VERSION ""

NS_ :

BS_:

BU_: TBOX GW

BO_ 665 BCM_0x299_LIN2_3: 8 GW
 SG_ CSW_Key_StartStop : 1|2@0+ (1,0) [0|3] "" TBOX
 SG_ CSW_Key_AutoParking : 3|2@0+ (1,0) [0|3] "" TBOX
 SG_ CSW_Key_LiftGate : 5|2@0+ (1,0) [0|3] "" TBOX
 SG_ CSW_WindowLOCK : 7|2@0+ (1,0) [0|3] "" TBOX
 SG_ CSW_Key_FrontDefrost : 9|2@0+ (1,0) [0|3] "" TBOX
 SG_ ESCL_DiagError : 12|1@0+ (1,0) [0|1] "" TBOX
 SG_ ESCL_authentification_error : 13|1@0+ (1,0) [0|1] "" TBOX
 SG_ ESCL_unlock_status : 14|1@0+ (1,0) [0|1] "" TBOX
 SG_ ESCL_lock_status : 15|1@0+ (1,0) [0|1] "" TBOX
 SG_ FLWM_WinPstSt : 22|7@0+ (1,0) [0|100] "" TBOX
 SG_ FLWM_AntiPinchDetecte : 23|1@0+ (1,0) [0|1] "" TBOX
 SG_ FRWM_WinPstSt : 30|7@0+ (1,0) [0|100] "" TBOX
 SG_ FRWM_AntiPinchDetecte : 31|1@0+ (1,0) [0|1] "" TBOX
 SG_ RLWM_WinPstSt : 38|7@0+ (1,0) [0|100] "" TBOX
 SG_ RLWM_AntiPinchDetecte : 39|1@0+ (1,0) [0|1] "" TBOX
 SG_ RRWM_WinPstSt : 46|7@0+ (1,0) [0|100] "" TBOX
 SG_ RRWM_AntiPinchDetecte : 47|1@0+ (1,0) [0|1] "" TBOX
 SG_ FLWM_Opend : 48|1@0+ (1,0) [0|1] "" TBOX
 SG_ FLWM_Closed : 49|1@0+ (1,0) [0|1] "" TBOX
 SG_ FRWM_Opend : 50|1@0+ (1,0) [0|1] "" TBOX
 SG_ FRWM_Closed : 51|1@0+ (1,0) [0|1] "" TBOX
 SG_ RLWM_Opend : 52|1@0+ (1,0) [0|1] "" TBOX
 SG_ RLWM_Closed : 53|1@0+ (1,0) [0|1] "" TBOX
 SG_ RRWM_Opend : 54|1@0+ (1,0) [0|1] "" TBOX
 SG_ RRWM_Closed : 55|1@0+ (1,0) [0|1] "" TBOX
 SG_ FLWM_WinMoveSt : 57|2@0+ (1,0) [0|3] "" TBOX
 SG_ FRWM_WinMoveSt : 59|2@0+ (1,0) [0|3] "" TBOX
 SG_ RLWM_WinMoveSt : 61|2@0+ (1,0) [0|3] "" TBOX
 SG_ RRWM_WinMoveSt : 63|2@0+ (1,0) [0|3] "" TBOX

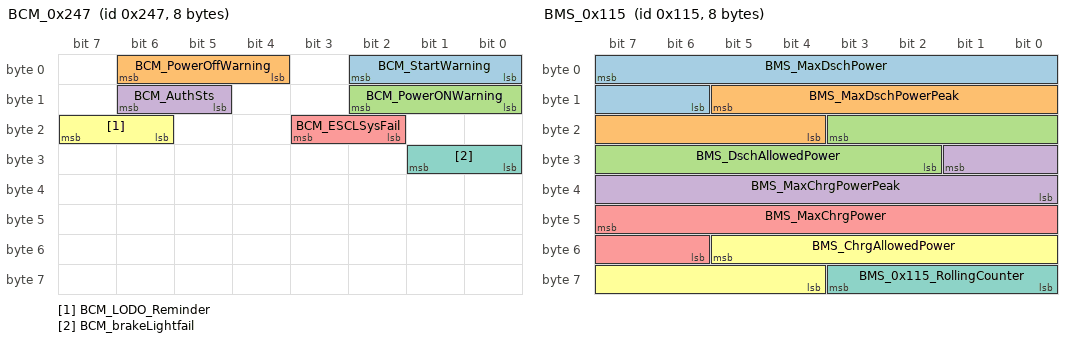
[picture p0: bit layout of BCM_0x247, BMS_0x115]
BO_ 583 BCM_0x247: 8 GW
 SG_ BCM_StartWarning : 2|3@0+ (1,0) [0|7] "" TBOX
 SG_ BCM_PowerOffWarning : 6|3@0+ (1,0) [0|7] "" TBOX
 SG_ BCM_PowerONWarning : 10|3@0+ (1,0) [0|7] "" TBOX
 SG_ BCM_AuthSts : 14|2@0+ (1,0) [0|3] "" TBOX
 SG_ BCM_ESCLSysFail : 19|2@0+ (1,0) [0|3] "" TBOX
 SG_ BCM_LODO_Reminder : 23|2@0+ (1,0) [0|3] "" TBOX
 SG_ BCM_brakeLightfail : 25|2@0+ (1,0) [0|3] "" TBOX

BO_ 1282 BCM_TPMS_0x502: 8 GW
 SG_ TPMS_FL_Warning_Sts : 0|1@0+ (1,0) [0|1] "" TBOX
 SG_ TPMS_FR_Warning_Sts : 1|1@0+ (1,0) [0|1] "" TBOX
 SG_ TPMS_RL_Warning_Sts : 2|1@0+ (1,0) [0|1] "" TBOX
 SG_ TPMS_RR_Warning_Sts : 3|1@0+ (1,0) [0|1] "" TBOX
 SG_ TPMS_FL_Fault_Sts : 4|1@0+ (1,0) [0|1] "" TBOX
 SG_ TPMS_FR_Fault_Sts : 5|1@0+ (1,0) [0|1] "" TBOX
 SG_ TPMS_RL_Fault_Sts : 6|1@0+ (1,0) [0|1] "" TBOX
 SG_ TPMS_RR_Fault_Sts : 7|1@0+ (1,0) [0|1] "" TBOX
 SG_ TPMS_FL_leakage_Sts : 8|1@0+ (1,0) [0|1] "" TBOX
 SG_ TPMS_FR_leakage_Sts : 9|1@0+ (1,0) [0|1] "" TBOX
 SG_ TPMS_RL_leakage_Sts : 10|1@0+ (1,0) [0|1] "" TBOX
 SG_ TPMS_RR_leakage_Sts : 11|1@0+ (1,0) [0|1] "" TBOX
 SG_ TPMS_FLPressure_Sts : 13|2@0+ (1,0) [0|3] "" TBOX
 SG_ TPMS_FRPressure_Sts : 15|2@0+ (1,0) [0|3] "" TBOX
 SG_ TPMS_RLPressure_Sts : 17|2@0+ (1,0) [0|3] "" TBOX
 SG_ TPMS_RRPressure_Sts : 19|2@0+ (1,0) [0|3] "" TBOX
 SG_ TPMS_FL_HighTemp_Sts : 20|1@0+ (1,0) [0|1] "" TBOX
 SG_ TPMS_FR_HighTemp_Sts : 21|1@0+ (1,0) [0|1] "" TBOX
 SG_ TPMS_RL_HighTemp_Sts : 22|1@0+ (1,0) [0|1] "" TBOX
 SG_ TPMS_RR_HighTemp_Sts : 23|1@0+ (1,0) [0|1] "" TBOX
 SG_ TPMS_FL_battery_Sts : 24|1@0+ (1,0) [0|1] "" TBOX
 SG_ TPMS_FR_battery_Sts : 25|1@0+ (1,0) [0|1] "" TBOX
 SG_ TPMS_RL_battery_Sts : 26|1@0+ (1,0) [0|1] "" TBOX
 SG_ TPMS_RR_battery_Sts : 27|1@0+ (1,0) [0|1] "" TBOX
 SG_ TPMS_FL_SensorError_Sts : 28|1@0+ (1,0) [0|1] "" TBOX
 SG_ TPMS_FR_SensorError_Sts : 29|1@0+ (1,0) [0|1] "" TBOX
 SG_ TPMS_RL_SensorError_Sts : 30|1@0+ (1,0) [0|1] "" TBOX
 SG_ TPMS_RR_SensorError_Sts : 31|1@0+ (1,0) [0|1] "" TBOX
 SG_ TPMS_FL_failure_Sts : 32|1@0+ (1,0) [0|1] "" TBOX
 SG_ TPMS_FR_failure_Sts : 33|1@0+ (1,0) [0|1] "" TBOX
 SG_ TPMS_RL_failure_Sts : 34|1@0+ (1,0) [0|1] "" TBOX
 SG_ TPMS_RR_failure_Sts : 35|1@0+ (1,0) [0|1] "" TBOX
 SG_ TPMS_FL_learn_Sts : 41|2@0+ (1,0) [0|3] "" TBOX
 SG_ TPMS_FR_learn_Sts : 43|2@0+ (1,0) [0|3] "" TBOX
 SG_ TPMS_RL_learn_Sts : 45|2@0+ (1,0) [0|3] "" TBOX
 SG_ TPMS_RR_learn_Sts : 47|2@0+ (1,0) [0|3] "" TBOX
 SG_ TPMS_FL_CRC_Error : 48|1@0+ (1,0) [0|1] "" TBOX
 SG_ TPMS_FR_CRC_Error : 49|1@0+ (1,0) [0|1] "" TBOX
 SG_ TPMS_RL_CRC_Error : 50|1@0+ (1,0) [0|1] "" TBOX
 SG_ TPMS_RR_CRC_Error : 52|1@0+ (1,0) [0|1] "" TBOX

BO_ 277 BMS_0x115: 8 GW
 SG_ BMS_MaxDschPower : 7|10@0+ (0.25,0) [0|250] "KW" TBOX
 SG_ BMS_MaxDschPowerPeak : 13|10@0+ (0.25,0) [0|250] "KW" TBOX
 SG_ BMS_DschAllowedPower : 19|10@0+ (0.25,0) [0|250] "KW" TBOX
 SG_ BMS_MaxChrgPowerPeak : 25|10@0+ (0.25,0) [0|250] "KW" TBOX
 SG_ BMS_MaxChrgPower : 47|10@0+ (0.25,0) [0|250] "KW" TBOX
 SG_ BMS_ChrgAllowedPower : 53|10@0+ (0.25,0) [0|250] "KW" TBOX
 SG_ BMS_0x115_RollingCounter : 59|4@0+ (1,0) [0|15] "" TBOX

BO_ 1632 DCDC_0x660: 8 GW
 SG_ DCDC_OverTemp : 1|1@0+ (1,0) [0|1] "" TBOX
 SG_ DCDC_DischargeFail : 2|1@0+ (1,0) [0|1] "" TBOX
 SG_ DCDC_TBOX_WorkSts : 4|2@0+ (1,0) [0|3] "" TBOX
 SG_ DCDC_TBOX_TempFault : 5|1@0+ (1,0) [0|1] "" TBOX
 SG_ DCDC_InsideVolHig : 16|1@0+ (1,0) [0|1] "" TBOX
 SG_ DCDC_InsideVolLow : 17|1@0+ (1,0) [0|1] "" TBOX
 SG_ DCDC_OutputCurHig : 18|1@0+ (1,0) [0|1] "" TBOX
 SG_ DCDC_OutputVolHig : 19|1@0+ (1,0) [0|1] "" TBOX
 SG_ DCDC_OutputVolLow : 20|1@0+ (1,0) [0|1] "" TBOX
 SG_ DCDC_InputCurHig : 21|1@0+ (1,0) [0|1] "" TBOX
 SG_ DCDC_InputVolHig : 22|1@0+ (1,0) [0|1] "" TBOX
 SG_ DCDC_InputVolLow : 23|1@0+ (1,0) [0|1] "" TBOX
 SG_ DCDC_OutputOpen : 26|1@0+ (1,0) [0|1] "" TBOX
 SG_ DCDC_HardFail : 27|1@0+ (1,0) [0|1] "" TBOX
 SG_ DCDC_InsideShotCirc : 28|1@0+ (1,0) [0|1] "" TBOX
 SG_ DCDC_OutputShotCirc : 29|1@0+ (1,0) [0|1] "" TBOX
 SG_ DCDC_CommunTimeOut : 30|1@0+ (1,0) [0|1] "" TBOX
 SG_ DCDC_InsideCurHig : 31|1@0+ (1,0) [0|1] "" TBOX

BO_ 261 BMS_0x105: 8 GW
 SG_ BMS_PackSOH : 6|7@0+ (1,0) [0|100] "%" TBOX
 SG_ BMS_ChrRequestU : 15|13@0+ (0.1,0) [0|800] "V" TBOX
 SG_ BMS_ChrRequest : 18|3@0+ (1,0) [0|7] "" TBOX
 SG_ BMS_ChrRequestI : 31|12@0+ (0.1,0) [0|400] "A" TBOX
 SG_ BMS_VCU_TotalEnergy : 47|19@0+ (1,0) [0|524287] "kwh" TBOX
 SG_ BMS_0x105_RollingCounter : 59|4@0+ (1,0) [0|15] "" TBOX

BO_ 1556 OBC_0x614: 8 GW
 SG_ OBC_ChrgInsOutputVolt : 15|16@0+ (0.1,0) [0|600] "V" TBOX
 SG_ OBC_TempAct : 31|8@0+ (1,-40) [-40|215] "DegC" TBOX
 SG_ OBC_ElockSts : 39|2@0+ (1,0) [0|3] "" TBOX
 SG_ OBC_ChrgLockSts : 37|4@0+ (1,0) [0|7] "" TBOX
 SG_ OBC_RecoTimingSts : 33|1@0+ (1,0) [0|1] "" TBOX

BO_ 1553 OBC_0x611: 8 GW
 SG_ OBC_SocketTempHig : 5|1@0+ (1,0) [0|1] "" TBOX
 SG_ OBC_InputVolLow : 6|1@0+ (1,0) [0|1] "" TBOX
 SG_ OBC_HardTempHig : 7|1@0+ (1,0) [0|1] "" TBOX
 SG_ OBC_OutputShorCir : 8|1@0+ (1,0) [0|1] "" TBOX
 SG_ OBC_OutputVolHig : 9|1@0+ (1,0) [0|1] "" TBOX
 SG_ OBC_OutputVolLow : 10|1@0+ (1,0) [0|1] "" TBOX
 SG_ OBC_PFCOutputVolHig : 11|1@0+ (1,0) [0|1] "" TBOX
 SG_ OBC_PFCOutputVolLow : 12|1@0+ (1,0) [0|1] "" TBOX
 SG_ OBC_CommTimeOut : 13|1@0+ (1,0) [0|1] "" TBOX
 SG_ OBC_InputCurHig : 14|1@0+ (1,0) [0|1] "" TBOX
 SG_ OBC_InputVolHig : 15|1@0+ (1,0) [0|1] "" TBOX
 SG_ OBC_BMSVolLow : 17|1@0+ (1,0) [0|1] "" TBOX
 SG_ OBC_BMSVolHig : 18|1@0+ (1,0) [0|1] "" TBOX
 SG_ OBC_ContraryConnect : 19|1@0+ (1,0) [0|1] "" TBOX
 SG_ OBC_InsideComTimeOut : 20|1@0+ (1,0) [0|1] "" TBOX
 SG_ OBC_ElockFail : 21|1@0+ (1,0) [0|1] "" TBOX
 SG_ OBC_HardFail : 22|1@0+ (1,0) [0|1] "" TBOX
 SG_ OBC_OutputCurHig : 23|1@0+ (1,0) [0|1] "" TBOX
 SG_ OBC_SoketTemp_N : 47|8@0+ (1,-40) [-40|215] "DegC" TBOX
 SG_ OBC_CoolantPlateTemp : 55|8@0+ (1,-55) [-55|200] "DegC" TBOX
 SG_ OBC_SoketTemp_L : 63|8@0+ (1,-40) [-40|215] "DegC" TBOX

BO_ 1552 OBC_0x610: 8 GW
 SG_ Checksum_0x610 : 7|8@0+ (1,0) [0|255] "" TBOX
 SG_ OBC_InputCurrAbility : 15|12@0+ (0.1,0) [0|100] "A" TBOX
 SG_ OBC_ChgInputCurrent : 19|12@0+ (0.1,0) [0|100] "A" TBOX
 SG_ OBC_ChgInputVoltage : 39|14@0+ (0.1,0) [0|500] "V" TBOX
 SG_ OBC_CP_Duty : 55|8@0+ (0.5,0) [0|100] "%" TBOX
 SG_ Rolling_counter_0x610 : 59|4@0+ (1,0) [0|15] "" TBOX
 SG_ OBC_CC_Status : 63|3@0+ (1,0) [0|7] "" TBOX

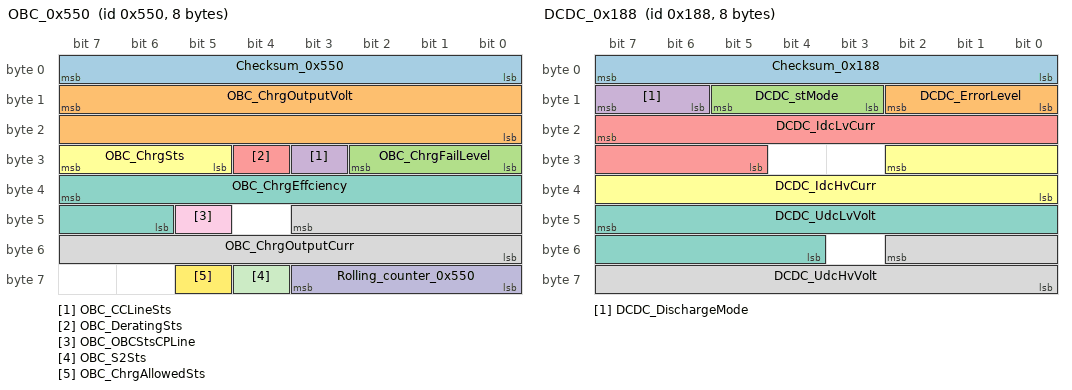
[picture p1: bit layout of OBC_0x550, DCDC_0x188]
BO_ 1360 OBC_0x550: 8 GW
 SG_ Checksum_0x550 : 7|8@0+ (1,0) [0|255] "" TBOX
 SG_ OBC_ChrgOutputVolt : 15|16@0+ (0.1,0) [0|600] "V" TBOX
 SG_ OBC_ChrgFailLevel : 26|3@0+ (1,0) [0|7] "" TBOX
 SG_ OBC_CCLineSts : 27|1@0+ (1,0) [0|1] "" TBOX
 SG_ OBC_DeratingSts : 28|1@0+ (1,0) [0|1] "" TBOX
 SG_ OBC_ChrgSts : 31|3@0+ (1,0) [0|7] "" TBOX
 SG_ OBC_ChrgEffciency : 39|10@0+ (0.001,0) [0|1] "" TBOX
 SG_ OBC_ChrgOutputCurr : 43|12@0+ (0.1,0) [0|40] "" TBOX
 SG_ OBC_OBCStsCPLine : 45|1@0+ (1,0) [0|1] "" TBOX
 SG_ Rolling_counter_0x550 : 59|4@0+ (1,0) [0|15] "" TBOX
 SG_ OBC_S2Sts : 60|1@0+ (1,0) [0|1] "" TBOX
 SG_ OBC_ChrgAllowedSts : 61|1@0+ (1,0) [0|1] "" TBOX

BO_ 392 DCDC_0x188: 8 GW
 SG_ Checksum_0x188 : 7|8@0+ (1,0) [0|255] "" TBOX
 SG_ DCDC_ErrorLevel : 10|3@0+ (1,0) [0|7] "" TBOX
 SG_ DCDC_stMode : 13|3@0+ (1,0) [0|7] "" TBOX
 SG_ DCDC_DischargeMode : 15|2@0+ (1,0) [0|3] "" TBOX
 SG_ DCDC_IdcLvCurr : 23|11@0+ (0.2,0) [0|400] "A" TBOX
 SG_ DCDC_IdcHvCurr : 26|11@0+ (0.1,0) [0|100] "A" TBOX
 SG_ DCDC_UdcLvVolt : 47|12@0+ (0.1,0) [0|40] "V" TBOX
 SG_ DCDC_UdcHvVolt : 50|11@0+ (1,0) [0|600] "V" TBOX

BO_ 905 DCDC_0x389: 8 GW
 SG_ Checksum_0x389 : 7|8@0+ (1,0) [0|255] "" TBOX
 SG_ DCDC_DeratingSts : 12|1@0+ (1,0) [0|1] "" TBOX
 SG_ DCDC_rUtilRateDFM : 24|9@0+ (0.25,0) [0|127.75] "%" TBOX
 SG_ DCDC_TempAct : 47|8@0+ (1,-40) [-40|215] "°C" TBOX
 SG_ Counter_0x389 : 59|4@0+ (1,0) [0|15] "" TBOX

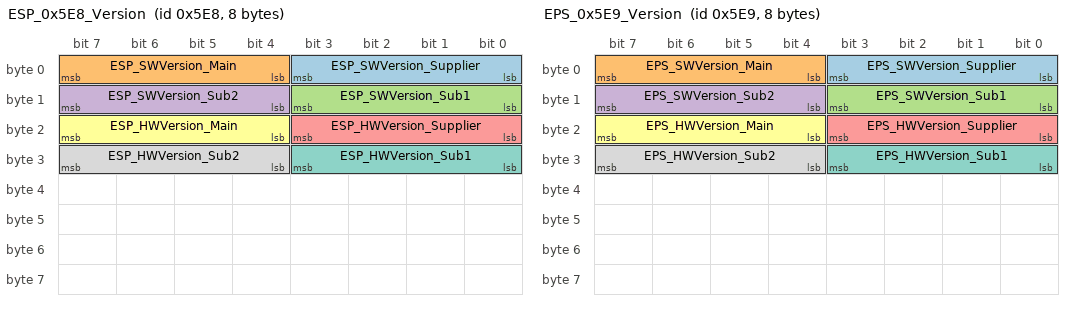
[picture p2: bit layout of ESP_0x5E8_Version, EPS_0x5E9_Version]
BO_ 1512 ESP_0x5E8_Version: 8 GW
 SG_ ESP_SWVersion_Supplier : 3|4@0+ (1,0) [0|15] "" TBOX
 SG_ ESP_SWVersion_Main : 7|4@0+ (1,0) [0|15] "" TBOX
 SG_ ESP_SWVersion_Sub1 : 11|4@0+ (1,0) [0|15] "" TBOX
 SG_ ESP_SWVersion_Sub2 : 15|4@0+ (1,0) [0|15] "" TBOX
 SG_ ESP_HWVersion_Supplier : 19|4@0+ (1,0) [0|15] "" TBOX
 SG_ ESP_HWVersion_Main : 23|4@0+ (1,0) [0|15] "" TBOX
 SG_ ESP_HWVersion_Sub1 : 27|4@0+ (1,0) [0|15] "" TBOX
 SG_ ESP_HWVersion_Sub2 : 31|4@0+ (1,0) [0|15] "" TBOX

BO_ 1513 EPS_0x5E9_Version: 8 GW
 SG_ EPS_SWVersion_Supplier : 3|4@0+ (1,0) [0|15] "" TBOX
 SG_ EPS_SWVersion_Main : 7|4@0+ (1,0) [0|15] "" TBOX
 SG_ EPS_SWVersion_Sub1 : 11|4@0+ (1,0) [0|15] "" TBOX
 SG_ EPS_SWVersion_Sub2 : 15|4@0+ (1,0) [0|15] "" TBOX
 SG_ EPS_HWVersion_Supplier : 19|4@0+ (1,0) [0|15] "" TBOX
 SG_ EPS_HWVersion_Main : 23|4@0+ (1,0) [0|15] "" TBOX
 SG_ EPS_HWVersion_Sub1 : 27|4@0+ (1,0) [0|15] "" TBOX
 SG_ EPS_HWVersion_Sub2 : 31|4@0+ (1,0) [0|15] "" TBOX

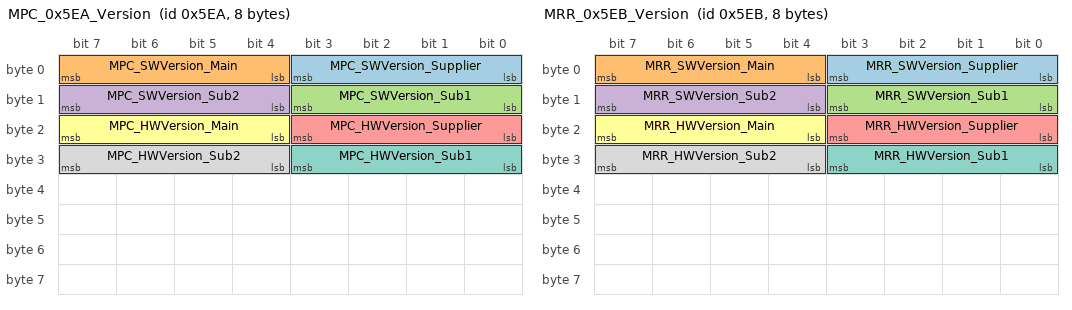
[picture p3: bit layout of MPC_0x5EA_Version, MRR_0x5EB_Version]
BO_ 1514 MPC_0x5EA_Version: 8 GW
 SG_ MPC_SWVersion_Supplier : 3|4@0+ (1,0) [0|15] "" TBOX
 SG_ MPC_SWVersion_Main : 7|4@0+ (1,0) [0|15] "" TBOX
 SG_ MPC_SWVersion_Sub1 : 11|4@0+ (1,0) [0|15] "" TBOX
 SG_ MPC_SWVersion_Sub2 : 15|4@0+ (1,0) [0|15] "" TBOX
 SG_ MPC_HWVersion_Supplier : 19|4@0+ (1,0) [0|15] "" TBOX
 SG_ MPC_HWVersion_Main : 23|4@0+ (1,0) [0|15] "" TBOX
 SG_ MPC_HWVersion_Sub1 : 27|4@0+ (1,0) [0|15] "" TBOX
 SG_ MPC_HWVersion_Sub2 : 31|4@0+ (1,0) [0|15] "" TBOX

BO_ 1515 MRR_0x5EB_Version: 8 GW
 SG_ MRR_SWVersion_Supplier : 3|4@0+ (1,0) [0|15] "" TBOX
 SG_ MRR_SWVersion_Main : 7|4@0+ (1,0) [0|15] "" TBOX
 SG_ MRR_SWVersion_Sub1 : 11|4@0+ (1,0) [0|15] "" TBOX
 SG_ MRR_SWVersion_Sub2 : 15|4@0+ (1,0) [0|15] "" TBOX
 SG_ MRR_HWVersion_Supplier : 19|4@0+ (1,0) [0|15] "" TBOX
 SG_ MRR_HWVersion_Main : 23|4@0+ (1,0) [0|15] "" TBOX
 SG_ MRR_HWVersion_Sub1 : 27|4@0+ (1,0) [0|15] "" TBOX
 SG_ MRR_HWVersion_Sub2 : 31|4@0+ (1,0) [0|15] "" TBOX

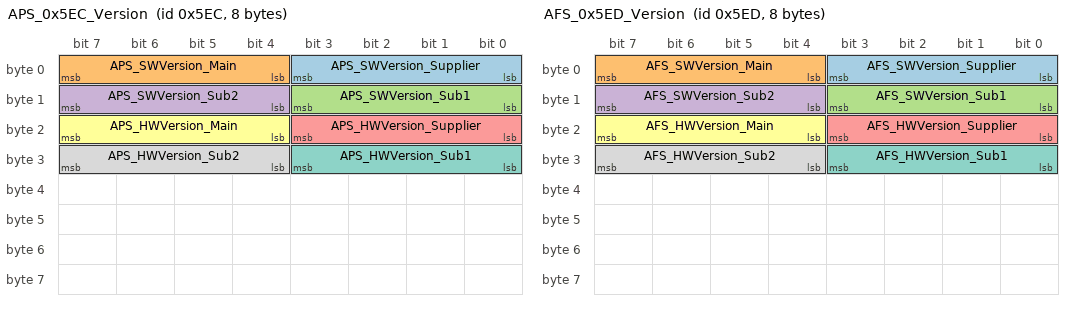
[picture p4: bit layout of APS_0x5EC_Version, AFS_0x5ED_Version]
BO_ 1516 APS_0x5EC_Version: 8 GW
 SG_ APS_SWVersion_Supplier : 3|4@0+ (1,0) [0|15] "" TBOX
 SG_ APS_SWVersion_Main : 7|4@0+ (1,0) [0|15] "" TBOX
 SG_ APS_SWVersion_Sub1 : 11|4@0+ (1,0) [0|15] "" TBOX
 SG_ APS_SWVersion_Sub2 : 15|4@0+ (1,0) [0|15] "" TBOX
 SG_ APS_HWVersion_Supplier : 19|4@0+ (1,0) [0|15] "" TBOX
 SG_ APS_HWVersion_Main : 23|4@0+ (1,0) [0|15] "" TBOX
 SG_ APS_HWVersion_Sub1 : 27|4@0+ (1,0) [0|15] "" TBOX
 SG_ APS_HWVersion_Sub2 : 31|4@0+ (1,0) [0|15] "" TBOX

BO_ 1517 AFS_0x5ED_Version: 8 GW
 SG_ AFS_SWVersion_Supplier : 3|4@0+ (1,0) [0|15] "" TBOX
 SG_ AFS_SWVersion_Main : 7|4@0+ (1,0) [0|15] "" TBOX
 SG_ AFS_SWVersion_Sub1 : 11|4@0+ (1,0) [0|15] "" TBOX
 SG_ AFS_SWVersion_Sub2 : 15|4@0+ (1,0) [0|15] "" TBOX
 SG_ AFS_HWVersion_Supplier : 19|4@0+ (1,0) [0|15] "" TBOX
 SG_ AFS_HWVersion_Main : 23|4@0+ (1,0) [0|15] "" TBOX
 SG_ AFS_HWVersion_Sub1 : 27|4@0+ (1,0) [0|15] "" TBOX
 SG_ AFS_HWVersion_Sub2 : 31|4@0+ (1,0) [0|15] "" TBOX

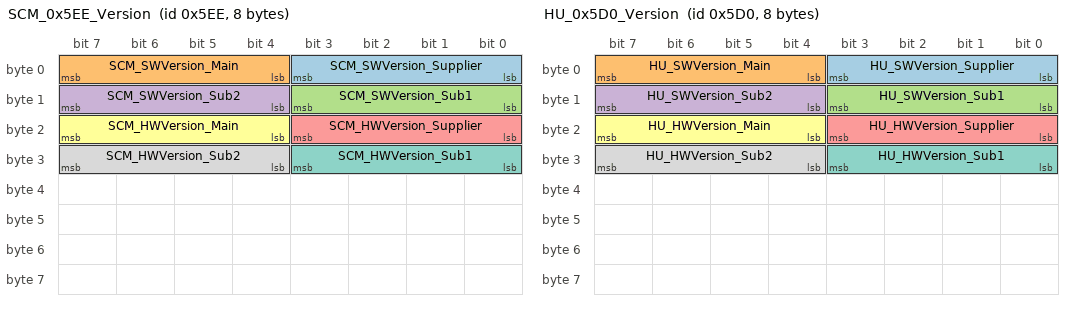
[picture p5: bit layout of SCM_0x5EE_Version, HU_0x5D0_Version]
BO_ 1518 SCM_0x5EE_Version: 8 GW
 SG_ SCM_SWVersion_Supplier : 3|4@0+ (1,0) [0|15] "" TBOX
 SG_ SCM_SWVersion_Main : 7|4@0+ (1,0) [0|15] "" TBOX
 SG_ SCM_SWVersion_Sub1 : 11|4@0+ (1,0) [0|15] "" TBOX
 SG_ SCM_SWVersion_Sub2 : 15|4@0+ (1,0) [0|15] "" TBOX
 SG_ SCM_HWVersion_Supplier : 19|4@0+ (1,0) [0|15] "" TBOX
 SG_ SCM_HWVersion_Main : 23|4@0+ (1,0) [0|15] "" TBOX
 SG_ SCM_HWVersion_Sub1 : 27|4@0+ (1,0) [0|15] "" TBOX
 SG_ SCM_HWVersion_Sub2 : 31|4@0+ (1,0) [0|15] "" TBOX

BO_ 1488 HU_0x5D0_Version: 8 GW
 SG_ HU_SWVersion_Supplier : 3|4@0+ (1,0) [0|15] "" TBOX
 SG_ HU_SWVersion_Main : 7|4@0+ (1,0) [0|15] "" TBOX
 SG_ HU_SWVersion_Sub1 : 11|4@0+ (1,0) [0|15] "" TBOX
 SG_ HU_SWVersion_Sub2 : 15|4@0+ (1,0) [0|15] "" TBOX
 SG_ HU_HWVersion_Supplier : 19|4@0+ (1,0) [0|15] "" TBOX
 SG_ HU_HWVersion_Main : 23|4@0+ (1,0) [0|15] "" TBOX
 SG_ HU_HWVersion_Sub1 : 27|4@0+ (1,0) [0|15] "" TBOX
 SG_ HU_HWVersion_Sub2 : 31|4@0+ (1,0) [0|15] "" TBOX

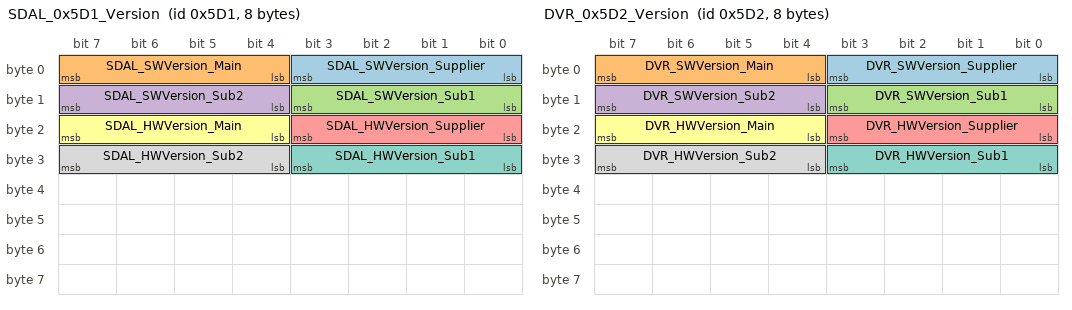
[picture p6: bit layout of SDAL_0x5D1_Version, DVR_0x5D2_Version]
BO_ 1489 SDAL_0x5D1_Version: 8 GW
 SG_ SDAL_SWVersion_Supplier : 3|4@0+ (1,0) [0|15] "" TBOX
 SG_ SDAL_SWVersion_Main : 7|4@0+ (1,0) [0|15] "" TBOX
 SG_ SDAL_SWVersion_Sub1 : 11|4@0+ (1,0) [0|15] "" TBOX
 SG_ SDAL_SWVersion_Sub2 : 15|4@0+ (1,0) [0|15] "" TBOX
 SG_ SDAL_HWVersion_Supplier : 19|4@0+ (1,0) [0|15] "" TBOX
 SG_ SDAL_HWVersion_Main : 23|4@0+ (1,0) [0|15] "" TBOX
 SG_ SDAL_HWVersion_Sub1 : 27|4@0+ (1,0) [0|15] "" TBOX
 SG_ SDAL_HWVersion_Sub2 : 31|4@0+ (1,0) [0|15] "" TBOX

BO_ 1490 DVR_0x5D2_Version: 8 GW
 SG_ DVR_SWVersion_Supplier : 3|4@0+ (1,0) [0|15] "" TBOX
 SG_ DVR_SWVersion_Main : 7|4@0+ (1,0) [0|15] "" TBOX
 SG_ DVR_SWVersion_Sub1 : 11|4@0+ (1,0) [0|15] "" TBOX
 SG_ DVR_SWVersion_Sub2 : 15|4@0+ (1,0) [0|15] "" TBOX
 SG_ DVR_HWVersion_Supplier : 19|4@0+ (1,0) [0|15] "" TBOX
 SG_ DVR_HWVersion_Main : 23|4@0+ (1,0) [0|15] "" TBOX
 SG_ DVR_HWVersion_Sub1 : 27|4@0+ (1,0) [0|15] "" TBOX
 SG_ DVR_HWVersion_Sub2 : 31|4@0+ (1,0) [0|15] "" TBOX

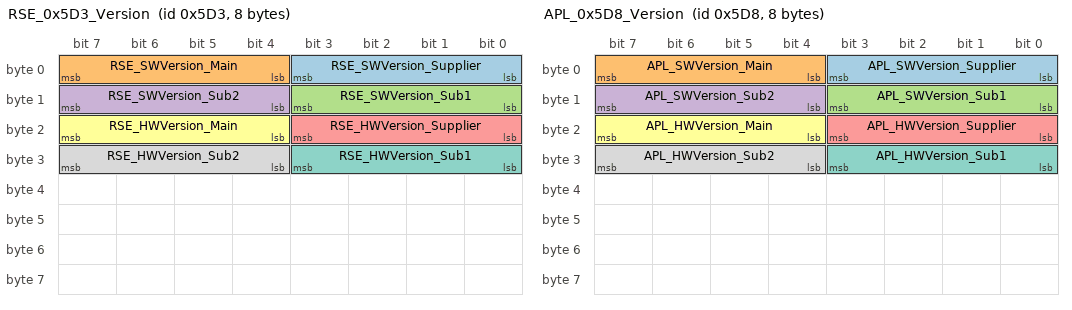
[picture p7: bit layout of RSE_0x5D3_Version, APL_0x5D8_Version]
BO_ 1491 RSE_0x5D3_Version: 8 GW
 SG_ RSE_SWVersion_Supplier : 3|4@0+ (1,0) [0|15] "" TBOX
 SG_ RSE_SWVersion_Main : 7|4@0+ (1,0) [0|15] "" TBOX
 SG_ RSE_SWVersion_Sub1 : 11|4@0+ (1,0) [0|15] "" TBOX
 SG_ RSE_SWVersion_Sub2 : 15|4@0+ (1,0) [0|15] "" TBOX
 SG_ RSE_HWVersion_Supplier : 19|4@0+ (1,0) [0|15] "" TBOX
 SG_ RSE_HWVersion_Main : 23|4@0+ (1,0) [0|15] "" TBOX
 SG_ RSE_HWVersion_Sub1 : 27|4@0+ (1,0) [0|15] "" TBOX
 SG_ RSE_HWVersion_Sub2 : 31|4@0+ (1,0) [0|15] "" TBOX

BO_ 1496 APL_0x5D8_Version: 8 GW
 SG_ APL_SWVersion_Supplier : 3|4@0+ (1,0) [0|15] "" TBOX
 SG_ APL_SWVersion_Main : 7|4@0+ (1,0) [0|15] "" TBOX
 SG_ APL_SWVersion_Sub1 : 11|4@0+ (1,0) [0|15] "" TBOX
 SG_ APL_SWVersion_Sub2 : 15|4@0+ (1,0) [0|15] "" TBOX
 SG_ APL_HWVersion_Supplier : 19|4@0+ (1,0) [0|15] "" TBOX
 SG_ APL_HWVersion_Main : 23|4@0+ (1,0) [0|15] "" TBOX
 SG_ APL_HWVersion_Sub1 : 27|4@0+ (1,0) [0|15] "" TBOX
 SG_ APL_HWVersion_Sub2 : 31|4@0+ (1,0) [0|15] "" TBOX

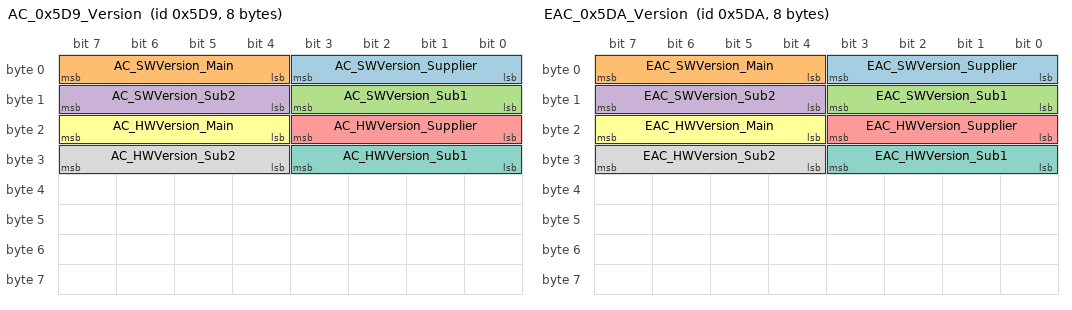
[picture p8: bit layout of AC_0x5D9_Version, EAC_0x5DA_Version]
BO_ 1497 AC_0x5D9_Version: 8 GW
 SG_ AC_SWVersion_Supplier : 3|4@0+ (1,0) [0|15] "" TBOX
 SG_ AC_SWVersion_Main : 7|4@0+ (1,0) [0|15] "" TBOX
 SG_ AC_SWVersion_Sub1 : 11|4@0+ (1,0) [0|15] "" TBOX
 SG_ AC_SWVersion_Sub2 : 15|4@0+ (1,0) [0|15] "" TBOX
 SG_ AC_HWVersion_Supplier : 19|4@0+ (1,0) [0|15] "" TBOX
 SG_ AC_HWVersion_Main : 23|4@0+ (1,0) [0|15] "" TBOX
 SG_ AC_HWVersion_Sub1 : 27|4@0+ (1,0) [0|15] "" TBOX
 SG_ AC_HWVersion_Sub2 : 31|4@0+ (1,0) [0|15] "" TBOX

BO_ 1498 EAC_0x5DA_Version: 8 GW
 SG_ EAC_SWVersion_Supplier : 3|4@0+ (1,0) [0|15] "" TBOX
 SG_ EAC_SWVersion_Main : 7|4@0+ (1,0) [0|15] "" TBOX
 SG_ EAC_SWVersion_Sub1 : 11|4@0+ (1,0) [0|15] "" TBOX
 SG_ EAC_SWVersion_Sub2 : 15|4@0+ (1,0) [0|15] "" TBOX
 SG_ EAC_HWVersion_Supplier : 19|4@0+ (1,0) [0|15] "" TBOX
 SG_ EAC_HWVersion_Main : 23|4@0+ (1,0) [0|15] "" TBOX
 SG_ EAC_HWVersion_Sub1 : 27|4@0+ (1,0) [0|15] "" TBOX
 SG_ EAC_HWVersion_Sub2 : 31|4@0+ (1,0) [0|15] "" TBOX

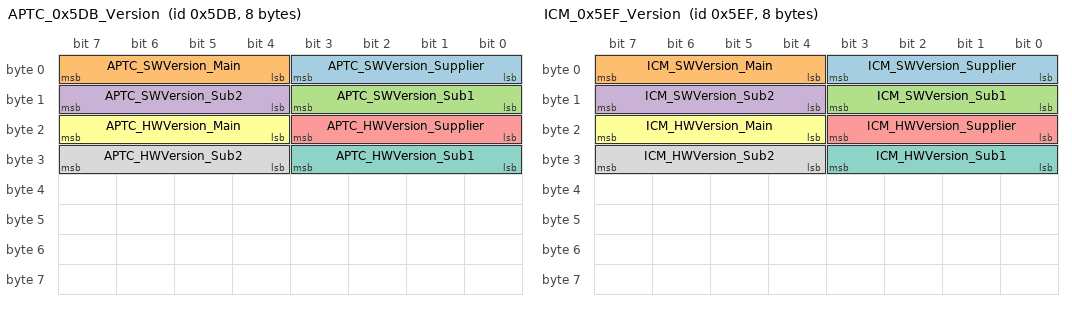
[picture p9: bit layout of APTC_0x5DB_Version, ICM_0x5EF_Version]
BO_ 1499 APTC_0x5DB_Version: 8 GW
 SG_ APTC_SWVersion_Supplier : 3|4@0+ (1,0) [0|15] "" TBOX
 SG_ APTC_SWVersion_Main : 7|4@0+ (1,0) [0|15] "" TBOX
 SG_ APTC_SWVersion_Sub1 : 11|4@0+ (1,0) [0|15] "" TBOX
 SG_ APTC_SWVersion_Sub2 : 15|4@0+ (1,0) [0|15] "" TBOX
 SG_ APTC_HWVersion_Supplier : 19|4@0+ (1,0) [0|15] "" TBOX
 SG_ APTC_HWVersion_Main : 23|4@0+ (1,0) [0|15] "" TBOX
 SG_ APTC_HWVersion_Sub1 : 27|4@0+ (1,0) [0|15] "" TBOX
 SG_ APTC_HWVersion_Sub2 : 31|4@0+ (1,0) [0|15] "" TBOX

BO_ 1519 ICM_0x5EF_Version: 8 GW
 SG_ ICM_SWVersion_Supplier : 3|4@0+ (1,0) [0|15] "" TBOX
 SG_ ICM_SWVersion_Main : 7|4@0+ (1,0) [0|15] "" TBOX
 SG_ ICM_SWVersion_Sub1 : 11|4@0+ (1,0) [0|15] "" TBOX
 SG_ ICM_SWVersion_Sub2 : 15|4@0+ (1,0) [0|15] "" TBOX
 SG_ ICM_HWVersion_Supplier : 19|4@0+ (1,0) [0|15] "" TBOX
 SG_ ICM_HWVersion_Main : 23|4@0+ (1,0) [0|15] "" TBOX
 SG_ ICM_HWVersion_Sub1 : 27|4@0+ (1,0) [0|15] "" TBOX
 SG_ ICM_HWVersion_Sub2 : 31|4@0+ (1,0) [0|15] "" TBOX

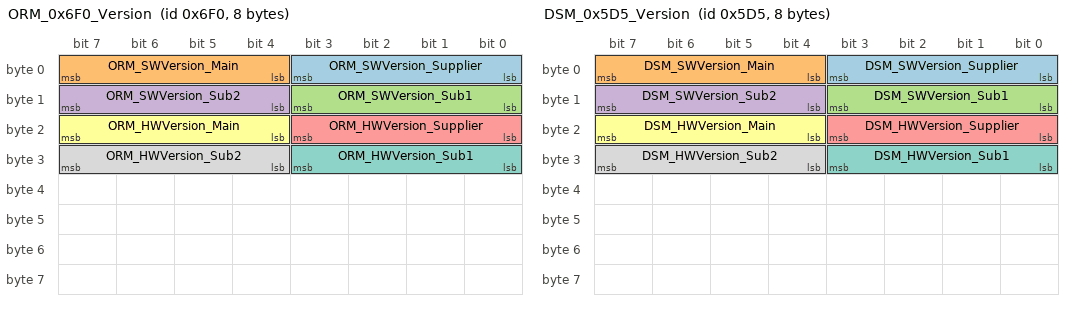
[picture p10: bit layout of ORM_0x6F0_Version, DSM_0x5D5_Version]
BO_ 1776 ORM_0x6F0_Version: 8 GW
 SG_ ORM_SWVersion_Supplier : 3|4@0+ (1,0) [0|15] "" TBOX
 SG_ ORM_SWVersion_Main : 7|4@0+ (1,0) [0|15] "" TBOX
 SG_ ORM_SWVersion_Sub1 : 11|4@0+ (1,0) [0|15] "" TBOX
 SG_ ORM_SWVersion_Sub2 : 15|4@0+ (1,0) [0|15] "" TBOX
 SG_ ORM_HWVersion_Supplier : 19|4@0+ (1,0) [0|15] "" TBOX
 SG_ ORM_HWVersion_Main : 23|4@0+ (1,0) [0|15] "" TBOX
 SG_ ORM_HWVersion_Sub1 : 27|4@0+ (1,0) [0|15] "" TBOX
 SG_ ORM_HWVersion_Sub2 : 31|4@0+ (1,0) [0|15] "" TBOX

BO_ 1493 DSM_0x5D5_Version: 8 GW
 SG_ DSM_SWVersion_Supplier : 3|4@0+ (1,0) [10|15] "" TBOX
 SG_ DSM_SWVersion_Main : 7|4@0+ (1,0) [10|15] "" TBOX
 SG_ DSM_SWVersion_Sub1 : 11|4@0+ (1,0) [0|15] "" TBOX
 SG_ DSM_SWVersion_Sub2 : 15|4@0+ (1,0) [0|15] "" TBOX
 SG_ DSM_HWVersion_Supplier : 19|4@0+ (1,0) [10|15] "" TBOX
 SG_ DSM_HWVersion_Main : 23|4@0+ (1,0) [10|15] "" TBOX
 SG_ DSM_HWVersion_Sub1 : 27|4@0+ (1,0) [0|15] "" TBOX
 SG_ DSM_HWVersion_Sub2 : 31|4@0+ (1,0) [0|15] "" TBOX

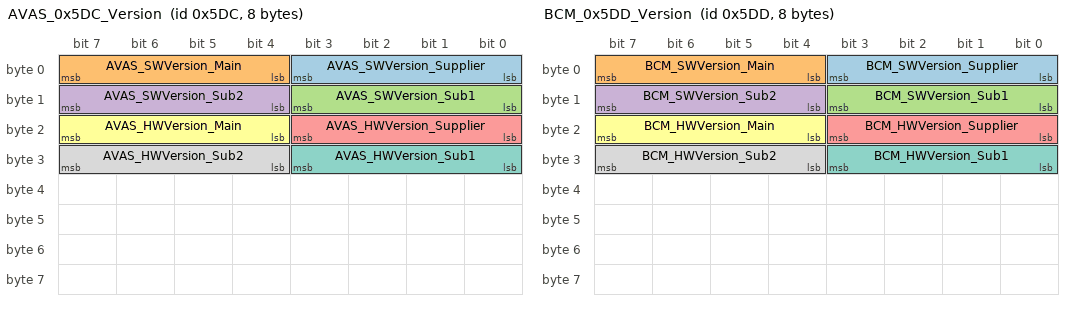
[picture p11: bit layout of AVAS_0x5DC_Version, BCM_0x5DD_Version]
BO_ 1500 AVAS_0x5DC_Version: 8 GW
 SG_ AVAS_SWVersion_Supplier : 3|4@0+ (1,0) [10|15] "" TBOX
 SG_ AVAS_SWVersion_Main : 7|4@0+ (1,0) [10|15] "" TBOX
 SG_ AVAS_SWVersion_Sub1 : 11|4@0+ (1,0) [0|15] "" TBOX
 SG_ AVAS_SWVersion_Sub2 : 15|4@0+ (1,0) [0|15] "" TBOX
 SG_ AVAS_HWVersion_Supplier : 19|4@0+ (1,0) [10|15] "" TBOX
 SG_ AVAS_HWVersion_Main : 23|4@0+ (1,0) [10|15] "" TBOX
 SG_ AVAS_HWVersion_Sub1 : 27|4@0+ (1,0) [0|15] "" TBOX
 SG_ AVAS_HWVersion_Sub2 : 31|4@0+ (1,0) [0|15] "" TBOX

BO_ 1501 BCM_0x5DD_Version: 8 GW
 SG_ BCM_SWVersion_Supplier : 3|4@0+ (1,0) [10|15] "" TBOX
 SG_ BCM_SWVersion_Main : 7|4@0+ (1,0) [10|15] "" TBOX
 SG_ BCM_SWVersion_Sub1 : 11|4@0+ (1,0) [0|15] "" TBOX
 SG_ BCM_SWVersion_Sub2 : 15|4@0+ (1,0) [0|15] "" TBOX
 SG_ BCM_HWVersion_Supplier : 19|4@0+ (1,0) [10|15] "" TBOX
 SG_ BCM_HWVersion_Main : 23|4@0+ (1,0) [10|15] "" TBOX
 SG_ BCM_HWVersion_Sub1 : 27|4@0+ (1,0) [0|15] "" TBOX
 SG_ BCM_HWVersion_Sub2 : 31|4@0+ (1,0) [0|15] "" TBOX

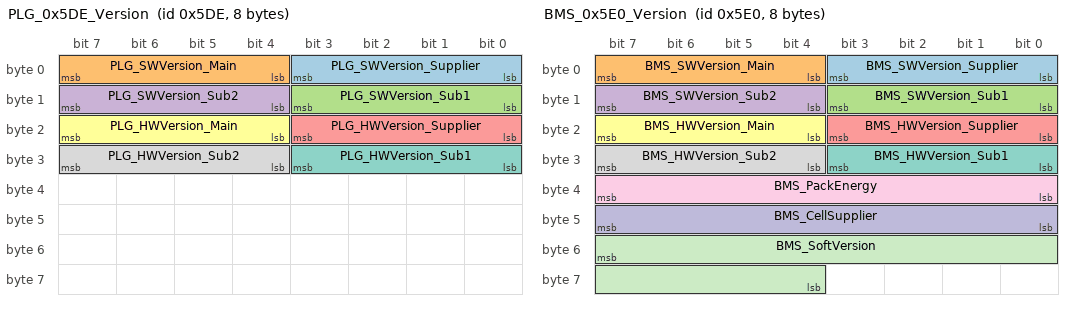
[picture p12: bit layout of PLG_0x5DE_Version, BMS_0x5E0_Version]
BO_ 1502 PLG_0x5DE_Version: 8 GW
 SG_ PLG_SWVersion_Supplier : 3|4@0+ (1,0) [10|15] "" TBOX
 SG_ PLG_SWVersion_Main : 7|4@0+ (1,0) [10|15] "" TBOX
 SG_ PLG_SWVersion_Sub1 : 11|4@0+ (1,0) [0|15] "" TBOX
 SG_ PLG_SWVersion_Sub2 : 15|4@0+ (1,0) [0|15] "" TBOX
 SG_ PLG_HWVersion_Supplier : 19|4@0+ (1,0) [10|15] "" TBOX
 SG_ PLG_HWVersion_Main : 23|4@0+ (1,0) [10|15] "" TBOX
 SG_ PLG_HWVersion_Sub1 : 27|4@0+ (1,0) [0|15] "" TBOX
 SG_ PLG_HWVersion_Sub2 : 31|4@0+ (1,0) [0|15] "" TBOX

BO_ 1504 BMS_0x5E0_Version: 8 GW
 SG_ BMS_SWVersion_Supplier : 3|4@0+ (1,0) [10|15] "" TBOX
 SG_ BMS_SWVersion_Main : 7|4@0+ (1,0) [10|15] "" TBOX
 SG_ BMS_SWVersion_Sub1 : 11|4@0+ (1,0) [0|15] "" TBOX
 SG_ BMS_SWVersion_Sub2 : 15|4@0+ (1,0) [0|15] "" TBOX
 SG_ BMS_HWVersion_Supplier : 19|4@0+ (1,0) [10|15] "" TBOX
 SG_ BMS_HWVersion_Main : 23|4@0+ (1,0) [10|15] "" TBOX
 SG_ BMS_HWVersion_Sub1 : 27|4@0+ (1,0) [0|15] "" TBOX
 SG_ BMS_HWVersion_Sub2 : 31|4@0+ (1,0) [0|15] "" TBOX
 SG_ BMS_PackEnergy : 39|8@0+ (1,0) [0|255] "kWh" TBOX
 SG_ BMS_CellSupplier : 47|8@0+ (1,0) [0|255] "" TBOX
 SG_ BMS_SoftVersion : 55|12@0+ (1,0) [0|4000] "" TBOX

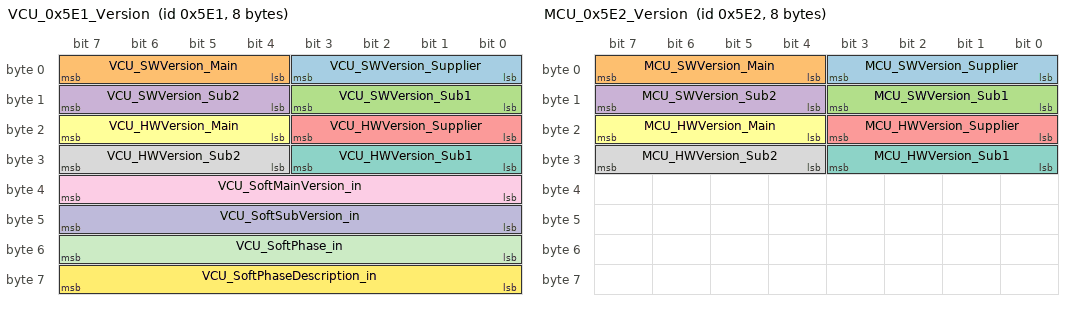
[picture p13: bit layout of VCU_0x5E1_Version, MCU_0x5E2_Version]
BO_ 1505 VCU_0x5E1_Version: 8 GW
 SG_ VCU_SWVersion_Supplier : 3|4@0+ (1,0) [10|15] "" TBOX
 SG_ VCU_SWVersion_Main : 7|4@0+ (1,0) [10|15] "" TBOX
 SG_ VCU_SWVersion_Sub1 : 11|4@0+ (1,0) [0|15] "" TBOX
 SG_ VCU_SWVersion_Sub2 : 15|4@0+ (1,0) [0|15] "" TBOX
 SG_ VCU_HWVersion_Supplier : 19|4@0+ (1,0) [10|15] "" TBOX
 SG_ VCU_HWVersion_Main : 23|4@0+ (1,0) [10|15] "" TBOX
 SG_ VCU_HWVersion_Sub1 : 27|4@0+ (1,0) [0|15] "" TBOX
 SG_ VCU_HWVersion_Sub2 : 31|4@0+ (1,0) [0|15] "" TBOX
 SG_ VCU_SoftMainVersion_in : 39|8@0+ (1,0) [0|255] "" TBOX
 SG_ VCU_SoftSubVersion_in : 47|8@0+ (1,0) [0|255] "" TBOX
 SG_ VCU_SoftPhase_in : 55|8@0+ (1,0) [0|255] "" TBOX
 SG_ VCU_SoftPhaseDescription_in : 63|8@0+ (1,0) [0|255] "" TBOX

BO_ 1506 MCU_0x5E2_Version: 8 GW
 SG_ MCU_SWVersion_Supplier : 3|4@0+ (1,0) [10|15] "" TBOX
 SG_ MCU_SWVersion_Main : 7|4@0+ (1,0) [10|15] "" TBOX
 SG_ MCU_SWVersion_Sub1 : 11|4@0+ (1,0) [0|15] "" TBOX
 SG_ MCU_SWVersion_Sub2 : 15|4@0+ (1,0) [0|15] "" TBOX
 SG_ MCU_HWVersion_Supplier : 19|4@0+ (1,0) [10|15] "" TBOX
 SG_ MCU_HWVersion_Main : 23|4@0+ (1,0) [10|15] "" TBOX
 SG_ MCU_HWVersion_Sub1 : 27|4@0+ (1,0) [0|15] "" TBOX
 SG_ MCU_HWVersion_Sub2 : 31|4@0+ (1,0) [0|15] "" TBOX

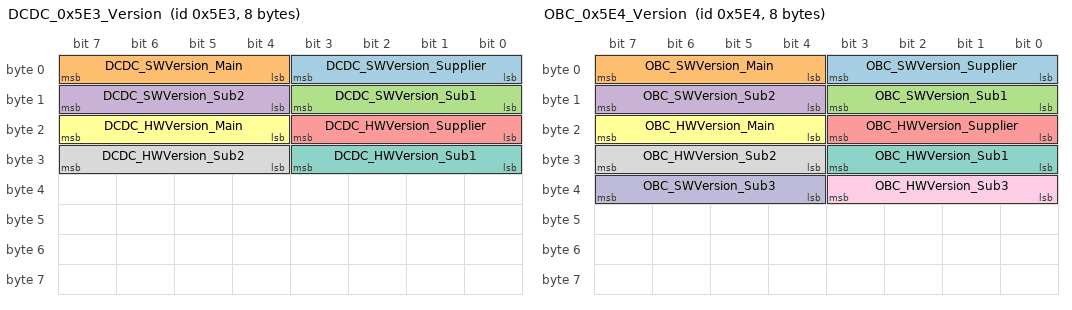
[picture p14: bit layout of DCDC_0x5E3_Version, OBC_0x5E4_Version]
BO_ 1507 DCDC_0x5E3_Version: 8 GW
 SG_ DCDC_SWVersion_Supplier : 3|4@0+ (1,0) [10|15] "" TBOX
 SG_ DCDC_SWVersion_Main : 7|4@0+ (1,0) [10|15] "" TBOX
 SG_ DCDC_SWVersion_Sub1 : 11|4@0+ (1,0) [0|15] "" TBOX
 SG_ DCDC_SWVersion_Sub2 : 15|4@0+ (1,0) [0|15] "" TBOX
 SG_ DCDC_HWVersion_Supplier : 19|4@0+ (1,0) [10|15] "" TBOX
 SG_ DCDC_HWVersion_Main : 23|4@0+ (1,0) [10|15] "" TBOX
 SG_ DCDC_HWVersion_Sub1 : 27|4@0+ (1,0) [0|15] "" TBOX
 SG_ DCDC_HWVersion_Sub2 : 31|4@0+ (1,0) [0|15] "" TBOX

BO_ 1508 OBC_0x5E4_Version: 8 GW
 SG_ OBC_SWVersion_Supplier : 3|4@0+ (1,0) [10|15] "" TBOX
 SG_ OBC_SWVersion_Main : 7|4@0+ (1,0) [10|15] "" TBOX
 SG_ OBC_SWVersion_Sub1 : 11|4@0+ (1,0) [0|15] "" TBOX
 SG_ OBC_SWVersion_Sub2 : 15|4@0+ (1,0) [0|15] "" TBOX
 SG_ OBC_HWVersion_Supplier : 19|4@0+ (1,0) [10|15] "" TBOX
 SG_ OBC_HWVersion_Main : 23|4@0+ (1,0) [10|15] "" TBOX
 SG_ OBC_HWVersion_Sub1 : 27|4@0+ (1,0) [0|15] "" TBOX
 SG_ OBC_HWVersion_Sub2 : 31|4@0+ (1,0) [0|15] "" TBOX
 SG_ OBC_HWVersion_Sub3 : 35|4@0+ (1,0) [0|15] "" TBOX
 SG_ OBC_SWVersion_Sub3 : 39|4@0+ (1,0) [0|15] "" TBOX

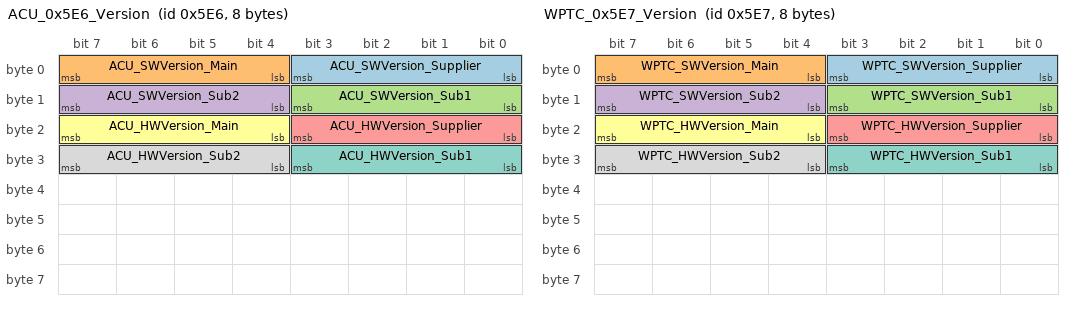
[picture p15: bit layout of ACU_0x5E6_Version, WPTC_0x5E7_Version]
BO_ 1510 ACU_0x5E6_Version: 8 GW
 SG_ ACU_SWVersion_Supplier : 3|4@0+ (1,0) [10|15] "" TBOX
 SG_ ACU_SWVersion_Main : 7|4@0+ (1,0) [10|15] "" TBOX
 SG_ ACU_SWVersion_Sub1 : 11|4@0+ (1,0) [0|15] "" TBOX
 SG_ ACU_SWVersion_Sub2 : 15|4@0+ (1,0) [0|15] "" TBOX
 SG_ ACU_HWVersion_Supplier : 19|4@0+ (1,0) [10|15] "" TBOX
 SG_ ACU_HWVersion_Main : 23|4@0+ (1,0) [10|15] "" TBOX
 SG_ ACU_HWVersion_Sub1 : 27|4@0+ (1,0) [0|15] "" TBOX
 SG_ ACU_HWVersion_Sub2 : 31|4@0+ (1,0) [0|15] "" TBOX

BO_ 1511 WPTC_0x5E7_Version: 8 GW
 SG_ WPTC_SWVersion_Supplier : 3|4@0+ (1,0) [10|15] "" TBOX
 SG_ WPTC_SWVersion_Main : 7|4@0+ (1,0) [10|15] "" TBOX
 SG_ WPTC_SWVersion_Sub1 : 11|4@0+ (1,0) [0|15] "" TBOX
 SG_ WPTC_SWVersion_Sub2 : 15|4@0+ (1,0) [0|15] "" TBOX
 SG_ WPTC_HWVersion_Supplier : 19|4@0+ (1,0) [10|15] "" TBOX
 SG_ WPTC_HWVersion_Main : 23|4@0+ (1,0) [10|15] "" TBOX
 SG_ WPTC_HWVersion_Sub1 : 27|4@0+ (1,0) [0|15] "" TBOX
 SG_ WPTC_HWVersion_Sub2 : 31|4@0+ (1,0) [0|15] "" TBOX

BO_ 804 MCU_0x324: 8 GW
 SG_ MCU_FailCode1 : 7|16@0+ (1,0) [0|65535] "" TBOX
 SG_ MCU_FailCode2 : 23|16@0+ (1,0) [0|65535] "" TBOX
 SG_ MCU_FailCode3 : 39|16@0+ (1,0) [0|65535] "" TBOX
 SG_ MCU_FailCode4 : 55|16@0+ (1,0) [0|65535] "" TBOX

BO_ 835 PLG_0x343: 8 GW
 SG_ PLG_Trunk_Sts : 2|3@0+ (1,0) [0|7] "" TBOX
 SG_ PLG_Shutface_SW : 3|1@0+ (1,0) [0|1] "" TBOX
 SG_ PLG_Latc_PawlSW : 4|1@0+ (1,0) [0|1] "" TBOX
 SG_ PLG_Latch_SecondarySW : 5|1@0+ (1,0) [0|1] "" TBOX
 SG_ PLG_Latch_0PositionSW : 6|1@0+ (1,0) [0|1] "" TBOX
 SG_ PLG_LearnedSts : 7|1@0+ (1,0) [0|1] "" TBOX
 SG_ PLG_KickActiveReq : 8|1@0+ (1,0) [0|1] "" TBOX
 SG_ PLG_HallSensor : 12|1@0+ (1,0) [0|1] "" TBOX
 SG_ PLG_OpenAng : 22|7@0+ (1,0) [0|100] "%" TBOX
 SG_ PLG_OpenAngValid : 23|1@0+ (1,0) [0|1] "" TBOX
 SG_ PLG_GaragePosition : 30|7@0+ (1,0) [0|100] "%" TBOX
 SG_ PLG_LatchMorSts : 33|2@0+ (1,0) [0|3] "" TBOX
 SG_ PLG_GearMor1Sts : 35|2@0+ (1,0) [0|3] "" TBOX
 SG_ PLG_GearMor2Sts : 37|2@0+ (1,0) [0|3] "" TBOX
 SG_ PLG_mode : 39|2@0+ (1,0) [0|3] "" TBOX
 SG_ PLG_TBOXUnlockEnableSts : 40|1@0+ (1,0) [0|1] "" TBOX
 SG_ PLG_Fault : 41|1@0+ (1,0) [0|1] "" TBOX
 SG_ PLG_FaultSts : 44|3@0+ (1,0) [0|7] "" TBOX

BO_ 774 BMS_0x306: 8 GW
 SG_ BMS_RemainChargingTime : 7|10@0+ (1,0) [0|1000] "min" TBOX
 SG_ BMS_Charing_Time : 13|10@0+ (1,0) [0|1000] "min" TBOX
 SG_ BMS_Charging_Ah : 16|9@0+ (0.5,0) [0|250] "Ah" TBOX
 SG_ BMS_TotalCharging_Ah : 35|20@0+ (1,0) [0|500000] "Ah" TBOX
 SG_ BMS_Charging_Energy : 63|8@0+ (0.5,0) [0|125] "kwh" TBOX

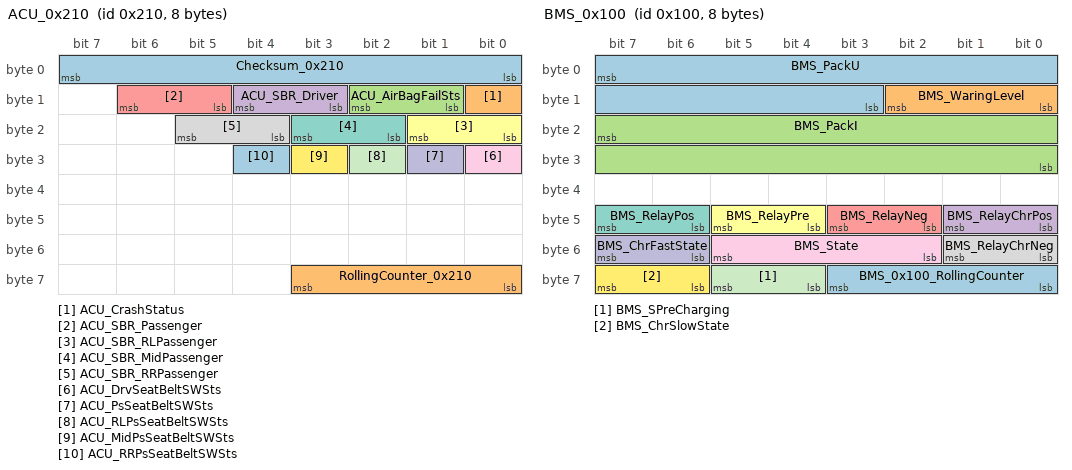
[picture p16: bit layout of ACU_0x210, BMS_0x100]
BO_ 528 ACU_0x210: 8 GW
 SG_ Checksum_0x210 : 7|8@0+ (1,0) [0|255] "" TBOX
 SG_ ACU_CrashStatus : 8|1@0+ (1,0) [0|1] "" TBOX
 SG_ ACU_AirBagFailSts : 10|2@0+ (1,0) [0|3] "" TBOX
 SG_ ACU_SBR_Driver : 12|2@0+ (1,0) [0|3] "" TBOX
 SG_ ACU_SBR_Passenger : 14|2@0+ (1,0) [0|3] "" TBOX
 SG_ ACU_SBR_RLPassenger : 17|2@0+ (1,0) [0|3] "" TBOX
 SG_ ACU_SBR_MidPassenger : 19|2@0+ (1,0) [0|3] "" TBOX
 SG_ ACU_SBR_RRPassenger : 21|2@0+ (1,0) [0|3] "" TBOX
 SG_ ACU_DrvSeatBeltSWSts : 24|1@0+ (1,0) [0|1] "" TBOX
 SG_ ACU_PsSeatBeltSWSts : 25|1@0+ (1,0) [0|1] "" TBOX
 SG_ ACU_RLPsSeatBeltSWSts : 26|1@0+ (1,0) [0|1] "" TBOX
 SG_ ACU_MidPsSeatBeltSWSts : 27|1@0+ (1,0) [0|1] "" TBOX
 SG_ ACU_RRPsSeatBeltSWSts : 28|1@0+ (1,0) [0|1] "" TBOX
 SG_ RollingCounter_0x210 : 59|4@0+ (1,0) [0|15] "" TBOX

BO_ 596 AC_0x254: 8 GW
 SG_ AC_SystemSts : 0|1@0+ (1,0) [0|1] "" TBOX
 SG_ AC_CycleSts : 1|1@0+ (1,0) [0|1] "" TBOX
 SG_ AC_EACSts : 2|1@0+ (1,0) [0|1] "" TBOX
 SG_ AC_AutoModeSts : 3|1@0+ (1,0) [0|1] "" TBOX
 SG_ AC_APTC_StartStop : 5|2@0+ (1,0) [0|3] "" TBOX
 SG_ AC_StartStopEAC : 7|2@0+ (1,0) [0|3] "" TBOX
 SG_ AC_EAC_AimSpeed : 15|16@0+ (1,0) [0|65534] "" TBOX
 SG_ AC_WindModeSts : 26|3@0+ (1,0) [0|7] "" TBOX
 SG_ AC_BlowingRateSts : 29|3@0+ (1,0) [0|7] "" TBOX
 SG_ AC_APTCSWsts : 30|1@0+ (1,0) [0|1] "" TBOX
 SG_ AC_SysFaultsts : 31|1@0+ (1,0) [0|1] "" TBOX
 SG_ AC_InTemperature : 39|8@0+ (0.5,-40) [-40|80] "℃" TBOX
 SG_ AC_OutTemperature : 47|8@0+ (0.5,-40) [-40|80] "℃" TBOX
 SG_ AC_PM25Value : 55|10@0+ (1,0) [0|1023] "μg/m3" TBOX
 SG_ AC_BatCoolingValve : 56|1@0+ (1,0) [0|1] "" TBOX
 SG_ AC_ComftCoolingValve : 57|1@0+ (1,0) [0|1] "" TBOX
 SG_ AC_FdefrostSts : 58|1@0+ (1,0) [0|1] "" TBOX

BO_ 1009 DVR_0x3F1: 8 GW
 SG_ DVR_Sdcard_Sts : 2|3@0+ (1,0) [0|7] "" TBOX
 SG_ DVR_DrivingRecord : 3|1@0+ (1,0) [0|1] "" TBOX
 SG_ DVR_VideoResolution : 5|2@0+ (1,0) [0|3] "" TBOX
 SG_ DVR_VideoTimeSts : 7|2@0+ (1,0) [0|3] "" TBOX
 SG_ DVR_ShutdownDelay : 9|2@0+ (1,0) [0|3] "" TBOX
 SG_ DVR_VideoCoverageSW : 10|1@0+ (1,0) [0|1] "" TBOX
 SG_ DVR_GSensorSensy : 12|2@0+ (1,0) [0|3] "" TBOX
 SG_ DVR_ParkMonitor : 13|1@0+ (1,0) [0|1] "" TBOX
 SG_ DVR_TapeSwitch : 14|1@0+ (1,0) [0|1] "" TBOX
 SG_ DVR_HDRSwitch : 15|1@0+ (1,0) [0|1] "" TBOX
 SG_ DVR_DriveInfoOverlay : 16|1@0+ (1,0) [0|1] "" TBOX
 SG_ DVR_SdcardFormateSts : 18|2@0+ (1,0) [0|3] "" TBOX
 SG_ DVR_FactoryDefaultSts : 20|2@0+ (1,0) [0|3] "" TBOX
 SG_ DVR_SystemSts : 21|1@0+ (1,0) [0|1] "" TBOX
 SG_ DVR_ControlResult : 23|2@0+ (1,0) [0|3] "" TBOX
 SG_ DVR_GsensorCrashStatus : 24|1@0+ (1,0) [0|1] "" TBOX
 SG_ DVR_requestWiFiopen : 25|1@0+ (1,0) [0|1] "" TBOX
 SG_ DVR_Network_Set : 27|2@0+ (1,0) [0|3] "" TBOX
 SG_ DVR_LocalPhotographResult : 29|2@0+ (1,0) [0|3] "" TBOX
 SG_ DVR_LocalRecordResult : 31|2@0+ (1,0) [0|3] "" TBOX
 SG_ DVR_Frameinterval : 39|8@0+ (1,0) [0|255] "" TBOX
 SG_ DVR_FrameCount : 42|11@0+ (1,0) [0|2047] "" TBOX
 SG_ DVR_PlayRate : 47|5@0+ (1,0) [0|31] "" TBOX
 SG_ DVR_LocalTimelapseRecordResult : 57|2@0+ (1,0) [0|3] "" TBOX

BO_ 676 DSM_0x2A4: 8 GW
 SG_ DSM_EasyEntrySWSts : 0|1@0+ (1,0) [0|1] "" TBOX
 SG_ DSM_DSMHeatSWsts : 1|1@0+ (1,0) [0|1] "" TBOX
 SG_ DSM_MemoryAlarm : 3|2@0+ (1,0) [0|3] "" TBOX
 SG_ DSM_DeleteMemoryRsp : 5|2@0+ (1,0) [0|3] "" TBOX
 SG_ DSM_GetMemoryRsp : 7|2@0+ (1,0) [0|3] "" TBOX
 SG_ DSM_DseatMemoryPosition : 11|4@0+ (1,0) [0|15] "" TBOX
 SG_ DSM_SLV_DirectionSts : 13|2@0+ (1,0) [0|3] "" TBOX
 SG_ DSM_SHV_DirectionSts : 15|2@0+ (1,0) [0|3] "" TBOX
 SG_ DSM_LNV_DirectionSts : 17|2@0+ (1,0) [0|3] "" TBOX
 SG_ DSM_SLV_CalibrationSts : 19|2@0+ (1,0) [0|3] "" TBOX
 SG_ DSM_SHV_CalibrationSts : 21|2@0+ (1,0) [0|3] "" TBOX
 SG_ DSM_LNV_CalibrationSts : 23|2@0+ (1,0) [0|3] "" TBOX
 SG_ DSM_DSLV_MotorfaultSts : 24|1@0+ (1,0) [0|1] "" TBOX
 SG_ DSM_SLV_Position : 31|7@0+ (1,0) [0|100] "%" TBOX
 SG_ DSM_DSHV_MotorfaultSts : 32|1@0+ (1,0) [0|1] "" TBOX
 SG_ DSM_SHV_Position : 39|7@0+ (1,0) [0|100] "%" TBOX
 SG_ DSM_DSNV_MotorfaultSts : 40|1@0+ (1,0) [0|1] "" TBOX
 SG_ DSM_LNV_Position : 47|7@0+ (1,0) [0|100] "%" TBOX
 SG_ DSM_PSMHeatfault : 48|1@0+ (1,0) [0|1] "" TBOX
 SG_ DSM_PSMHeatSWsts : 49|1@0+ (1,0) [0|1] "" TBOX
 SG_ DSM_PSMheattemp : 55|6@0+ (1,0) [0|50] "℃" TBOX
 SG_ DSM_DSMHeatfault : 56|1@0+ (1,0) [0|1] "" TBOX
 SG_ DSM_DSMheattemp : 63|6@0+ (1,0) [0|50] "℃" TBOX

BO_ 24 BCM_AuthReq_0x18: 8 GW
 SG_ BCM_AuthReq_TBOX_NSM_Code : 7|64@0+ (1,0) [0|255] "" TBOX

BO_ 25 TBOX_AuthResp_0x19: 8 TBOX
 SG_ TBOX_AuthResp_BCM_Code : 7|64@0+ (1,0) [0|255] "" GW

BO_ 256 BMS_0x100: 8 GW
 SG_ BMS_PackU : 7|13@0+ (0.1,0) [0|800] "V" TBOX
 SG_ BMS_WaringLevel : 10|3@0+ (1,0) [0|7] "" TBOX
 SG_ BMS_PackI : 23|16@0+ (0.1,-1000) [-1000|1000] "A" TBOX
 SG_ BMS_RelayChrPos : 41|2@0+ (1,0) [0|3] "" TBOX
 SG_ BMS_RelayNeg : 43|2@0+ (1,0) [0|3] "" TBOX
 SG_ BMS_RelayPre : 45|2@0+ (1,0) [0|3] "" TBOX
 SG_ BMS_RelayPos : 47|2@0+ (1,0) [0|3] "" TBOX
 SG_ BMS_RelayChrNeg : 49|2@0+ (1,0) [0|3] "" TBOX
 SG_ BMS_State : 53|4@0+ (1,0) [0|15] "" TBOX
 SG_ BMS_ChrFastState : 55|2@0+ (1,0) [0|3] "" TBOX
 SG_ BMS_SPreCharging : 61|2@0+ (1,0) [0|3] "" TBOX
 SG_ BMS_ChrSlowState : 63|2@0+ (1,0) [0|3] "" TBOX
 SG_ BMS_0x100_RollingCounter : 59|4@0+ (1,0) [0|15] "" TBOX

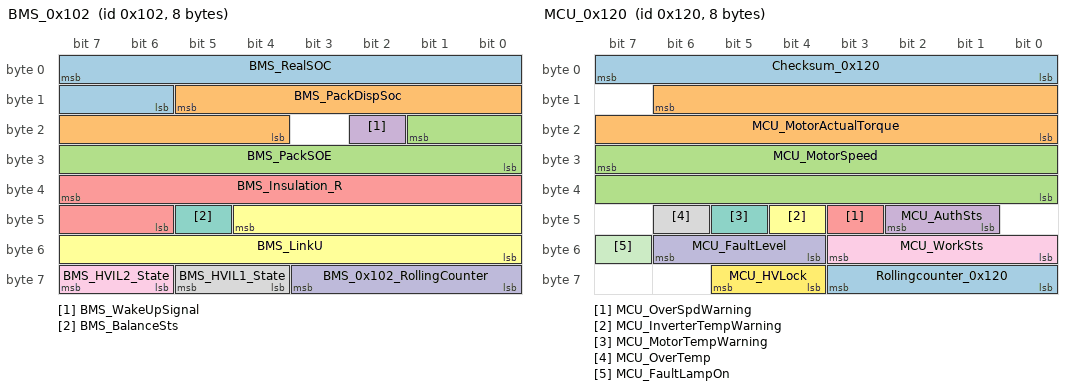
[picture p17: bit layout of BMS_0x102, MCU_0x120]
BO_ 258 BMS_0x102: 8 GW
 SG_ BMS_RealSOC : 7|10@0+ (0.1,0) [0|100] "%" TBOX
 SG_ BMS_PackDispSoc : 13|10@0+ (0.1,0) [0|100] "%" TBOX
 SG_ BMS_PackSOE : 17|10@0+ (0.1,0) [0|102.3] "kwh" TBOX
 SG_ BMS_WakeUpSignal : 18|1@0+ (1,0) [0|1] "" TBOX
 SG_ BMS_Insulation_R : 39|10@0+ (1,0) [0|1000] "KΩ" TBOX
 SG_ BMS_LinkU : 44|13@0+ (0.1,0) [0|800] "V" TBOX
 SG_ BMS_BalanceSts : 45|1@0+ (1,0) [0|1] "" TBOX
 SG_ BMS_HVIL1_State : 61|2@0+ (1,0) [0|3] "" TBOX
 SG_ BMS_HVIL2_State : 63|2@0+ (1,0) [0|3] "" TBOX
 SG_ BMS_0x102_RollingCounter : 59|4@0+ (1,0) [0|15] "" TBOX

BO_ 274 BMS_0x112: 8 GW
 SG_ BMS_MaxCellNo : 7|8@0+ (1,0) [0|255] "" TBOX
 SG_ BMS_MaxCellU : 15|13@0+ (1,0) [0|5000] "mV" TBOX
 SG_ BMS_MinCellNo : 31|8@0+ (1,0) [0|255] "" TBOX
 SG_ BMS_MinCellU : 39|13@0+ (1,0) [0|5000] "mV" TBOX
 SG_ BMS_CellVolDev : 55|12@0+ (1,0) [0|4000] "mV" TBOX
 SG_ BMS_0x112_RollingCounter : 59|4@0+ (1,0) [0|15] "" TBOX

BO_ 278 BMS_0x116: 8 GW
 SG_ BMS_CellOverVolWaring : 1|2@0+ (1,0) [0|3] "" TBOX
 SG_ BMS_CellUnderVolWaring : 3|2@0+ (1,0) [0|3] "" TBOX
 SG_ BMS_TempOverWaring : 5|2@0+ (1,0) [0|3] "" TBOX
 SG_ BMS_TempUnderWaring : 7|2@0+ (1,0) [0|3] "" TBOX
 SG_ BMS_CellVolDevWaring : 9|2@0+ (1,0) [0|3] "" TBOX
 SG_ BMS_TempDveWaring : 11|2@0+ (1,0) [0|3] "" TBOX
 SG_ BMS_BattOverVolWaring : 13|2@0+ (1,0) [0|3] "" TBOX
 SG_ BMS_BattUnderVolWaring : 15|2@0+ (1,0) [0|3] "" TBOX
 SG_ BMS_DCChargePlugTempOverHigh : 16|1@0+ (1,0) [0|1] "" TBOX
 SG_ BMS_DisCharOverCurr : 18|2@0+ (1,0) [0|3] "" TBOX
 SG_ BMS_RegenOverCurr : 20|2@0+ (1,0) [0|3] "" TBOX
 SG_ BMS_InnerCANTimeout : 21|1@0+ (1,0) [0|1] "" TBOX
 SG_ BMS_ISOWaring : 23|2@0+ (1,0) [0|3] "" TBOX
 SG_ BMS_BCUHWFault : 24|1@0+ (1,0) [0|1] "" TBOX
 SG_ BMS_NegRelayFault : 26|2@0+ (1,0) [0|3] "" TBOX
 SG_ BMS_PosRelayFault : 28|2@0+ (1,0) [0|3] "" TBOX
 SG_ BMS_PreRelayFault : 30|2@0+ (1,0) [0|3] "" TBOX
 SG_ BMS_LowVoltageMSD : 31|1@0+ (1,0) [0|1] "" TBOX
 SG_ BMS_CharPosRelayFault : 33|2@0+ (1,0) [0|3] "" TBOX
 SG_ BMS_CharNegRelayFault : 35|2@0+ (1,0) [0|3] "" TBOX
 SG_ BMS_BMUFault : 36|1@0+ (1,0) [0|1] "" TBOX
 SG_ BMS_VcuCANTimeout : 37|1@0+ (1,0) [0|1] "" TBOX
 SG_ BMS_BattHVDisaccord : 38|1@0+ (1,0) [0|1] "" TBOX
 SG_ BMS_PressureSensorFault : 39|1@0+ (1,0) [0|1] "" TBOX
 SG_ BMS_SOClow : 41|2@0+ (1,0) [0|3] "" TBOX
 SG_ BMS_Mismatch : 42|1@0+ (1,0) [0|1] "" TBOX
 SG_ BMS_SOCOverHigh : 43|1@0+ (1,0) [0|1] "" TBOX
 SG_ BMS_BattOverCharge : 44|1@0+ (1,0) [0|1] "" TBOX
 SG_ BMS_SOCSkip : 45|1@0+ (1,0) [0|1] "" TBOX
 SG_ BMS_FCGOverCurr : 46|1@0+ (1,0) [0|1] "" TBOX
 SG_ BMS_SCGOverCurr : 47|1@0+ (1,0) [0|1] "" TBOX
 SG_ BMS_LiquidLeak : 48|1@0+ (1,0) [0|1] "" TBOX
 SG_ BMS_CrashFault : 49|1@0+ (1,0) [0|1] "" TBOX
 SG_ BMS_ThermRunAway : 50|1@0+ (1,0) [0|1] "" TBOX
 SG_ BMS_Maintenance : 52|2@0+ (1,0) [0|3] "" TBOX
 SG_ BMS_BusbarTempOverWaring : 53|1@0+ (1,0) [0|1] "" TBOX
 SG_ BMS_FuseFault : 54|1@0+ (1,0) [0|1] "" TBOX
 SG_ BMS_CurrSensorFault : 61|2@0+ (1,0) [0|3] "" TBOX
 SG_ BMS_0x116_RollingCounter : 59|4@0+ (1,0) [0|15] "" TBOX

BO_ 288 MCU_0x120: 8 GW
 SG_ Checksum_0x120 : 7|8@0+ (1,0) [0|255] "" TBOX
 SG_ MCU_MotorActualTorque : 14|15@0+ (0.1,-1000) [-1000|1000] "NM" TBOX
 SG_ MCU_MotorSpeed : 31|16@0+ (1,-32767) [-32767|32768] "RPM" TBOX
 SG_ MCU_AuthSts : 42|2@0+ (1,0) [0|3] "" TBOX
 SG_ MCU_OverSpdWarning : 43|1@0+ (1,0) [0|1] "" TBOX
 SG_ MCU_InverterTempWarning : 44|1@0+ (1,0) [0|1] "" TBOX
 SG_ MCU_MotorTempWarning : 45|1@0+ (1,0) [0|1] "" TBOX
 SG_ MCU_OverTemp : 46|1@0+ (1,0) [0|1] "" TBOX
 SG_ MCU_WorkSts : 51|4@0+ (1,0) [0|15] "" TBOX
 SG_ MCU_FaultLevel : 54|3@0+ (1,0) [0|7] "" TBOX
 SG_ MCU_FaultLampOn : 55|1@0+ (1,0) [0|1] "" TBOX
 SG_ MCU_HVLock : 61|2@0+ (1,0) [0|3] "" TBOX
 SG_ Rollingcounter_0x120 : 59|4@0+ (1,0) [0|15] "" TBOX

BO_ 290 MCU_0x122: 8 GW
 SG_ Checksum_0x122 : 7|8@0+ (1,0) [0|255] "" TBOX
 SG_ MCU_MaxAvailableTorque : 15|11@0+ (1,-1023) [-1023|1024] "NM" TBOX
 SG_ MCU_MinAvailableTorque : 18|11@0+ (1,-1023) [-1023|1024] "NM" TBOX
 SG_ MCU_DeratingTempCoolant : 35|1@0+ (1,0) [0|1] "" TBOX
 SG_ MCU_damping_En : 39|1@0+ (1,0) [0|1] "" TBOX
 SG_ MCU_DeratingTrqMin : 40|1@0+ (1,0) [0|1] "" TBOX
 SG_ MCU_DeratingTrqMax : 41|1@0+ (1,0) [0|1] "" TBOX
 SG_ MCU_DeratingOvrUdc : 42|1@0+ (1,0) [0|1] "" TBOX
 SG_ MCU_DeratingUndrUdc : 43|1@0+ (1,0) [0|1] "" TBOX
 SG_ MCU_DeratingOvrIdc : 44|1@0+ (1,0) [0|1] "" TBOX
 SG_ MCU_DeratingUndrIdc : 45|1@0+ (1,0) [0|1] "" TBOX
 SG_ MCU_DeratingTempEm : 46|1@0+ (1,0) [0|1] "" TBOX
 SG_ MCU_DeratingTempInv : 47|1@0+ (1,0) [0|1] "" TBOX
 SG_ Rollingcounter_0x122 : 59|4@0+ (1,0) [0|15] "" TBOX
 SG_ MCU_MotorTorqueDeratingFlg : 61|1@0+ (1,0) [0|1] "" TBOX
 SG_ MCU_HVReady : 62|1@0+ (1,0) [0|1] "" TBOX
 SG_ MCU_DeratingOverSpd : 63|1@0+ (1,0) [0|1] "" TBOX

BO_ 289 ESP_0x121: 8 GW
 SG_ Checksum_0x121 : 7|8@0+ (1,0) [0|255] "" TBOX
 SG_ ESP_VehicleSpeed : 11|12@0+ (0.05625,0) [0|230.2875] "kph" TBOX
 SG_ ESP_VehicleSpeed_Valid : 12|1@0+ (1,0) [0|1] "" TBOX
 SG_ ESP_OFF : 13|1@0+ (1,0) [0|1] "" TBOX
 SG_ ESP_ABS_Error : 14|1@0+ (1,0) [0|1] "" TBOX
 SG_ ESP_ABS_Intervention : 15|1@0+ (1,0) [0|1] "" TBOX
 SG_ ESP_VDC_TCS_Error : 24|1@0+ (1,0) [0|1] "" TBOX
 SG_ ESP_EBD_Error : 25|1@0+ (1,0) [0|1] "" TBOX
 SG_ ESP_VDC_Intervention : 26|1@0+ (1,0) [0|1] "" TBOX
 SG_ ESP_TCS_Intervention : 27|1@0+ (1,0) [0|1] "" TBOX
 SG_ ESP_EBD_Intervention : 28|1@0+ (1,0) [0|1] "" TBOX
 SG_ ESP_HDC_Status : 31|2@0+ (1,0) [0|3] "" TBOX
 SG_ ESP_HDC_Available : 32|1@0+ (1,0) [0|1] "" TBOX
 SG_ ESP_EPBMainteDiagmodeActive : 33|1@0+ (1,0) [0|1] "" TBOX
 SG_ ESP_EPBFailstatus : 34|1@0+ (1,0) [0|1] "°/s" TBOX
 SG_ ESP_EPBStatus : 37|3@0+ (1,0) [0|7] "" TBOX
 SG_ ESP_VehicleStop : 38|1@0+ (1,0) [0|1] "" TBOX
 SG_ ESP_VehicleStop_Valid : 39|1@0+ (1,0) [0|1] "" TBOX
 SG_ ESP_MasterCyPressureCmp : 47|8@0+ (1,0) [0|255] "bar" TBOX
 SG_ ESP_MasterCyPressure_Valid : 48|1@0+ (1,0) [0|1] "" TBOX
 SG_ ESP_WheelCyBrakeForce_Exist : 49|1@0+ (1,0) [0|1] "" TBOX
 SG_ ESP_ESPLamp : 50|1@0+ (1,0) [0|1] "" TBOX
 SG_ ESP_AVHstandbyStatus : 51|1@0+ (1,0) [0|1] "" TBOX
 SG_ ESP_AVHActive : 52|1@0+ (1,0) [0|1] "" TBOX
 SG_ ESP_AVH_availalbe : 53|1@0+ (1,0) [0|1] "" TBOX
 SG_ ESP_HHC_Available : 54|1@0+ (1,0) [0|1] "" TBOX
 SG_ ESP_HHCActive : 55|1@0+ (1,0) [0|1] "" TBOX
 SG_ ESP_HubDiagmodeActive : 60|1@0+ (1,0) [0|1] "" TBOX
 SG_ ESP_HAZ_Active : 61|1@0+ (1,0) [0|1] "" TBOX
 SG_ ESP_MILLampRequest : 62|1@0+ (1,0) [0|1] "" TBOX
 SG_ RollingCounter_0x121 : 59|4@0+ (1,0) [0|15] "" TBOX

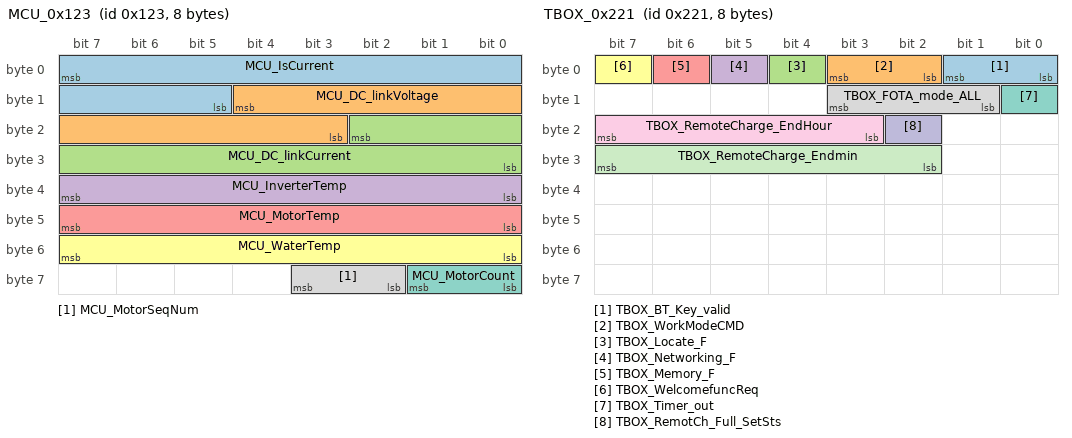
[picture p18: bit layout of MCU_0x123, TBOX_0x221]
BO_ 291 MCU_0x123: 8 GW
 SG_ MCU_IsCurrent : 7|11@0+ (0.5,0) [0|1023.5] "" TBOX
 SG_ MCU_DC_linkVoltage : 12|10@0+ (1,0) [0|1023] "V" TBOX
 SG_ MCU_DC_linkCurrent : 18|11@0+ (1,-1023) [-1023|1024] "A" TBOX
 SG_ MCU_InverterTemp : 39|8@0+ (1,-40) [-40|215] "℃" TBOX
 SG_ MCU_MotorTemp : 47|8@0+ (1,-40) [-40|215] "℃" TBOX
 SG_ MCU_WaterTemp : 55|8@0+ (1,-40) [-40|215] "℃" TBOX
 SG_ MCU_MotorCount : 57|2@0+ (1,0) [1|3] "个" TBOX
 SG_ MCU_MotorSeqNum : 59|2@0+ (1,0) [1|3] "" TBOX

BO_ 292 MCU_0x124: 8 GW
 SG_ MCU_DBCTempU : 7|8@0+ (1,-40) [-40|215] "degC" TBOX
 SG_ MCU_DBCTempV : 15|8@0+ (1,-40) [-40|215] "degC" TBOX
 SG_ MCU_DBCTempW : 23|8@0+ (1,-40) [-40|215] "degC" TBOX
 SG_ MCU_RotorTemp : 31|8@0+ (1,-40) [-40|215] "℃" TBOX
 SG_ MCU_MotoroffsetSts : 36|2@0+ (1,0) [0|3] "" TBOX
 SG_ MCU_stGateDrv : 39|2@0+ (1,0) [0|3] "" TBOX
 SG_ MCU_Motoroffset : 43|12@0+ (0.0878906,0) [0|359.9120178] "度" TBOX

BO_ 545 TBOX_0x221: 8 TBOX
 SG_ TBOX_BT_Key_valid : 1|2@0+ (1,0) [0|3] "" GW
 SG_ TBOX_WorkModeCMD : 3|2@0+ (1,0) [0|3] "" GW
 SG_ TBOX_Locate_F : 4|1@0+ (1,0) [0|1] "" GW
 SG_ TBOX_Networking_F : 5|1@0+ (1,0) [0|1] "" GW
 SG_ TBOX_Memory_F : 6|1@0+ (1,0) [0|1] "" GW
 SG_ TBOX_WelcomefuncReq : 7|1@0+ (1,0) [0|1] "" GW
 SG_ TBOX_Timer_out : 8|1@0+ (1,0) [0|1] "" GW
 SG_ TBOX_FOTA_mode_ALL : 11|3@0+ (1,0) [0|7] "" GW
 SG_ TBOX_RemoteCharge_EndHour : 23|5@0+ (1,0) [0|23] "hour" GW
 SG_ TBOX_RemotCh_Full_SetSts : 18|1@0+ (1,0) [0|1] "" GW
 SG_ TBOX_RemoteCharge_Endmin : 31|6@0+ (1,0) [0|59] "min" GW

BO_ 599 AC_0x257: 8 GW
 SG_ AC_RemoteAC : 2|3@0+ (1,0) [0|7] "" TBOX
 SG_ AC_RemoteACFeedback : 7|4@0+ (1,0) [0|15] "" TBOX
 SG_ AC_SolarIntensity : 15|5@0+ (50,0) [0|1100] "" TBOX
 SG_ AC_Temp_setvalue : 22|5@0+ (1,0) [15|31] "" TBOX
 SG_ AC_inout_MixwindSts : 31|5@0+ (5,0) [0|100] "%" TBOX
 SG_ AC_OutPM25Value : 55|10@0+ (1,0) [0|1023] "μg/m3" TBOX

BO_ 849 TBOX_0x351: 8 TBOX
 SG_ TBOX_BCM_DoorLock_Control_4G : 1|2@0+ (1,0) [0|3] "" GW
 SG_ TBOX_BCM_CarLocating : 4|3@0+ (1,0) [0|7] "" GW
 SG_ TBOX_PLG_TrunkunLock : 7|2@0+ (1,0) [0|3] "" GW
 SG_ TBOX_DSM_heatSwitch : 9|2@0+ (1,0) [0|3] "" GW
 SG_ TBOX_PSM_heatSwitch : 11|2@0+ (1,0) [0|3] "" GW
 SG_ TBOX_DSM_GetMemoryReq : 15|4@0+ (1,0) [0|15] "" GW
 SG_ TBOX_BCM_DoorLock_Control_BT : 17|2@0+ (1,0) [0|3] "" GW
 SG_ TBOX_DSM_Targtemp : 23|6@0+ (1,0) [34|42] "℃" GW
 SG_ TBOX_welcomefuncReqsts : 24|1@0+ (1,0) [0|1] "" GW
 SG_ TBOX_Publish_Wakeup : 25|1@0+ (1,0) [0|1] "" GW
 SG_ TBOX_PSM_Targtemp : 31|6@0+ (1,0) [34|42] "℃" GW
 SG_ TBOX_BCM_selflearn_MD1 : 32|1@0+ (1,0) [0|1] "" GW
 SG_ TBOX_BCM_selflearn_Mrollo : 33|1@0+ (1,0) [0|1] "" GW
 SG_ TBOX_BCM_forceclose_MD1 : 34|1@0+ (1,0) [0|1] "" GW
 SG_ TBOX_BCM_forceclose_Mrollo : 35|1@0+ (1,0) [0|1] "" GW
 SG_ TBOX_BCM_stopsunroof : 36|1@0+ (1,0) [0|1] "" GW
 SG_ TBOX_BCM_PowerON_Request : 38|2@0+ (1,0) [0|3] "" GW
 SG_ TBOX_BCM_PowerON_limit : 39|1@0+ (1,0) [0|1] "" GW
 SG_ TBOX_BCM_SrfSlidePosReq : 47|8@0+ (1,0) [0|254] "" GW
 SG_ TBOX_BCM_ShadeSlidePosReq : 55|8@0+ (1,0) [0|254] "" GW
 SG_ TBOX_BCM_FLWindowsControl : 57|2@0+ (1,0) [0|3] "" GW
 SG_ TBOX_BCM_FRWindowsControl : 59|2@0+ (1,0) [0|3] "" GW
 SG_ TBOX_BCM_RLWindowsControl : 61|2@0+ (1,0) [0|3] "" GW
 SG_ TBOX_BCM_RRWindowsControl : 63|2@0+ (1,0) [0|3] "" GW

BO_ 850 TBOX_0x352: 8 TBOX
 SG_ TBOX_AC_SystemSet : 1|2@0+ (1,0) [0|3] "" GW
 SG_ TBOX_AC_Cycle : 3|2@0+ (1,0) [0|3] "" GW
 SG_ TBOX_AC_EAC_Control : 5|2@0+ (1,0) [0|3] "" GW
 SG_ TBOX_AC_AutoMode_Set : 7|2@0+ (1,0) [0|3] "" GW
 SG_ TBOX_AC_WindMode_Set : 10|3@0+ (1,0) [0|7] "" GW
 SG_ TBOX_AC_BlowingRate_Set : 15|3@0+ (1,0) [0|7] "" GW
 SG_ TBOX_AC_APTCSW_Set : 17|2@0+ (1,0) [0|3] "" GW
 SG_ TBOX_AC_Temp_set : 22|5@0+ (1,0) [15|31] "" GW
 SG_ TBOX_HU_rebootACK : 24|1@0+ (1,0) [0|1] "" GW
 SG_ TBOX_RemotePhotograph : 26|2@0+ (1,0) [0|3] "" GW
 SG_ TBOX_PLG_OpenControl : 33|2@0+ (1,0) [0|3] "" GW
 SG_ TBOX_RemoteCharge_StartHour : 39|5@0+ (1,0) [0|23] "" GW
 SG_ TBOX_RemoteCharge_Setsts : 40|1@0+ (1,0) [0|1] "" GW
 SG_ TBOX_ChargeCtrl_Setsts : 41|1@0+ (1,0) [0|1] "" GW
 SG_ TBOX_RemoteCharge_Startmin : 47|6@0+ (1,0) [0|59] "" GW
 SG_ TBOX_BCM_FLWindowsVoiControl : 51|4@0+ (1,0) [0|15] "" GW
 SG_ TBOX_BCM_FRWindowsVoiControl : 55|4@0+ (1,0) [0|15] "" GW
 SG_ TBOX_BCM_RLWindowsVoiControl : 59|4@0+ (1,0) [0|15] "" GW
 SG_ TBOX_BCM_RRWindowsVoiControl : 63|4@0+ (1,0) [0|15] "" GW

BO_ 851 TBOX_0x353: 8 TBOX
 SG_ Checksum_0x353 : 7|8@0+ (1,0) [0|255] "" GW
 SG_ TBOX_RemoteChargetime : 15|10@0+ (1,0) [0|1023] "Min" GW
 SG_ TBOX_VCU_12vChargeReq : 16|1@0+ (1,0) [0|1] "" GW
 SG_ TBOX_VCU_TimeCharge : 18|2@0+ (1,0) [0|3] "" GW
 SG_ TBOX_BTKey_valid : 19|1@0+ (1,0) [0|1] "" GW
 SG_ TBOX_ChargeDepthSet : 21|2@0+ (1,0) [0|3] "" GW
 SG_ TBOX_RemoteChargeper : 31|8@0+ (1,0) [0|100] "%" GW
 SG_ TBOX_APS_EPSStrgWhlAngZero : 32|1@0+ (1,0) [0|1] "" GW
 SG_ TBOX_APS_RequstRemoteParkOut : 33|1@0+ (1,0) [0|1] "" GW
 SG_ TBOX_APS_StartRemoteParkOut : 34|1@0+ (1,0) [0|1] "" GW
 SG_ TBOX_APS_RequstRemoteParkIn : 36|1@0+ (1,0) [0|1] "" GW
 SG_ TBOX_APS_StartRemoteParkIn : 37|1@0+ (1,0) [0|1] "" GW
 SG_ TBOX_APS_PoewerOff_Request : 39|2@0+ (1,0) [0|3] "" GW
 SG_ TBOX_APS_StraightOut_Request1 : 41|2@0+ (1,0) [0|3] "" GW
 SG_ TBOX_APS_StraightOut_Request2 : 43|2@0+ (1,0) [0|3] "" GW
 SG_ TBOX_APS_PowerON_Request : 45|2@0+ (1,0) [0|3] "" GW
 SG_ TBOX_VCU_RemoteChrgLock : 46|1@0+ (1,0) [0|1] "" GW
 SG_ TBOX_FOTA_mode : 47|1@0+ (1,0) [0|1] "" GW
 SG_ TBOX_FOTA_wakeup : 62|3@0+ (1,0) [0|7] "" GW
 SG_ RollingCounter_0x353 : 59|4@0+ (1,0) [0|15] "" GW

BO_ 853 TBOX_0x355_Time: 8 TBOX
 SG_ TBOX_TimeSyncSts : 7|1@0+ (1,0) [0|1] "" GW
 SG_ TBOX_TimeSyncData_Year : 15|7@0+ (1,2000) [2000|2099] "" GW
 SG_ TBOX_TimeSyncData_Month : 23|4@0+ (1,0) [1|12] "" GW
 SG_ TBOX_TimeSyncData_Day : 31|5@0+ (1,0) [1|31] "" GW
 SG_ TBOX_TimeSyncData_Hour : 39|5@0+ (1,0) [0|23] "" GW
 SG_ TBOX_TimeSyncData_Minute : 47|6@0+ (1,0) [0|59] "" GW
 SG_ TBOX_TimeSyncData_Second : 55|6@0+ (1,0) [0|59] "" GW

BO_ 1026 TBOX_NM_0x402: 8 TBOX
 SG_ TBOX_NM_DA : 7|8@0+ (1,0) [0|255] "" GW
 SG_ TBOX_NM_ALIVE : 8|1@0+ (1,0) [0|1] "" GW
 SG_ TBOX_NM_RING : 9|1@0+ (1,0) [0|1] "" GW
 SG_ TBOX_NM_LIMPHOME : 10|1@0+ (1,0) [0|1] "" GW
 SG_ TBOX_NM_SLEEP_INDICATION : 12|1@0+ (1,0) [0|1] "" GW
 SG_ TBOX_NM_SLEEP_ACK : 13|1@0+ (1,0) [0|1] "" GW

BO_ 1028 GW_TBOX_NM_0x404: 8 GW
 SG_ GW_Tbox_NM_DA : 7|8@0+ (1,0) [0|255] "" TBOX
 SG_ GW_Tbox_NM_ALIVE : 8|1@0+ (1,0) [0|1] "" TBOX
 SG_ GW_Tbox_NM_RING : 9|1@0+ (1,0) [0|1] "" TBOX
 SG_ GW_Tbox_NM_LIMPHOME : 10|1@0+ (1,0) [0|1] "" TBOX
 SG_ GW_Tbox_NM_SLEEP_Ind : 12|1@0+ (1,0) [0|1] "" TBOX
 SG_ GW_Tbox_NM_SLEEP_ACK : 13|1@0+ (1,0) [0|1] "" TBOX

BO_ 1299 BMS_0x513: 8 GW
 SG_ BMS_MaxTempNo : 7|8@0+ (1,0) [0|255] "" TBOX
 SG_ BMS_MaxTemp : 15|8@0+ (0.5,-40) [-40|85] "℃" TBOX
 SG_ BMS_MinTempNo : 23|8@0+ (1,0) [0|255] "" TBOX
 SG_ BMS_MinTemp : 31|8@0+ (0.5,-40) [-40|85] "℃" TBOX
 SG_ BMS_BattTempDev : 39|8@0+ (0.5,-40) [-40|85] "℃" TBOX
 SG_ BMS_CCTemp1 : 47|8@0+ (1,-40) [-40|120] "℃" TBOX
 SG_ BMS_CCTemp2 : 55|8@0+ (1,-40) [-40|120] "℃" TBOX
 SG_ BMS_0x513_RollingCounter : 59|4@0+ (1,0) [0|15] "" TBOX

BO_ 1300 BMS_0x514: 8 GW
 SG_ BMS_ModuleBusbarMaxTempNo : 15|8@0+ (1,0) [0|255] "" TBOX
 SG_ BMS_ModuleBusbarMaxTemp : 23|8@0+ (0.5,-40) [-40|85] "℃" TBOX
 SG_ BMS_ModuleBusbarMinTempNo : 31|8@0+ (1,0) [0|255] "" TBOX
 SG_ BMS_ModuleBusbarMinTemp : 39|8@0+ (0.5,-40) [-40|85] "℃" TBOX
 SG_ BMS_0x514_RollingCounter : 59|4@0+ (1,0) [0|15] "" TBOX

BO_ 1328 BMS_0x530: 8 GW
 SG_ BMS_BattCellNum1Vol : 7|16@0+ (1,0) [0|5000] "mV" TBOX
 SG_ BMS_BattCellNum2Vol : 23|16@0+ (1,0) [0|5000] "mV" TBOX
 SG_ BMS_BattCellNum3Vol : 39|16@0+ (1,0) [0|5000] "mV" TBOX
 SG_ BMS_BattCellNum4Vol : 55|16@0+ (1,0) [0|5000] "mV" TBOX

BO_ 1329 BMS_0x531: 8 GW
 SG_ BMS_BattCellNum5Vol : 7|16@0+ (1,0) [0|5000] "mV" TBOX
 SG_ BMS_BattCellNum6Vol : 23|16@0+ (1,0) [0|5000] "mV" TBOX
 SG_ BMS_BattCellNum7Vol : 39|16@0+ (1,0) [0|5000] "mV" TBOX
 SG_ BMS_BattCellNum8Vol : 55|16@0+ (1,0) [0|5000] "mV" TBOX

BO_ 1330 BMS_0x532: 8 GW
 SG_ BMS_BattCellNum9Vol : 7|16@0+ (1,0) [0|5000] "mV" TBOX
 SG_ BMS_BattCellNum10Vol : 23|16@0+ (1,0) [0|5000] "mV" TBOX
 SG_ BMS_BattCellNum11Vol : 39|16@0+ (1,0) [0|5000] "mV" TBOX
 SG_ BMS_BattCellNum12Vol : 55|16@0+ (1,0) [0|5000] "mV" TBOX

BO_ 1331 BMS_0x533: 8 GW
 SG_ BMS_BattCellNum13Vol : 7|16@0+ (1,0) [0|5000] "mV" TBOX
 SG_ BMS_BattCellNum14Vol : 23|16@0+ (1,0) [0|5000] "mV" TBOX
 SG_ BMS_BattCellNum15Vol : 39|16@0+ (1,0) [0|5000] "mV" TBOX
 SG_ BMS_BattCellNum16Vol : 55|16@0+ (1,0) [0|5000] "mV" TBOX

BO_ 1332 BMS_0x534: 8 GW
 SG_ BMS_BattCellNum17Vol : 7|16@0+ (1,0) [0|5000] "mV" TBOX
 SG_ BMS_BattCellNum18Vol : 23|16@0+ (1,0) [0|5000] "mV" TBOX
 SG_ BMS_BattCellNum19Vol : 39|16@0+ (1,0) [0|5000] "mV" TBOX
 SG_ BMS_BattCellNum20Vol : 55|16@0+ (1,0) [0|5000] "mV" TBOX

BO_ 1333 BMS_0x535: 8 GW
 SG_ BMS_BattCellNum21Vol : 7|16@0+ (1,0) [0|5000] "mV" TBOX
 SG_ BMS_BattCellNum22Vol : 23|16@0+ (1,0) [0|5000] "mV" TBOX
 SG_ BMS_BattCellNum23Vol : 39|16@0+ (1,0) [0|5000] "mV" TBOX
 SG_ BMS_BattCellNum24Vol : 55|16@0+ (1,0) [0|5000] "mV" TBOX

BO_ 1334 BMS_0x536: 8 GW
 SG_ BMS_BattCellNum25Vol : 7|16@0+ (1,0) [0|5000] "mV" TBOX
 SG_ BMS_BattCellNum26Vol : 23|16@0+ (1,0) [0|5000] "mV" TBOX
 SG_ BMS_BattCellNum27Vol : 39|16@0+ (1,0) [0|5000] "mV" TBOX
 SG_ BMS_BattCellNum28Vol : 55|16@0+ (1,0) [0|5000] "mV" TBOX

BO_ 1335 BMS_0x537: 8 GW
 SG_ BMS_BattCellNum29Vol : 7|16@0+ (1,0) [0|5000] "mV" TBOX
 SG_ BMS_BattCellNum30Vol : 23|16@0+ (1,0) [0|5000] "mV" TBOX
 SG_ BMS_BattCellNum31Vol : 39|16@0+ (1,0) [0|5000] "mV" TBOX
 SG_ BMS_BattCellNum32Vol : 55|16@0+ (1,0) [0|5000] "mV" TBOX

BO_ 1336 BMS_0x538: 8 GW
 SG_ BMS_BattCellNum33Vol : 7|16@0+ (1,0) [0|5000] "mV" TBOX
 SG_ BMS_BattCellNum34Vol : 23|16@0+ (1,0) [0|5000] "mV" TBOX
 SG_ BMS_BattCellNum35Vol : 39|16@0+ (1,0) [0|5000] "mV" TBOX
 SG_ BMS_BattCellNum36Vol : 55|16@0+ (1,0) [0|5000] "mV" TBOX

BO_ 1337 BMS_0x539: 8 GW
 SG_ BMS_BattCellNum37Vol : 7|16@0+ (1,0) [0|5000] "mV" TBOX
 SG_ BMS_BattCellNum38Vol : 23|16@0+ (1,0) [0|5000] "mV" TBOX
 SG_ BMS_BattCellNum39Vol : 39|16@0+ (1,0) [0|5000] "mV" TBOX
 SG_ BMS_BattCellNum40Vol : 55|16@0+ (1,0) [0|5000] "mV" TBOX

BO_ 1338 BMS_0x53A: 8 GW
 SG_ BMS_BattCellNum41Vol : 7|16@0+ (1,0) [0|5000] "mV" TBOX
 SG_ BMS_BattCellNum42Vol : 23|16@0+ (1,0) [0|5000] "mV" TBOX
 SG_ BMS_BattCellNum43Vol : 39|16@0+ (1,0) [0|5000] "mV" TBOX
 SG_ BMS_BattCellNum44Vol : 55|16@0+ (1,0) [0|5000] "mV" TBOX

BO_ 1339 BMS_0x53B: 8 GW
 SG_ BMS_BattCellNum45Vol : 7|16@0+ (1,0) [0|5000] "mV" TBOX
 SG_ BMS_BattCellNum46Vol : 23|16@0+ (1,0) [0|5000] "mV" TBOX
 SG_ BMS_BattCellNum47Vol : 39|16@0+ (1,0) [0|5000] "mV" TBOX
 SG_ BMS_BattCellNum48Vol : 55|16@0+ (1,0) [0|5000] "mV" TBOX

BO_ 1340 BMS_0x53C: 8 GW
 SG_ BMS_BattCellNum49Vol : 7|16@0+ (1,0) [0|5000] "mV" TBOX
 SG_ BMS_BattCellNum50Vol : 23|16@0+ (1,0) [0|5000] "mV" TBOX
 SG_ BMS_BattCellNum51Vol : 39|16@0+ (1,0) [0|5000] "mV" TBOX
 SG_ BMS_BattCellNum52Vol : 55|16@0+ (1,0) [0|5000] "mV" TBOX

BO_ 1341 BMS_0x53D: 8 GW
 SG_ BMS_BattCellNum53Vol : 7|16@0+ (1,0) [0|5000] "mV" TBOX
 SG_ BMS_BattCellNum54Vol : 23|16@0+ (1,0) [0|5000] "mV" TBOX
 SG_ BMS_BattCellNum55Vol : 39|16@0+ (1,0) [0|5000] "mV" TBOX
 SG_ BMS_BattCellNum56Vol : 55|16@0+ (1,0) [0|5000] "mV" TBOX

BO_ 1342 BMS_0x53E: 8 GW
 SG_ BMS_BattCellNum57Vol : 7|16@0+ (1,0) [0|5000] "mV" TBOX
 SG_ BMS_BattCellNum58Vol : 23|16@0+ (1,0) [0|5000] "mV" TBOX
 SG_ BMS_BattCellNum59Vol : 39|16@0+ (1,0) [0|5000] "mV" TBOX
 SG_ BMS_BattCellNum60Vol : 55|16@0+ (1,0) [0|5000] "mV" TBOX

BO_ 1343 BMS_0x53F: 8 GW
 SG_ BMS_BattCellNum61Vol : 7|16@0+ (1,0) [0|5000] "mV" TBOX
 SG_ BMS_BattCellNum62Vol : 23|16@0+ (1,0) [0|5000] "mV" TBOX
 SG_ BMS_BattCellNum63Vol : 39|16@0+ (1,0) [0|5000] "mV" TBOX
 SG_ BMS_BattCellNum64Vol : 55|16@0+ (1,0) [0|5000] "mV" TBOX

BO_ 1344 BMS_0x540: 8 GW
 SG_ BMS_BattCellNum65Vol : 7|16@0+ (1,0) [0|5000] "mV" TBOX
 SG_ BMS_BattCellNum66Vol : 23|16@0+ (1,0) [0|5000] "mV" TBOX
 SG_ BMS_BattCellNum67Vol : 39|16@0+ (1,0) [0|5000] "mV" TBOX
 SG_ BMS_BattCellNum68Vol : 55|16@0+ (1,0) [0|5000] "mV" TBOX

BO_ 1345 BMS_0x541: 8 GW
 SG_ BMS_BattCellNum69Vol : 7|16@0+ (1,0) [0|5000] "mV" TBOX
 SG_ BMS_BattCellNum70Vol : 23|16@0+ (1,0) [0|5000] "mV" TBOX
 SG_ BMS_BattCellNum71Vol : 39|16@0+ (1,0) [0|5000] "mV" TBOX
 SG_ BMS_BattCellNum72Vol : 55|16@0+ (1,0) [0|5000] "mV" TBOX

BO_ 1346 BMS_0x542: 8 GW
 SG_ BMS_BattCellNum73Vol : 7|16@0+ (1,0) [0|5000] "mV" TBOX
 SG_ BMS_BattCellNum74Vol : 23|16@0+ (1,0) [0|5000] "mV" TBOX
 SG_ BMS_BattCellNum75Vol : 39|16@0+ (1,0) [0|5000] "mV" TBOX
 SG_ BMS_BattCellNum76Vol : 55|16@0+ (1,0) [0|5000] "mV" TBOX

BO_ 1347 BMS_0x543: 8 GW
 SG_ BMS_BattCellNum77Vol : 7|16@0+ (1,0) [0|5000] "mV" TBOX
 SG_ BMS_BattCellNum78Vol : 23|16@0+ (1,0) [0|5000] "mV" TBOX
 SG_ BMS_BattCellNum79Vol : 39|16@0+ (1,0) [0|5000] "mV" TBOX
 SG_ BMS_BattCellNum80Vol : 55|16@0+ (1,0) [0|5000] "mV" TBOX

BO_ 1348 BMS_0x544: 8 GW
 SG_ BMS_BattCellNum81Vol : 7|16@0+ (1,0) [0|5000] "mV" TBOX
 SG_ BMS_BattCellNum82Vol : 23|16@0+ (1,0) [0|5000] "mV" TBOX
 SG_ BMS_BattCellNum83Vol : 39|16@0+ (1,0) [0|5000] "mV" TBOX
 SG_ BMS_BattCellNum84Vol : 55|16@0+ (1,0) [0|5000] "mV" TBOX

BO_ 1349 BMS_0x545: 8 GW
 SG_ BMS_BattCellNum85Vol : 7|16@0+ (1,0) [0|5000] "mV" TBOX
 SG_ BMS_BattCellNum86Vol : 23|16@0+ (1,0) [0|5000] "mV" TBOX
 SG_ BMS_BattCellNum87Vol : 39|16@0+ (1,0) [0|5000] "mV" TBOX
 SG_ BMS_BattCellNum88Vol : 55|16@0+ (1,0) [0|5000] "mV" TBOX

BO_ 1350 BMS_0x546: 8 GW
 SG_ BMS_BattCellNum89Vol : 7|16@0+ (1,0) [0|5000] "mV" TBOX
 SG_ BMS_BattCellNum90Vol : 23|16@0+ (1,0) [0|5000] "mV" TBOX
 SG_ BMS_BattCellNum91Vol : 39|16@0+ (1,0) [0|5000] "mV" TBOX
 SG_ BMS_BattCellNum92Vol : 55|16@0+ (1,0) [0|5000] "mV" TBOX

BO_ 1351 BMS_0x547: 8 GW
 SG_ BMS_BattCellNum93Vol : 7|16@0+ (1,0) [0|5000] "mV" TBOX
 SG_ BMS_BattCellNum94Vol : 23|16@0+ (1,0) [0|5000] "mV" TBOX
 SG_ BMS_BattCellNum95Vol : 39|16@0+ (1,0) [0|5000] "mV" TBOX
 SG_ BMS_BattCellNum96Vol : 55|16@0+ (1,0) [0|5000] "mV" TBOX

BO_ 1352 BMS_0x548: 8 GW
 SG_ BMS_BattCellNum97Vol : 7|16@0+ (1,0) [0|5000] "mV" TBOX
 SG_ BMS_BattCellNum98Vol : 23|16@0+ (1,0) [0|5000] "mV" TBOX
 SG_ BMS_BattCellNum99Vol : 39|16@0+ (1,0) [0|5000] "mV" TBOX
 SG_ BMS_BattCellNum100Vol : 55|16@0+ (1,0) [0|5000] "mV" TBOX

BO_ 1353 BMS_0x549: 8 GW
 SG_ BMS_BattCellNum101Vol : 7|16@0+ (1,0) [0|5000] "mV" TBOX
 SG_ BMS_BattCellNum102Vol : 23|16@0+ (1,0) [0|5000] "mV" TBOX
 SG_ BMS_BattCellNum103Vol : 39|16@0+ (1,0) [0|5000] "mV" TBOX
 SG_ BMS_BattCellNum104Vol : 55|16@0+ (1,0) [0|5000] "mV" TBOX

BO_ 1354 BMS_0x54A: 8 GW
 SG_ BMS_BattCellNum105Vol : 7|16@0+ (1,0) [0|5000] "mV" TBOX
 SG_ BMS_BattCellNum106Vol : 23|16@0+ (1,0) [0|5000] "mV" TBOX
 SG_ BMS_BattCellNum107Vol : 39|16@0+ (1,0) [0|5000] "mV" TBOX
 SG_ BMS_BattCellNum108Vol : 55|16@0+ (1,0) [0|5000] "mV" TBOX

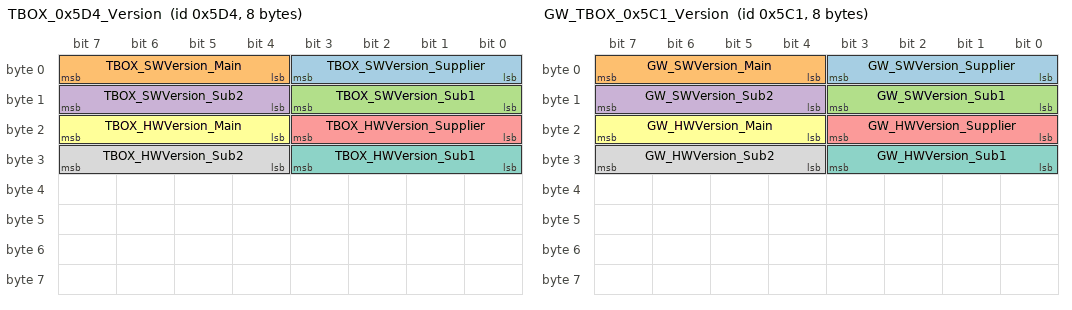
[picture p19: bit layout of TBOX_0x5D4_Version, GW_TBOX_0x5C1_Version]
BO_ 1492 TBOX_0x5D4_Version: 8 TBOX
 SG_ TBOX_SWVersion_Supplier : 3|4@0+ (1,0) [0|15] "" Vector__XXX
 SG_ TBOX_SWVersion_Main : 7|4@0+ (1,0) [0|15] "" Vector__XXX
 SG_ TBOX_SWVersion_Sub1 : 11|4@0+ (1,0) [0|15] "" Vector__XXX
 SG_ TBOX_SWVersion_Sub2 : 15|4@0+ (1,0) [0|15] "" Vector__XXX
 SG_ TBOX_HWVersion_Supplier : 19|4@0+ (1,0) [0|15] "" Vector__XXX
 SG_ TBOX_HWVersion_Main : 23|4@0+ (1,0) [0|15] "" Vector__XXX
 SG_ TBOX_HWVersion_Sub1 : 27|4@0+ (1,0) [0|15] "" Vector__XXX
 SG_ TBOX_HWVersion_Sub2 : 31|4@0+ (1,0) [0|15] "" Vector__XXX

BO_ 1520 BMS_0x5F0: 8 GW
 SG_ BMS_BattTempSensorNum1 : 7|8@0+ (1,-40) [-40|120] "℃" TBOX
 SG_ BMS_BattTempSensorNum2 : 15|8@0+ (1,-40) [-40|120] "℃" TBOX
 SG_ BMS_BattTempSensorNum3 : 23|8@0+ (1,-40) [-40|120] "℃" TBOX
 SG_ BMS_BattTempSensorNum4 : 31|8@0+ (1,-40) [-40|120] "℃" TBOX
 SG_ BMS_BattTempSensorNum5 : 39|8@0+ (1,-40) [-40|120] "℃" TBOX
 SG_ BMS_BattTempSensorNum6 : 47|8@0+ (1,-40) [-40|120] "℃" TBOX
 SG_ BMS_BattTempSensorNum7 : 55|8@0+ (1,-40) [-40|120] "℃" TBOX
 SG_ BMS_BattTempSensorNum8 : 63|8@0+ (1,-40) [-40|120] "℃" TBOX

BO_ 1521 BMS_0x5F1: 8 GW
 SG_ BMS_BattTempSensorNum9 : 7|8@0+ (1,-40) [-40|120] "℃" TBOX
 SG_ BMS_BattTempSensorNum10 : 15|8@0+ (1,-40) [-40|120] "℃" TBOX
 SG_ BMS_BattTempSensorNum11 : 23|8@0+ (1,-40) [-40|120] "℃" TBOX
 SG_ BMS_BattTempSensorNum12 : 31|8@0+ (1,-40) [-40|120] "℃" TBOX
 SG_ BMS_BattTempSensorNum13 : 39|8@0+ (1,-40) [-40|120] "℃" TBOX
 SG_ BMS_BattTempSensorNum14 : 47|8@0+ (1,-40) [-40|120] "℃" TBOX
 SG_ BMS_BattTempSensorNum15 : 55|8@0+ (1,-40) [-40|120] "℃" TBOX
 SG_ BMS_BattTempSensorNum16 : 63|8@0+ (1,-40) [-40|120] "℃" TBOX

BO_ 1522 BMS_0x5F2: 8 GW
 SG_ BMS_BattTempSensorNum17 : 7|8@0+ (1,-40) [-40|120] "℃" TBOX
 SG_ BMS_BattTempSensorNum18 : 15|8@0+ (1,-40) [-40|120] "℃" TBOX
 SG_ BMS_BattTempSensorNum19 : 23|8@0+ (1,-40) [-40|120] "℃" TBOX
 SG_ BMS_BattTempSensorNum20 : 31|8@0+ (1,-40) [-40|120] "℃" TBOX
 SG_ BMS_BattTempSensorNum21 : 39|8@0+ (1,-40) [-40|120] "℃" TBOX
 SG_ BMS_BattTempSensorNum22 : 47|8@0+ (1,-40) [-40|120] "℃" TBOX
 SG_ BMS_BattTempSensorNum23 : 55|8@0+ (1,-40) [-40|120] "℃" TBOX
 SG_ BMS_BattTempSensorNum24 : 63|8@0+ (1,-40) [-40|120] "℃" TBOX

BO_ 1523 BMS_0x5F3: 8 GW
 SG_ BMS_BattTempSensorNum25 : 7|8@0+ (1,-40) [-40|120] "℃" TBOX
 SG_ BMS_BattTempSensorNum26 : 15|8@0+ (1,-40) [-40|120] "℃" TBOX
 SG_ BMS_BattTempSensorNum27 : 23|8@0+ (1,-40) [-40|120] "℃" TBOX
 SG_ BMS_BattTempSensorNum28 : 31|8@0+ (1,-40) [-40|120] "℃" TBOX
 SG_ BMS_BattTempSensorNum29 : 39|8@0+ (1,-40) [-40|120] "℃" TBOX
 SG_ BMS_BattTempSensorNum30 : 47|8@0+ (1,-40) [-40|120] "℃" TBOX
 SG_ BMS_BattTempSensorNum31 : 55|8@0+ (1,-40) [-40|120] "℃" TBOX
 SG_ BMS_BattTempSensorNum32 : 63|8@0+ (1,-40) [-40|120] "℃" TBOX

BO_ 1524 BMS_0x5F4: 8 GW
 SG_ BMS_BattTempSensorNum33 : 7|8@0+ (1,-40) [-40|120] "℃" TBOX
 SG_ BMS_BattTempSensorNum34 : 15|8@0+ (1,-40) [-40|120] "℃" TBOX
 SG_ BMS_BattTempSensorNum35 : 23|8@0+ (1,-40) [-40|120] "℃" TBOX
 SG_ BMS_BattTempSensorNum36 : 31|8@0+ (1,-40) [-40|120] "℃" TBOX
 SG_ BMS_BattTempSensorNum37 : 39|8@0+ (1,-40) [-40|120] "℃" TBOX
 SG_ BMS_BattTempSensorNum38 : 47|8@0+ (1,-40) [-40|120] "℃" TBOX
 SG_ BMS_BattTempSensorNum39 : 55|8@0+ (1,-40) [-40|120] "℃" TBOX
 SG_ BMS_BattTempSensorNum40 : 63|8@0+ (1,-40) [-40|120] "℃" TBOX

BO_ 1473 GW_TBOX_0x5C1_Version: 8 GW
 SG_ GW_SWVersion_Supplier : 3|4@0+ (1,0) [0|15] "" TBOX
 SG_ GW_SWVersion_Main : 7|4@0+ (1,0) [0|15] "" TBOX
 SG_ GW_SWVersion_Sub1 : 11|4@0+ (1,0) [0|15] "" TBOX
 SG_ GW_SWVersion_Sub2 : 15|4@0+ (1,0) [0|15] "" TBOX
 SG_ GW_HWVersion_Supplier : 19|4@0+ (1,0) [0|15] "" TBOX
 SG_ GW_HWVersion_Main : 23|4@0+ (1,0) [0|15] "" TBOX
 SG_ GW_HWVersion_Sub1 : 27|4@0+ (1,0) [0|15] "" TBOX
 SG_ GW_HWVersion_Sub2 : 31|4@0+ (1,0) [0|15] "" TBOX

CM_ SG_ 665 CSW_Key_StartStop "一键启动按钮状态，BCM接收LIN2子网报文CSW_0x21的信号CSW_Key_StartStop转发至Body CAN";
CM_ SG_ 665 CSW_Key_AutoParking "自动泊车按钮状态，BCM接收LIN2子网报文CSW_0x21的信号CSW_Key_AutoParking转发至Body CAN";
CM_ SG_ 665 CSW_Key_LiftGate "后背门开启按钮状态，BCM接收LIN2子网报文CSW_0x21的信号CSW_Key_LiftGate转发至Body CAN";
CM_ SG_ 665 CSW_WindowLOCK "车窗锁止按钮状态，BCM接收LIN2子网报文CSW_0x21的信号CSW_WindowLOCK转发至Body CAN";
CM_ SG_ 665 CSW_Key_FrontDefrost "前风窗除雾按钮状态，BCM接收LIN2子网报文CSW_0x21的信号CSW_Key_FrontDefrost转发至Body CAN";
CM_ SG_ 665 ESCL_DiagError "ESCL Diag Error，BCM接收LIN2子网报文ESCL_0x3B的信号ESCL_DiagError转发至Body CAN";
CM_ SG_ 665 ESCL_authentification_error "ESCL authentification error，BCM接收LIN2子网报文ESCL_0x3B的信号ESCL_authentification_error转发至Body CAN";
CM_ SG_ 665 ESCL_unlock_status "ESCL unlock status，BCM接收LIN2子网报文ESCL_0x3B的信号ESCL_unlock_status转发至Body CAN";
CM_ SG_ 665 ESCL_lock_status "ESCL lock status，BCM接收LIN2子网报文ESCL_0x3B的信号ESCL_lock_status转发至Body CAN";
CM_ SG_ 665 FLWM_WinPstSt "FLWindow Position Status，BCM接收LIN3子网报文FLWM_0x31的信号FLWM_WinPstSt转发至Body CAN";
CM_ SG_ 665 FLWM_AntiPinchDetecte "FLWindow检测到防夹，或正在进行防夹操作，BCM接收LIN3子网报文FLWM_0x31的信号FLWM_AntiPinchDetecte转发至Body CAN";
CM_ SG_ 665 FRWM_WinPstSt "FRWindow Position Status，BCM接收LIN3子网报文FRWM_0x32的信号FRWM_WinPstSt转发至Body CAN";
CM_ SG_ 665 FRWM_AntiPinchDetecte "FRWindow检测到防夹，或正在进行防夹操作，BCM接收LIN3子网报文FRWM_0x32的信号FRWM_AntiPinchDetecte转发至Body CAN";
CM_ SG_ 665 RLWM_WinPstSt "RLWindow Position Status，BCM接收LIN3子网报文RLWM_0x33的信号RLWM_WinPstStp转发至Body CAN";
CM_ SG_ 665 RLWM_AntiPinchDetecte "RLWindow检测到防夹，或正在进行防夹操作，BCM接收LIN3子网报文RLWM_0x33的信号RLWM_AntiPinchDetecte转发至Body CAN";
CM_ SG_ 665 RRWM_WinPstSt "RRWindow Position Status，BCM接收LIN3子网报文RRWM_0x34的信号RRWM_WinPstSt转发至Body CAN";
CM_ SG_ 665 RRWM_AntiPinchDetecte "RRWindow检测到防夹，或正在进行防夹操作，BCM接收LIN3子网报文RRWM_0x34的信号RRWM_AntiPinchDetect转发至Body CAN";
CM_ SG_ 665 FLWM_Opend "左前车窗是否完全打开，BCM接收LIN3子网报文FLWM_0x31的信号FLWM_Opend转发至Body CAN";
CM_ SG_ 665 FLWM_Closed "左前车窗是否完全关闭，BCM接收LIN3子网报文FLWM_0x31的信号FLWM_Closed转发至Body CAN";
CM_ SG_ 665 FRWM_Opend "右前车窗是否完全打开，BCM接收LIN3子网报文FRWM_0x32的信号FRWM_Opend转发至Body CAN";
CM_ SG_ 665 FRWM_Closed "右前车窗是否完全关闭，BCM接收LIN3子网报文FRWM_0x32的信号FRWM_Closed转发至Body CAN";
CM_ SG_ 665 RLWM_Opend "左后车窗是否完全打开，BCM接收LIN3子网报文RLWM_0x33的信号RLWM_Opend转发至Body CAN";
CM_ SG_ 665 RLWM_Closed "左后车窗是否完全关闭，BCM接收LIN3子网报文RLWM_0x33的信号RLWM_Closed转发至Body CAN";
CM_ SG_ 665 RRWM_Opend "右后车窗是否完全打开，BCM接收LIN3子网报文RRWM_0x34的信号RRWM_Opend转发至Body CAN";
CM_ SG_ 665 RRWM_Closed "右后车窗是否完全关闭，BCM接收LIN3子网报文RRWM_0x34的信号RRWM_Closed转发至Body CAN";
CM_ SG_ 665 FLWM_WinMoveSt "FLWindow move Status，BCM接收LIN3子网报文FLWM_0x31的信号FLWM_WinMoveSt转发至Body CAN";
CM_ SG_ 665 FRWM_WinMoveSt "FRWindow move Status，BCM接收LIN3子网报文FRWM_0x32的信号FRWM_WinMoveSt转发至Body CAN";
CM_ SG_ 665 RLWM_WinMoveSt "RLWindow move Status，BCM接收LIN3子网报文RLWM_0x33的信号RLWM_WinMoveSt转发至Body CAN";
CM_ SG_ 665 RRWM_WinMoveSt "RRWindow move Status，BCM接收LIN3子网报文RRWM_0x34的信号RRWM_WinMoveStp转发至Body CAN";
CM_ SG_ 583 BCM_StartWarning "启动异常提醒";
CM_ SG_ 583 BCM_PowerOffWarning "下OFF异常提醒";
CM_ SG_ 583 BCM_PowerONWarning "上电异常提醒";
CM_ SG_ 583 BCM_AuthSts "BCM一级防盗认证结果";
CM_ SG_ 583 BCM_ESCLSysFail "ESCL系统故障提醒";
CM_ SG_ 583 BCM_LODO_Reminder "灯关未关闭提醒";
CM_ SG_ 583 BCM_brakeLightfail "刹车灯故障提示";
CM_ SG_ 1282 TPMS_FL_Warning_Sts "左前胎压报警状态";
CM_ SG_ 1282 TPMS_FR_Warning_Sts "右前胎压报警状态";
CM_ SG_ 1282 TPMS_RL_Warning_Sts "左后胎压报警状态";
CM_ SG_ 1282 TPMS_RR_Warning_Sts "右后胎压报警状态";
CM_ SG_ 1282 TPMS_FL_Fault_Sts "左前胎压故障状态";
CM_ SG_ 1282 TPMS_FR_Fault_Sts "右前胎压故障状态";
CM_ SG_ 1282 TPMS_RL_Fault_Sts "左后胎压故障状态";
CM_ SG_ 1282 TPMS_RR_Fault_Sts "右后胎压故障状态";
CM_ SG_ 1282 TPMS_FL_leakage_Sts "左前轮胎漏气状态";
CM_ SG_ 1282 TPMS_FR_leakage_Sts "右前轮胎漏气状态";
CM_ SG_ 1282 TPMS_RL_leakage_Sts "左后轮胎漏气状态";
CM_ SG_ 1282 TPMS_RR_leakage_Sts "右后轮胎漏气状态";
CM_ SG_ 1282 TPMS_FLPressure_Sts "左前轮胎胎压状态";
CM_ SG_ 1282 TPMS_FRPressure_Sts "右前轮胎胎压状态";
CM_ SG_ 1282 TPMS_RLPressure_Sts "左后轮胎胎压状态";
CM_ SG_ 1282 TPMS_RRPressure_Sts "右后轮胎胎压状态";
CM_ SG_ 1282 TPMS_FL_HighTemp_Sts "左前高温报警状态";
CM_ SG_ 1282 TPMS_FR_HighTemp_Sts "右前高温报警状态";
CM_ SG_ 1282 TPMS_RL_HighTemp_Sts "左后高温报警状态";
CM_ SG_ 1282 TPMS_RR_HighTemp_Sts "右后高温报警状态";
CM_ SG_ 1282 TPMS_FL_battery_Sts "左前电池电量低报警状态";
CM_ SG_ 1282 TPMS_FR_battery_Sts "右前电池电量低报警状态";
CM_ SG_ 1282 TPMS_RL_battery_Sts "左后电池电量低报警状态";
CM_ SG_ 1282 TPMS_RR_battery_Sts "右后电池电量低报警状态";
CM_ SG_ 1282 TPMS_FL_SensorError_Sts "左前胎压传感器信号故障";
CM_ SG_ 1282 TPMS_FR_SensorError_Sts "右前胎压传感器信号故障";
CM_ SG_ 1282 TPMS_RL_SensorError_Sts "左后胎压传感器信号故障";
CM_ SG_ 1282 TPMS_RR_SensorError_Sts "右后胎压传感信号故障";
CM_ SG_ 1282 TPMS_FL_failure_Sts "左前传感器信号丢失";
CM_ SG_ 1282 TPMS_FR_failure_Sts "右前传感器信号丢失";
CM_ SG_ 1282 TPMS_RL_failure_Sts "左后传感器信号丢失";
CM_ SG_ 1282 TPMS_RR_failure_Sts "右后传感器信号丢失";
CM_ SG_ 1282 TPMS_FL_learn_Sts "左前匹配状态";
CM_ SG_ 1282 TPMS_FR_learn_Sts "右前匹配状态";
CM_ SG_ 1282 TPMS_RL_learn_Sts "左后匹配状态";
CM_ SG_ 1282 TPMS_RR_learn_Sts "右后匹配状态";
CM_ SG_ 1282 TPMS_FL_CRC_Error "TPMS FL传感器数据CRC校验错误";
CM_ SG_ 1282 TPMS_FR_CRC_Error "TPMS FR传感器数据CRC校验错误";
CM_ SG_ 1282 TPMS_RL_CRC_Error "TPMS RL传感器数据CRC校验错误";
CM_ SG_ 1282 TPMS_RR_CRC_Error "TPMS RR传感器数据CRC校验错误";
CM_ SG_ 277 BMS_MaxDschPower "电池最大可持续放电功率";
CM_ SG_ 277 BMS_MaxDschPowerPeak "电池最大峰值放电功率";
CM_ SG_ 277 BMS_DschAllowedPower "电池允许放电功率";
CM_ SG_ 277 BMS_MaxChrgPowerPeak "电池最大峰值充电功率";
CM_ SG_ 277 BMS_MaxChrgPower "电池最大可持续充电功率";
CM_ SG_ 277 BMS_ChrgAllowedPower "电池允许充电功率";
CM_ SG_ 277 BMS_0x115_RollingCounter "从0到15循环计数，如果通信中断，则重新从0开始计数。";
CM_ SG_ 1632 DCDC_OverTemp "温度保护";
CM_ SG_ 1632 DCDC_DischargeFail "主动放电失败";
CM_ SG_ 1632 DCDC_TBOX_WorkSts "DCDC状态报警";
CM_ SG_ 1632 DCDC_TBOX_TempFault "DCDC温度报警";
CM_ SG_ 1632 DCDC_InsideVolHig "母线过压";
CM_ SG_ 1632 DCDC_InsideVolLow "母线欠压";
CM_ SG_ 1632 DCDC_OutputCurHig "输出过流";
CM_ SG_ 1632 DCDC_OutputVolHig "输出过压";
CM_ SG_ 1632 DCDC_OutputVolLow "输出欠压";
CM_ SG_ 1632 DCDC_InputCurHig "输入过流";
CM_ SG_ 1632 DCDC_InputVolHig "输入过压";
CM_ SG_ 1632 DCDC_InputVolLow "输入欠压";
CM_ SG_ 1632 DCDC_OutputOpen "输出断路";
CM_ SG_ 1632 DCDC_HardFail "硬件故障";
CM_ SG_ 1632 DCDC_InsideShotCirc "内部母线短路";
CM_ SG_ 1632 DCDC_OutputShotCirc "输出短路";
CM_ SG_ 1632 DCDC_CommunTimeOut "通信超时";
CM_ SG_ 1632 DCDC_InsideCurHig "谐振腔电流过大";
CM_ SG_ 261 BMS_PackSOH "电池生命健康度";
CM_ SG_ 261 BMS_ChrRequestU "充电电压请求";
CM_ SG_ 261 BMS_ChrRequest "充电请求";
CM_ SG_ 261 BMS_ChrRequestI "充电电流请求";
CM_ SG_ 261 BMS_VCU_TotalEnergy "总能耗";
CM_ SG_ 261 BMS_0x105_RollingCounter "从0到15循环计数，如果通信中断，则重新从0开始计数。";
CM_ SG_ 1556 OBC_ChrgInsOutputVolt "OBC inside output votage reported
OBC内侧输出电压";
CM_ SG_ 1556 OBC_TempAct "actual temperature of OBC
OBC实际温度";
CM_ SG_ 1556 OBC_ElockSts "E-lock status
电子锁状态";
CM_ SG_ 1556 OBC_ChrgLockSts "E-lock status
电子锁状态";
CM_ SG_ 1556 OBC_RecoTimingSts "电子锁故障显示计时状态";
CM_ SG_ 1553 OBC_SocketTempHig "充电插座过温保护";
CM_ SG_ 1553 OBC_InputVolLow "输入欠压";
CM_ SG_ 1553 OBC_HardTempHig "过温保护";
CM_ SG_ 1553 OBC_OutputShorCir "输出短路";
CM_ SG_ 1553 OBC_OutputVolHig "输出电压过高";
CM_ SG_ 1553 OBC_OutputVolLow "输出电压过低";
CM_ SG_ 1553 OBC_PFCOutputVolHig "PFC输出电压过高";
CM_ SG_ 1553 OBC_PFCOutputVolLow "PFC输出电压过低";
CM_ SG_ 1553 OBC_CommTimeOut "CAN通讯超时";
CM_ SG_ 1553 OBC_InputCurHig "输入电流过大";
CM_ SG_ 1553 OBC_InputVolHig "输入电压过高";
CM_ SG_ 1553 OBC_BMSVolLow "BMS电压过低";
CM_ SG_ 1553 OBC_BMSVolHig "BMS电压过高";
CM_ SG_ 1553 OBC_ContraryConnect "反接保护";
CM_ SG_ 1553 OBC_InsideComTimeOut "内部通讯超时";
CM_ SG_ 1553 OBC_ElockFail "电子锁故障";
CM_ SG_ 1553 OBC_HardFail "硬件故障";
CM_ SG_ 1553 OBC_OutputCurHig "输出电流过大";
CM_ SG_ 1553 OBC_SoketTemp_N "Soceket temperature reported
充电插座负极温度";
CM_ SG_ 1553 OBC_CoolantPlateTemp "Coolant temperature reported
冷却水温";
CM_ SG_ 1553 OBC_SoketTemp_L "Soceket temperature reported
充电插座正极温度";
CM_ SG_ 1552 Checksum_0x610 "Checksum: IDMSB XOR IDLSB XOR Byte1 XOR Byte2 XOR Byte3 XOR Byte4 XOR Byte5 XOR Byte6XOR Byte7";
CM_ SG_ 1552 OBC_InputCurrAbility "Input current availibility
输入电流能力";
CM_ SG_ 1552 OBC_ChgInputCurrent "Input current report
输入电流";
CM_ SG_ 1552 OBC_ChgInputVoltage "Input voltage report
输入电压";
CM_ SG_ 1552 OBC_CP_Duty "CP占空比";
CM_ SG_ 1552 Rolling_counter_0x610 "RollingCounter: used 4bit length signal and the arithmetic is increased from 0 to 15 by every message.";
CM_ SG_ 1552 OBC_CC_Status "CC电阻值";
CM_ SG_ 1360 Checksum_0x550 "Checksum: IDMSB XOR IDLSB XOR Byte1 XOR Byte2 XOR Byte3 XOR Byte4 XOR Byte5 XOR Byte6XOR Byte7";
CM_ SG_ 1360 OBC_ChrgOutputVolt "OBC output votage reported
OBC输出电压";
CM_ SG_ 1360 OBC_ChrgFailLevel "OBC fault class
OBC故障等级";
CM_ SG_ 1360 OBC_CCLineSts "CC signal connect status
CC信号连接状态";
CM_ SG_ 1360 OBC_DeratingSts "OBC derating status
OBC降额状态
";
CM_ SG_ 1360 OBC_ChrgSts "OBC state machine mode
OBC 状态机";
CM_ SG_ 1360 OBC_ChrgEffciency "OBC real-time efficiency
OBC真实效率";
CM_ SG_ 1360 OBC_ChrgOutputCurr "OBC output current reported
OBC输出电流";
CM_ SG_ 1360 OBC_OBCStsCPLine "CP signal connect status
CP信号连接状态";
CM_ SG_ 1360 Rolling_counter_0x550 "RollingCounter: used 4bit length signal and the arithmetic is increased from 0 to 15 by every message.";
CM_ SG_ 1360 OBC_S2Sts "S2 switch status
S2开关状态";
CM_ SG_ 1360 OBC_ChrgAllowedSts "OBC允许充电";
CM_ SG_ 392 Checksum_0x188 "Checksum: IDMSB XOR IDLSB XOR Byte1 XOR Byte2 XOR Byte3 XOR Byte4 XOR Byte5 XOR Byte6XOR Byte7";
CM_ SG_ 392 DCDC_ErrorLevel "DCDC故障等级";
CM_ SG_ 392 DCDC_stMode "stMode of DCDC
DCDC工作模式";
CM_ SG_ 392 DCDC_DischargeMode "DischargeMode of DCDC
DCDC主动泄放状态";
CM_ SG_ 392 DCDC_IdcLvCurr "Low side current of DCDC
DCDC低压输出电流";
CM_ SG_ 392 DCDC_IdcHvCurr "High side  current of DCDC
DCDC高压输入电流";
CM_ SG_ 392 DCDC_UdcLvVolt "Low side voltage of DCDC
DCDC低压输出电压";
CM_ SG_ 392 DCDC_UdcHvVolt "High side  voltage of DCDC
DCDC高压输入电压";
CM_ SG_ 905 Checksum_0x389 "Checksum: IDMSB XOR IDLSB XOR Byte1 XOR Byte2 XOR Byte3 XOR Byte4 XOR Byte5 XOR Byte6XOR Byte7";
CM_ SG_ 905 DCDC_DeratingSts "DCDC derating status
DCDC降额状态";
CM_ SG_ 905 DCDC_rUtilRateDFM "utilization of DCDC, corresponds to I_act / I_max
实际电流与最大电流的比值";
CM_ SG_ 905 DCDC_TempAct "actual temperature of DCDC(for VCU pump control)
DCDC实际温度（VCU水泵控制）";
CM_ SG_ 905 Counter_0x389 "Message rolling counter.";
CM_ SG_ 1512 ESP_SWVersion_Supplier "ESP软件供应商代码（有电咖定义，如A/B/C分别代表A点/B点/C点供应商，定义参考诊断规范版本号定义）";
CM_ SG_ 1512 ESP_SWVersion_Main "ESP软件版本-大版本";
CM_ SG_ 1512 ESP_SWVersion_Sub1 "ESP软件版本-小版本第一位";
CM_ SG_ 1512 ESP_SWVersion_Sub2 "ESP软件版本-小版本第二位";
CM_ SG_ 1512 ESP_HWVersion_Supplier "ESP硬件件供应商代码";
CM_ SG_ 1512 ESP_HWVersion_Main "ESP硬件版本-大版本";
CM_ SG_ 1512 ESP_HWVersion_Sub1 "ESP硬件版本-小版本第一位";
CM_ SG_ 1512 ESP_HWVersion_Sub2 "ESP硬件版本-小版本第二位";
CM_ SG_ 1513 EPS_SWVersion_Supplier "EPS软件供应商代码（有电咖定义，如A/B/C分别代表A点/B点/C点供应商，定义参考诊断规范版本号定义）";
CM_ SG_ 1513 EPS_SWVersion_Main "EPS软件版本-大版本";
CM_ SG_ 1513 EPS_SWVersion_Sub1 "EPS软件版本-小版本第一位";
CM_ SG_ 1513 EPS_SWVersion_Sub2 "EPS软件版本-小版本第二位";
CM_ SG_ 1513 EPS_HWVersion_Supplier "EPS硬件件供应商代码";
CM_ SG_ 1513 EPS_HWVersion_Main "EPS硬件版本-大版本";
CM_ SG_ 1513 EPS_HWVersion_Sub1 "EPS硬件版本-小版本第一位";
CM_ SG_ 1513 EPS_HWVersion_Sub2 "EPS硬件版本-小版本第二位";
CM_ SG_ 1514 MPC_SWVersion_Supplier "MPC软件供应商代码（有电咖定义，如A/B/C分别代表A点/B点/C点供应商，定义参考诊断规范版本号定义）";
CM_ SG_ 1514 MPC_SWVersion_Main "MPC软件版本-大版本";
CM_ SG_ 1514 MPC_SWVersion_Sub1 "MPC软件版本-小版本第一位";
CM_ SG_ 1514 MPC_SWVersion_Sub2 "MPC软件版本-小版本第二位";
CM_ SG_ 1514 MPC_HWVersion_Supplier "MPC硬件件供应商代码";
CM_ SG_ 1514 MPC_HWVersion_Main "MPC硬件版本-大版本";
CM_ SG_ 1514 MPC_HWVersion_Sub1 "MPC硬件版本-小版本第一位";
CM_ SG_ 1514 MPC_HWVersion_Sub2 "MPC硬件版本-小版本第二位";
CM_ SG_ 1515 MRR_SWVersion_Supplier "MRR软件供应商代码（有电咖定义，如A/B/C分别代表A点/B点/C点供应商，定义参考诊断规范版本号定义）";
CM_ SG_ 1515 MRR_SWVersion_Main "MRR软件版本-大版本";
CM_ SG_ 1515 MRR_SWVersion_Sub1 "MRR软件版本-小版本第一位";
CM_ SG_ 1515 MRR_SWVersion_Sub2 "MRR软件版本-小版本第二位";
CM_ SG_ 1515 MRR_HWVersion_Supplier "MRR硬件件供应商代码";
CM_ SG_ 1515 MRR_HWVersion_Main "MRR硬件版本-大版本";
CM_ SG_ 1515 MRR_HWVersion_Sub1 "MRR硬件版本-小版本第一位";
CM_ SG_ 1515 MRR_HWVersion_Sub2 "MRR硬件版本-小版本第二位";
CM_ SG_ 1516 APS_SWVersion_Supplier "APS软件供应商代码（有电咖定义，如A/B/C分别代表A点/B点/C点供应商，定义参考诊断规范版本号定义）";
CM_ SG_ 1516 APS_SWVersion_Main "APS软件版本-大版本";
CM_ SG_ 1516 APS_SWVersion_Sub1 "APS软件版本-小版本第一位";
CM_ SG_ 1516 APS_SWVersion_Sub2 "APS软件版本-小版本第二位";
CM_ SG_ 1516 APS_HWVersion_Supplier "APS硬件件供应商代码";
CM_ SG_ 1516 APS_HWVersion_Main "APS硬件版本-大版本";
CM_ SG_ 1516 APS_HWVersion_Sub1 "APS硬件版本-小版本第一位";
CM_ SG_ 1516 APS_HWVersion_Sub2 "APS硬件版本-小版本第二位";
CM_ SG_ 1517 AFS_SWVersion_Supplier "AFS软件供应商代码（有电咖定义，如A/B/C分别代表A点/B点/C点供应商，定义参考诊断规范版本号定义）";
CM_ SG_ 1517 AFS_SWVersion_Main "AFS软件版本-大版本";
CM_ SG_ 1517 AFS_SWVersion_Sub1 "AFS软件版本-小版本第一位";
CM_ SG_ 1517 AFS_SWVersion_Sub2 "AFS软件版本-小版本第二位";
CM_ SG_ 1517 AFS_HWVersion_Supplier "AFS硬件件供应商代码";
CM_ SG_ 1517 AFS_HWVersion_Main "AFS硬件版本-大版本";
CM_ SG_ 1517 AFS_HWVersion_Sub1 "AFS硬件版本-小版本第一位";
CM_ SG_ 1517 AFS_HWVersion_Sub2 "AFS硬件版本-小版本第二位";
CM_ SG_ 1518 SCM_SWVersion_Supplier "SCM软件供应商代码（有电咖定义，如A/B/C分别代表A点/B点/C点供应商，定义参考诊断规范版本号定义）";
CM_ SG_ 1518 SCM_SWVersion_Main "SCM软件版本-大版本";
CM_ SG_ 1518 SCM_SWVersion_Sub1 "SCM软件版本-小版本第一位";
CM_ SG_ 1518 SCM_SWVersion_Sub2 "SCM软件版本-小版本第二位";
CM_ SG_ 1518 SCM_HWVersion_Supplier "SCM硬件件供应商代码";
CM_ SG_ 1518 SCM_HWVersion_Main "SCM硬件版本-大版本";
CM_ SG_ 1518 SCM_HWVersion_Sub1 "SCM硬件版本-小版本第一位";
CM_ SG_ 1518 SCM_HWVersion_Sub2 "SCM硬件版本-小版本第二位";
CM_ SG_ 1488 HU_SWVersion_Supplier "HU软件供应商代码（有电咖定义，如A/B/C分别代表A点/B点/C点供应商，定义参考诊断规范版本号定义）";
CM_ SG_ 1488 HU_SWVersion_Main "HU软件版本-大版本";
CM_ SG_ 1488 HU_SWVersion_Sub1 "HU软件版本-小版本第一位";
CM_ SG_ 1488 HU_SWVersion_Sub2 "HU软件版本-小版本第二位";
CM_ SG_ 1488 HU_HWVersion_Supplier "HU硬件件供应商代码";
CM_ SG_ 1488 HU_HWVersion_Main "HU硬件版本-大版本";
CM_ SG_ 1488 HU_HWVersion_Sub1 "HU硬件版本-小版本第一位";
CM_ SG_ 1488 HU_HWVersion_Sub2 "HU硬件版本-小版本第二位";
CM_ SG_ 1489 SDAL_SWVersion_Supplier "SDAL软件供应商代码（有电咖定义，如A/B/C分别代表A点/B点/C点供应商，定义参考诊断规范版本号定义）";
CM_ SG_ 1489 SDAL_SWVersion_Main "SDAL软件版本-大版本";
CM_ SG_ 1489 SDAL_SWVersion_Sub1 "SDAL软件版本-小版本第一位";
CM_ SG_ 1489 SDAL_SWVersion_Sub2 "SDAL软件版本-小版本第二位";
CM_ SG_ 1489 SDAL_HWVersion_Supplier "SDAL硬件件供应商代码";
CM_ SG_ 1489 SDAL_HWVersion_Main "SDAL硬件版本-大版本";
CM_ SG_ 1489 SDAL_HWVersion_Sub1 "SDAL硬件版本-小版本第一位";
CM_ SG_ 1489 SDAL_HWVersion_Sub2 "SDAL硬件版本-小版本第二位";
CM_ SG_ 1490 DVR_SWVersion_Supplier "DVR软件供应商代码（有电咖定义，如A/B/C分别代表A点/B点/C点供应商，定义参考诊断规范版本号定义）";
CM_ SG_ 1490 DVR_SWVersion_Main "DVR软件版本-大版本";
CM_ SG_ 1490 DVR_SWVersion_Sub1 "DVR软件版本-小版本第一位";
CM_ SG_ 1490 DVR_SWVersion_Sub2 "DVR软件版本-小版本第二位";
CM_ SG_ 1490 DVR_HWVersion_Supplier "DVR硬件件供应商代码";
CM_ SG_ 1490 DVR_HWVersion_Main "DVR硬件版本-大版本";
CM_ SG_ 1490 DVR_HWVersion_Sub1 "DVR硬件版本-小版本第一位";
CM_ SG_ 1490 DVR_HWVersion_Sub2 "DVR硬件版本-小版本第二位";
CM_ SG_ 1491 RSE_SWVersion_Supplier "RSE软件供应商代码（有电咖定义，如A/B/C分别代表A点/B点/C点供应商，定义参考诊断规范版本号定义）";
CM_ SG_ 1491 RSE_SWVersion_Main "RSE软件版本-大版本";
CM_ SG_ 1491 RSE_SWVersion_Sub1 "RSE软件版本-小版本第一位";
CM_ SG_ 1491 RSE_SWVersion_Sub2 "RSE软件版本-小版本第二位";
CM_ SG_ 1491 RSE_HWVersion_Supplier "RSE硬件件供应商代码";
CM_ SG_ 1491 RSE_HWVersion_Main "RSE硬件版本-大版本";
CM_ SG_ 1491 RSE_HWVersion_Sub1 "RSE硬件版本-小版本第一位";
CM_ SG_ 1491 RSE_HWVersion_Sub2 "RSE硬件版本-小版本第二位";
CM_ SG_ 1496 APL_SWVersion_Supplier "APL软件供应商代码（有电咖定义，如A/B/C分别代表A点/B点/C点供应商，定义参考诊断规范版本号定义）";
CM_ SG_ 1496 APL_SWVersion_Main "APL软件版本-大版本";
CM_ SG_ 1496 APL_SWVersion_Sub1 "APL软件版本-小版本第一位";
CM_ SG_ 1496 APL_SWVersion_Sub2 "APL软件版本-小版本第二位";
CM_ SG_ 1496 APL_HWVersion_Supplier "APL硬件件供应商代码";
CM_ SG_ 1496 APL_HWVersion_Main "APL硬件版本-大版本";
CM_ SG_ 1496 APL_HWVersion_Sub1 "APL硬件版本-小版本第一位";
CM_ SG_ 1496 APL_HWVersion_Sub2 "APL硬件版本-小版本第二位";
CM_ SG_ 1497 AC_SWVersion_Supplier "AC软件供应商代码（有电咖定义，如A/B/C分别代表A点/B点/C点供应商，定义参考诊断规范版本号定义）";
CM_ SG_ 1497 AC_SWVersion_Main "AC软件版本-大版本";
CM_ SG_ 1497 AC_SWVersion_Sub1 "AC软件版本-小版本第一位";
CM_ SG_ 1497 AC_SWVersion_Sub2 "AC软件版本-小版本第二位";
CM_ SG_ 1497 AC_HWVersion_Supplier "AC硬件件供应商代码";
CM_ SG_ 1497 AC_HWVersion_Main "AC硬件版本-大版本";
CM_ SG_ 1497 AC_HWVersion_Sub1 "AC硬件版本-小版本第一位";
CM_ SG_ 1497 AC_HWVersion_Sub2 "AC硬件版本-小版本第二位";
CM_ SG_ 1498 EAC_SWVersion_Supplier "EAC软件供应商代码（有电咖定义，如A/B/C分别代表A点/B点/C点供应商，定义参考诊断规范版本号定义）";
CM_ SG_ 1498 EAC_SWVersion_Main "EAC软件版本-大版本";
CM_ SG_ 1498 EAC_SWVersion_Sub1 "EAC软件版本-小版本第一位";
CM_ SG_ 1498 EAC_SWVersion_Sub2 "EAC软件版本-小版本第二位";
CM_ SG_ 1498 EAC_HWVersion_Supplier "EAC硬件件供应商代码";
CM_ SG_ 1498 EAC_HWVersion_Main "EAC硬件版本-大版本";
CM_ SG_ 1498 EAC_HWVersion_Sub1 "EAC硬件版本-小版本第一位";
CM_ SG_ 1498 EAC_HWVersion_Sub2 "EAC硬件版本-小版本第二位";
CM_ SG_ 1499 APTC_SWVersion_Supplier "APTC软件供应商代码（有电咖定义，如A/B/C分别代表A点/B点/C点供应商，定义参考诊断规范版本号定义）";
CM_ SG_ 1499 APTC_SWVersion_Main "APTC软件版本-大版本";
CM_ SG_ 1499 APTC_SWVersion_Sub1 "APTC软件版本-小版本第一位";
CM_ SG_ 1499 APTC_SWVersion_Sub2 "APTC软件版本-小版本第二位";
CM_ SG_ 1499 APTC_HWVersion_Supplier "APTC硬件件供应商代码";
CM_ SG_ 1499 APTC_HWVersion_Main "APTC硬件版本-大版本";
CM_ SG_ 1499 APTC_HWVersion_Sub1 "APTC硬件版本-小版本第一位";
CM_ SG_ 1499 APTC_HWVersion_Sub2 "APTC硬件版本-小版本第二位";
CM_ SG_ 1519 ICM_SWVersion_Supplier "ICM软件供应商代码（有电咖定义，如A/B/C分别代表A点/B点/C点供应商，定义参考诊断规范版本号定义）";
CM_ SG_ 1519 ICM_SWVersion_Main "ICM软件版本-大版本";
CM_ SG_ 1519 ICM_SWVersion_Sub1 "ICM软件版本-小版本第一位";
CM_ SG_ 1519 ICM_SWVersion_Sub2 "ICM软件版本-小版本第二位";
CM_ SG_ 1519 ICM_HWVersion_Supplier "ICM硬件件供应商代码";
CM_ SG_ 1519 ICM_HWVersion_Main "ICM硬件版本-大版本";
CM_ SG_ 1519 ICM_HWVersion_Sub1 "ICM硬件版本-小版本第一位";
CM_ SG_ 1519 ICM_HWVersion_Sub2 "ICM硬件版本-小版本第二位";
CM_ SG_ 1776 ORM_SWVersion_Supplier "ORM软件供应商代码（有电咖定义，如A/B/C分别代表A点/B点/C点供应商，定义参考诊断规范版本号定义）";
CM_ SG_ 1776 ORM_SWVersion_Main "ORM软件版本-大版本";
CM_ SG_ 1776 ORM_SWVersion_Sub1 "ORM软件版本-小版本第一位";
CM_ SG_ 1776 ORM_SWVersion_Sub2 "ORM软件版本-小版本第二位";
CM_ SG_ 1776 ORM_HWVersion_Supplier "ORM硬件件供应商代码";
CM_ SG_ 1776 ORM_HWVersion_Main "ORM硬件版本-大版本";
CM_ SG_ 1776 ORM_HWVersion_Sub1 "ORM硬件版本-小版本第一位";
CM_ SG_ 1776 ORM_HWVersion_Sub2 "ORM硬件版本-小版本第二位";
CM_ SG_ 1493 DSM_SWVersion_Supplier "DSM软件供应商代码（有电咖定义，如A/B/C分别代表A点/B点/C点供应商，定义参考诊断规范版本号定义）";
CM_ SG_ 1493 DSM_SWVersion_Main "DSM软件版本-大版本";
CM_ SG_ 1493 DSM_SWVersion_Sub1 "DSM软件版本-小版本第一位";
CM_ SG_ 1493 DSM_SWVersion_Sub2 "DSM软件版本-小版本第二位";
CM_ SG_ 1493 DSM_HWVersion_Supplier "DSM硬件件供应商代码";
CM_ SG_ 1493 DSM_HWVersion_Main "DSM硬件版本-大版本";
CM_ SG_ 1493 DSM_HWVersion_Sub1 "DSM硬件版本-小版本第一位";
CM_ SG_ 1493 DSM_HWVersion_Sub2 "DSM硬件版本-小版本第二位";
CM_ SG_ 1500 AVAS_SWVersion_Supplier "AVAS软件供应商代码（有电咖定义，如A/B/C分别代表A点/B点/C点供应商，定义参考诊断规范版本号定义）";
CM_ SG_ 1500 AVAS_SWVersion_Main "AVAS软件版本-大版本";
CM_ SG_ 1500 AVAS_SWVersion_Sub1 "AVAS软件版本-小版本第一位";
CM_ SG_ 1500 AVAS_SWVersion_Sub2 "AVAS软件版本-小版本第二位";
CM_ SG_ 1500 AVAS_HWVersion_Supplier "AVAS硬件件供应商代码";
CM_ SG_ 1500 AVAS_HWVersion_Main "AVAS硬件版本-大版本";
CM_ SG_ 1500 AVAS_HWVersion_Sub1 "AVAS硬件版本-小版本第一位";
CM_ SG_ 1500 AVAS_HWVersion_Sub2 "AVAS硬件版本-小版本第二位";
CM_ SG_ 1501 BCM_SWVersion_Supplier "BCM软件供应商代码（有电咖定义，如A/B/C分别代表A点/B点/C点供应商，定义参考诊断规范版本号定义）";
CM_ SG_ 1501 BCM_SWVersion_Main "BCM软件版本-大版本";
CM_ SG_ 1501 BCM_SWVersion_Sub1 "BCM软件版本-小版本第一位";
CM_ SG_ 1501 BCM_SWVersion_Sub2 "BCM软件版本-小版本第二位";
CM_ SG_ 1501 BCM_HWVersion_Supplier "BCM硬件件供应商代码";
CM_ SG_ 1501 BCM_HWVersion_Main "BCM硬件版本-大版本";
CM_ SG_ 1501 BCM_HWVersion_Sub1 "BCM硬件版本-小版本第一位";
CM_ SG_ 1501 BCM_HWVersion_Sub2 "BCM硬件版本-小版本第二位";
CM_ SG_ 1502 PLG_SWVersion_Supplier "PLG软件供应商代码（有电咖定义，如A/B/C分别代表A点/B点/C点供应商，定义参考诊断规范版本号定义）";
CM_ SG_ 1502 PLG_SWVersion_Main "PLG软件版本-大版本";
CM_ SG_ 1502 PLG_SWVersion_Sub1 "PLG软件版本-小版本第一位";
CM_ SG_ 1502 PLG_SWVersion_Sub2 "PLG软件版本-小版本第二位";
CM_ SG_ 1502 PLG_HWVersion_Supplier "PLG硬件件供应商代码";
CM_ SG_ 1502 PLG_HWVersion_Main "PLG硬件版本-大版本";
CM_ SG_ 1502 PLG_HWVersion_Sub1 "PLG硬件版本-小版本第一位";
CM_ SG_ 1502 PLG_HWVersion_Sub2 "PLG硬件版本-小版本第二位";
CM_ SG_ 1504 BMS_SWVersion_Supplier "BMS软件供应商代码（有电咖定义，如A/B/C分别代表A点/B点/C点供应商）";
CM_ SG_ 1504 BMS_SWVersion_Main "BMS软件版本-大版本（A/B/C代表A样/B样/C样件）";
CM_ SG_ 1504 BMS_SWVersion_Sub1 "BMS软件版本-小版本第一位";
CM_ SG_ 1504 BMS_SWVersion_Sub2 "BMS软件版本-小版本第二位";
CM_ SG_ 1504 BMS_HWVersion_Supplier "BMS硬件供应商代码（有电咖定义，如A/B/C分别代表A点/B点/C点供应商）";
CM_ SG_ 1504 BMS_HWVersion_Main "BMS硬件版本-大版本（A/B/C代表A样/B样/C样件）";
CM_ SG_ 1504 BMS_HWVersion_Sub1 "BMS硬件版本-小版本第一位";
CM_ SG_ 1504 BMS_HWVersion_Sub2 "BMS硬件版本-小版本第二位";
CM_ SG_ 1504 BMS_PackEnergy "电池包可用能量";
CM_ SG_ 1504 BMS_CellSupplier "电池包电芯供应商
见信号值描述";
CM_ SG_ 1504 BMS_SoftVersion "BMS内部软件版本号";
CM_ SG_ 1505 VCU_SWVersion_Supplier "VCU软件供应商代码（有电咖定义，如A/B/C分别代表A点/B点/C点供应商）";
CM_ SG_ 1505 VCU_SWVersion_Main "VCU软件版本-大版本";
CM_ SG_ 1505 VCU_SWVersion_Sub1 "VCU软件版本-小版本第一位";
CM_ SG_ 1505 VCU_SWVersion_Sub2 "VCU软件版本-小版本第二位";
CM_ SG_ 1505 VCU_HWVersion_Supplier "VCU硬件供应商代码（有电咖定义，如A/B/C分别代表A点/B点/C点供应商）";
CM_ SG_ 1505 VCU_HWVersion_Main "VCU硬件版本-大版本";
CM_ SG_ 1505 VCU_HWVersion_Sub1 "VCU硬件版本-小版本第一位";
CM_ SG_ 1505 VCU_HWVersion_Sub2 "VCU硬件版本-小版本第二位";
CM_ SG_ 1505 VCU_SoftMainVersion_in "VCU软件主版本号（内部使用）";
CM_ SG_ 1505 VCU_SoftSubVersion_in "VCU软件主子版本号（内部使用）";
CM_ SG_ 1505 VCU_SoftPhase_in "VCU软件阶段（内部使用）";
CM_ SG_ 1505 VCU_SoftPhaseDescription_in "VCU软件阶段说明（内部使用）";
CM_ SG_ 1506 MCU_SWVersion_Supplier "MCU软件供应商代码（有电咖定义，如A/B/C分别代A点/B点/C点供应商）";
CM_ SG_ 1506 MCU_SWVersion_Main "MCU软件版本-大版本";
CM_ SG_ 1506 MCU_SWVersion_Sub1 "MCU软件版本-小版本第一位";
CM_ SG_ 1506 MCU_SWVersion_Sub2 "MCU软件版本-小版本第二位";
CM_ SG_ 1506 MCU_HWVersion_Supplier "MCU硬件供应商代码（有电咖定义，如A/B/C分别代表A点/B点/C点供应商）";
CM_ SG_ 1506 MCU_HWVersion_Main "MCU硬件版本-大版本";
CM_ SG_ 1506 MCU_HWVersion_Sub1 "MCU硬件版本-小版本第一位";
CM_ SG_ 1506 MCU_HWVersion_Sub2 "MCU硬件版本-小版本第二位";
CM_ SG_ 1507 DCDC_SWVersion_Supplier "DCDC软件供应商代码（有电咖定义，如A/B/C分别代表A点/B点/C点供应商，定义参考诊断规范版本号定义）";
CM_ SG_ 1507 DCDC_SWVersion_Main "DCDC软件版本-大版本";
CM_ SG_ 1507 DCDC_SWVersion_Sub1 "DCDC软件版本-小版本第一位";
CM_ SG_ 1507 DCDC_SWVersion_Sub2 "DCDC软件版本-小版本第二位";
CM_ SG_ 1507 DCDC_HWVersion_Supplier "DCDC硬件件供应商代码";
CM_ SG_ 1507 DCDC_HWVersion_Main "DCDC硬件版本-大版本";
CM_ SG_ 1507 DCDC_HWVersion_Sub1 "DCDC硬件版本-小版本第一位";
CM_ SG_ 1507 DCDC_HWVersion_Sub2 "DCDC硬件版本-小版本第二位";
CM_ SG_ 1508 OBC_SWVersion_Supplier "OBC软件供应商代码（有电咖定义，如A/B/C分别代表A点/B点/C点供应商）";
CM_ SG_ 1508 OBC_SWVersion_Main "OBC软件版本-大版本";
CM_ SG_ 1508 OBC_SWVersion_Sub1 "OBC软件版本-小版本第一位";
CM_ SG_ 1508 OBC_SWVersion_Sub2 "OBC软件版本-小版本第二位";
CM_ SG_ 1508 OBC_HWVersion_Supplier "OBC硬件供应商代码（有电咖定义，如A/B/C分别代表A点/B点/C点供应商）";
CM_ SG_ 1508 OBC_HWVersion_Main "OBC硬件版本-大版本";
CM_ SG_ 1508 OBC_HWVersion_Sub1 "OBC硬件版本-小版本第一位";
CM_ SG_ 1508 OBC_HWVersion_Sub2 "OBC硬件版本-小版本第二位";
CM_ SG_ 1508 OBC_HWVersion_Sub3 "OBC硬件版本-小版本第三位";
CM_ SG_ 1508 OBC_SWVersion_Sub3 "OBC软件版本-小版本第三位";
CM_ SG_ 1510 ACU_SWVersion_Supplier "ACU软件供应商代码（有电咖定义，如A/B/C分别代表A点/B点/C点供应商，定义参考诊断规范版本号定义）";
CM_ SG_ 1510 ACU_SWVersion_Main "ACU软件版本-大版本";
CM_ SG_ 1510 ACU_SWVersion_Sub1 "ACU软件版本-小版本第一位";
CM_ SG_ 1510 ACU_SWVersion_Sub2 "ACU软件版本-小版本第二位";
CM_ SG_ 1510 ACU_HWVersion_Supplier "ACU硬件件供应商代码";
CM_ SG_ 1510 ACU_HWVersion_Main "ACU硬件版本-大版本";
CM_ SG_ 1510 ACU_HWVersion_Sub1 "ACU硬件版本-小版本第一位";
CM_ SG_ 1510 ACU_HWVersion_Sub2 "ACU硬件版本-小版本第二位";
CM_ SG_ 1511 WPTC_SWVersion_Supplier "WPTC软件供应商代码（有电咖定义，如A/B/C分别代表A点/B点/C点供应商，定义参考诊断规范版本号定义）";
CM_ SG_ 1511 WPTC_SWVersion_Main "WPTC软件版本-大版本";
CM_ SG_ 1511 WPTC_SWVersion_Sub1 "WPTC软件版本-小版本第一位";
CM_ SG_ 1511 WPTC_SWVersion_Sub2 "WPTC软件版本-小版本第二位";
CM_ SG_ 1511 WPTC_HWVersion_Supplier "WPTC硬件件供应商代码";
CM_ SG_ 1511 WPTC_HWVersion_Main "WPTC硬件版本-大版本";
CM_ SG_ 1511 WPTC_HWVersion_Sub1 "WPTC硬件版本-小版本第一位";
CM_ SG_ 1511 WPTC_HWVersion_Sub2 "WPTC硬件版本-小版本第二位";
CM_ SG_ 804 MCU_FailCode1 "故障码1";
CM_ SG_ 804 MCU_FailCode2 "故障码2";
CM_ SG_ 804 MCU_FailCode3 "故障码3";
CM_ SG_ 804 MCU_FailCode4 "故障码4";
CM_ SG_ 835 PLG_Trunk_Sts "后背门状态";
CM_ SG_ 835 PLG_Shutface_SW "后背门内侧关门开关状态";
CM_ SG_ 835 PLG_Latc_PawlSW "后背门锁（一级锁位）开关状态，后背门开关状态";
CM_ SG_ 835 PLG_Latch_SecondarySW "后背门锁（二级锁位）开关状态";
CM_ SG_ 835 PLG_Latch_0PositionSW "后背门自吸锁复位开关状态";
CM_ SG_ 835 PLG_LearnedSts "PLG学习状态";
CM_ SG_ 835 PLG_KickActiveReq "脚踢信号有效请求";
CM_ SG_ 835 PLG_HallSensor "霍尔传感器状态";
CM_ SG_ 835 PLG_OpenAng "尾门开度";
CM_ SG_ 835 PLG_OpenAngValid "尾门开度有效性";
CM_ SG_ 835 PLG_GaragePosition "Reset Garage Position车库高度";
CM_ SG_ 835 PLG_LatchMorSts "LatchMor，锁电机状态";
CM_ SG_ 835 PLG_GearMor1Sts "GearMor1，撑杆电机1状态";
CM_ SG_ 835 PLG_GearMor2Sts "GearMor2，撑杆电机2状态";
CM_ SG_ 835 PLG_mode "PLG工作模式";
CM_ SG_ 835 PLG_TBOXUnlockEnableSts "TBOX发解锁命令后，PLG反馈的解锁使能状态";
CM_ SG_ 835 PLG_Fault "PLG故障信号";
CM_ SG_ 835 PLG_FaultSts "PLG故障状态";
CM_ SG_ 774 BMS_RemainChargingTime "剩余充电时间";
CM_ SG_ 774 BMS_Charing_Time "本次充电时长";
CM_ SG_ 774 BMS_Charging_Ah "本次充入容量";
CM_ SG_ 774 BMS_TotalCharging_Ah "累计充电容量";
CM_ SG_ 774 BMS_Charging_Energy "本次充入能量";
CM_ SG_ 528 Checksum_0x210 "Checksum: IDMSB XOR IDLSB XOR Byte1 XOR Byte2 XOR Byte3 XOR Byte4 XOR Byte5 XOR Byte6XOR Byte7";
CM_ SG_ 528 ACU_CrashStatus "ACU output crash status
";
CM_ SG_ 528 ACU_AirBagFailSts "Airbag fail Warning Lamp status
安全气囊故障报警灯";
CM_ SG_ 528 ACU_SBR_Driver "Drive Buckle stauts/ SBR status 
主驾安全带未系提醒";
CM_ SG_ 528 ACU_SBR_Passenger "Passenger Buckle stauts/ SBR status 
前排副驾驶安全带未系提醒";
CM_ SG_ 528 ACU_SBR_RLPassenger "RL Passenger Buckle stauts/ SBR status 
后排左侧安全带未系提醒";
CM_ SG_ 528 ACU_SBR_MidPassenger "Mid Passenger Buckle stauts/ SBR status  
后排中间安全带未系提醒";
CM_ SG_ 528 ACU_SBR_RRPassenger "RR Passenger Buckle stauts/ SBR status 
后排右侧安全带未系提醒";
CM_ SG_ 528 ACU_DrvSeatBeltSWSts "Driver Buckle Switch status 
主驾安全带未开关状态";
CM_ SG_ 528 ACU_PsSeatBeltSWSts "Passenger Buckle Switch status
前排副驾驶安全带开关状态";
CM_ SG_ 528 ACU_RLPsSeatBeltSWSts "RL Passenger Buckle Switch status 
后排左侧安全带开关状态";
CM_ SG_ 528 ACU_MidPsSeatBeltSWSts "Mid Passenger  Buckle Switch status 
后排中间安全带开关状态";
CM_ SG_ 528 ACU_RRPsSeatBeltSWSts "RR Passenger Buckle Switch status
后排右侧安全带开关状态";
CM_ SG_ 528 RollingCounter_0x210 "从0到15循环计数，如果通信中断，则重新从0开始计数。";
CM_ SG_ 596 AC_SystemSts "空调开关状态";
CM_ SG_ 596 AC_CycleSts "空调内外循环";
CM_ SG_ 596 AC_EACSts "压缩机开关状态";
CM_ SG_ 596 AC_AutoModeSts "空调Auto模式";
CM_ SG_ 596 AC_APTC_StartStop "APTC的启停控制命令";
CM_ SG_ 596 AC_StartStopEAC "Start or stop the Compressor 
电动压缩机起停控制命令";
CM_ SG_ 596 AC_EAC_AimSpeed "压缩机目标转速";
CM_ SG_ 596 AC_WindModeSts "当前吹风模式";
CM_ SG_ 596 AC_BlowingRateSts "当前风量状态";
CM_ SG_ 596 AC_APTCSWsts "APTC开关状态";
CM_ SG_ 596 AC_SysFaultsts "AC系统故障状态";
CM_ SG_ 596 AC_InTemperature "车内温度";
CM_ SG_ 596 AC_OutTemperature "车外温度";
CM_ SG_ 596 AC_PM25Value "PM2.5值";
CM_ SG_ 596 AC_BatCoolingValve "chiller电磁热力膨胀阀状态";
CM_ SG_ 596 AC_ComftCoolingValve "乘员舱电磁热力膨胀阀状态";
CM_ SG_ 596 AC_FdefrostSts "最大前除霜除雾状态";
CM_ SG_ 1009 DVR_Sdcard_Sts "SD卡状态";
CM_ SG_ 1009 DVR_DrivingRecord "行车记录";
CM_ SG_ 1009 DVR_VideoResolution "录像分辨率执行";
CM_ SG_ 1009 DVR_VideoTimeSts "录像时长设置状态";
CM_ SG_ 1009 DVR_ShutdownDelay "延时关机";
CM_ SG_ 1009 DVR_VideoCoverageSW "事件录像覆盖开关";
CM_ SG_ 1009 DVR_GSensorSensy "G-Sensor灵敏度";
CM_ SG_ 1009 DVR_ParkMonitor "停车监控";
CM_ SG_ 1009 DVR_TapeSwitch "录音开关";
CM_ SG_ 1009 DVR_HDRSwitch "宽动态开关";
CM_ SG_ 1009 DVR_DriveInfoOverlay "行驶信息叠加";
CM_ SG_ 1009 DVR_SdcardFormateSts "格式化SD卡状态";
CM_ SG_ 1009 DVR_FactoryDefaultSts "恢复出厂设置状态";
CM_ SG_ 1009 DVR_SystemSts "DVR系统状态";
CM_ SG_ 1009 DVR_ControlResult "DVR远程抓图控制命令返回状态";
CM_ SG_ 1009 DVR_GsensorCrashStatus "DVR检测到Gsensor的状态";
CM_ SG_ 1009 DVR_requestWiFiopen "DVR请求WiFi开启";
CM_ SG_ 1009 DVR_Network_Set "DVR主动请求HU打开和关闭网络信号";
CM_ SG_ 1009 DVR_LocalPhotographResult "本地车外拍照返回结果";
CM_ SG_ 1009 DVR_LocalRecordResult "本地手动录像返回结果";
CM_ SG_ 1009 DVR_Frameinterval "缩时录像抽帧间隔，1-255(s),录像时长=抽帧间隔*视频帧数";
CM_ SG_ 1009 DVR_FrameCount "缩时录像视频帧数,总抽帧数，取值范围:60-1800帧";
CM_ SG_ 1009 DVR_PlayRate "缩时录像播放帧率,每秒播放帧数，取值范围：1-30帧";
CM_ SG_ 1009 DVR_LocalTimelapseRecordResult "本地手动缩时录像返回结果";
CM_ SG_ 676 DSM_EasyEntrySWSts "座椅迎宾功能设置反馈";
CM_ SG_ 676 DSM_DSMHeatSWsts "主驾加热功能开关反馈";
CM_ SG_ 676 DSM_MemoryAlarm "记忆是否成功状态";
CM_ SG_ 676 DSM_DeleteMemoryRsp "座椅记忆删除状态";
CM_ SG_ 676 DSM_GetMemoryRsp "座椅记忆调用调节完成状态";
CM_ SG_ 676 DSM_DseatMemoryPosition "主驾当前记忆位置状态";
CM_ SG_ 676 DSM_SLV_DirectionSts "主驾座椅前后调节电机（SLV）运动方向";
CM_ SG_ 676 DSM_SHV_DirectionSts "主驾座椅后部高度调节电机（SHV）运动方向";
CM_ SG_ 676 DSM_LNV_DirectionSts "支架靠背电机（LNV）运动方向";
CM_ SG_ 676 DSM_SLV_CalibrationSts "座椅前后调节电机（SLV）标定状态";
CM_ SG_ 676 DSM_SHV_CalibrationSts "座椅高度调节电机（SHV）标定状态";
CM_ SG_ 676 DSM_LNV_CalibrationSts "主驾靠背电机（LNV）标定状态";
CM_ SG_ 676 DSM_DSLV_MotorfaultSts "主驾座椅前后调节电机（SLV）故障状态";
CM_ SG_ 676 DSM_SLV_Position "主驾座椅前后调节电机（SLV）位置";
CM_ SG_ 676 DSM_DSHV_MotorfaultSts "主驾座椅高度调节电机（SHV）故障状态";
CM_ SG_ 676 DSM_SHV_Position "主驾座椅高度调节电机（SHV）位置";
CM_ SG_ 676 DSM_DSNV_MotorfaultSts "主驾靠背电机（LNV）故障状态";
CM_ SG_ 676 DSM_LNV_Position "主驾靠背电机（LNV）位置";
CM_ SG_ 676 DSM_PSMHeatfault "副驾加热功能故障";
CM_ SG_ 676 DSM_PSMHeatSWsts "副驾加热功能开关反馈";
CM_ SG_ 676 DSM_PSMheattemp "副驾驶侧座椅实际温度";
CM_ SG_ 676 DSM_DSMHeatfault "主驾加热功能故障";
CM_ SG_ 676 DSM_DSMheattemp "驾驶侧座椅实际温度";
CM_ SG_ 24 BCM_AuthReq_TBOX_NSM_Code "BCM 一级防盗Challenge Frame";
CM_ SG_ 25 TBOX_AuthResp_BCM_Code "TBOX一级防盗Response Frame";
CM_ SG_ 256 BMS_PackU "电池电压";
CM_ SG_ 256 BMS_WaringLevel "电池报警等级";
CM_ SG_ 256 BMS_PackI "电池电流";
CM_ SG_ 256 BMS_RelayChrPos "快充正接触器状态";
CM_ SG_ 256 BMS_RelayNeg "总负接触器状态";
CM_ SG_ 256 BMS_RelayPre "预充电接触器状态";
CM_ SG_ 256 BMS_RelayPos "总正接触器状态";
CM_ SG_ 256 BMS_RelayChrNeg "快充负接触器状态";
CM_ SG_ 256 BMS_State "BMS工作状态";
CM_ SG_ 256 BMS_ChrFastState "直流充电状态";
CM_ SG_ 256 BMS_SPreCharging "预充电状态";
CM_ SG_ 256 BMS_ChrSlowState "交流充电状态";
CM_ SG_ 256 BMS_0x100_RollingCounter "从0到15循环计数，如果通信中断，则重新从0开始计数。";
CM_ SG_ 258 BMS_RealSOC "电池实际SOC
允许跳变";
CM_ SG_ 258 BMS_PackDispSoc "仪表显示SOC";
CM_ SG_ 258 BMS_PackSOE "电池剩余能量";
CM_ SG_ 258 BMS_WakeUpSignal "BMS唤醒信号KL15状态";
CM_ SG_ 258 BMS_Insulation_R "绝缘电阻值
最大值1000KΩ";
CM_ SG_ 258 BMS_LinkU "电池预充电电压";
CM_ SG_ 258 BMS_BalanceSts "电池均衡状态";
CM_ SG_ 258 BMS_HVIL1_State "HVIL1状态";
CM_ SG_ 258 BMS_HVIL2_State "HVIL2状态";
CM_ SG_ 258 BMS_0x102_RollingCounter "从0到15循环计数，如果通信中断，则重新从0开始计数。";
CM_ SG_ 274 BMS_MaxCellNo "电池最高单体电压编号";
CM_ SG_ 274 BMS_MaxCellU "电池最高单体电压";
CM_ SG_ 274 BMS_MinCellNo "电池最低单体电压编号";
CM_ SG_ 274 BMS_MinCellU "电池最低单体电压";
CM_ SG_ 274 BMS_CellVolDev "电池单体压差";
CM_ SG_ 274 BMS_0x112_RollingCounter "从0到15循环计数，如果通信中断，则重新从0开始计数。";
CM_ SG_ 278 BMS_CellOverVolWaring "单体过压
GBT 32960.3 T18-5";
CM_ SG_ 278 BMS_CellUnderVolWaring "单体欠压
GBT 32960.3 T18-6";
CM_ SG_ 278 BMS_TempOverWaring "温度过高
GBT 32960.3 T18-1";
CM_ SG_ 278 BMS_TempUnderWaring "温度过低";
CM_ SG_ 278 BMS_CellVolDevWaring "压差过大
GBT 32960.3 T18-10";
CM_ SG_ 278 BMS_TempDveWaring "温差过大
GBT 32960.3 T18-0";
CM_ SG_ 278 BMS_BattOverVolWaring "电池包过压
GBT 32960.3 T18-2";
CM_ SG_ 278 BMS_BattUnderVolWaring "电池包欠压
GBT 32960.3 T18-3";
CM_ SG_ 278 BMS_DCChargePlugTempOverHigh "快充枪过温故障";
CM_ SG_ 278 BMS_DisCharOverCurr "放电过流";
CM_ SG_ 278 BMS_RegenOverCurr "充电过流";
CM_ SG_ 278 BMS_InnerCANTimeout "BMS内网通讯超时";
CM_ SG_ 278 BMS_ISOWaring "绝缘报警";
CM_ SG_ 278 BMS_BCUHWFault "采集板硬件故障
具体故障信息由UDS事件帧报出";
CM_ SG_ 278 BMS_NegRelayFault "负极继电器故障";
CM_ SG_ 278 BMS_PosRelayFault "正极继电器故障";
CM_ SG_ 278 BMS_PreRelayFault "预充电继电器故障";
CM_ SG_ 278 BMS_LowVoltageMSD "低压MSD状态";
CM_ SG_ 278 BMS_CharPosRelayFault "快充正极继电器故障";
CM_ SG_ 278 BMS_CharNegRelayFault "快充负继电器故障";
CM_ SG_ 278 BMS_BMUFault "主控板故障
主板硬件故障
具体故障信息由UDS事件帧报出";
CM_ SG_ 278 BMS_VcuCANTimeout "整车通信超时";
CM_ SG_ 278 BMS_BattHVDisaccord "高压异常
电池采样与累加值不一致";
CM_ SG_ 278 BMS_PressureSensorFault "压力传感器故障";
CM_ SG_ 278 BMS_SOClow "SOC低报警
GBT 32960.3 T18-4";
CM_ SG_ 278 BMS_Mismatch "动力蓄电池包不匹配报警
GBT 32960.3 T18-9";
CM_ SG_ 278 BMS_SOCOverHigh "SOC过高
GBT 32960.3 T18-7";
CM_ SG_ 278 BMS_BattOverCharge "电池过充
GBT 32960.3 T18-17";
CM_ SG_ 278 BMS_SOCSkip "SOC跳变
GBT 32960.3 T18-8";
CM_ SG_ 278 BMS_FCGOverCurr "快充充电过流故障";
CM_ SG_ 278 BMS_SCGOverCurr "慢充充电过流故障";
CM_ SG_ 278 BMS_LiquidLeak "电池漏液故障";
CM_ SG_ 278 BMS_CrashFault "电池碰撞故障";
CM_ SG_ 278 BMS_ThermRunAway "电池热失控故障";
CM_ SG_ 278 BMS_Maintenance "电池保养灯";
CM_ SG_ 278 BMS_BusbarTempOverWaring "汇流排过温";
CM_ SG_ 278 BMS_FuseFault "电池熔断器故障";
CM_ SG_ 278 BMS_CurrSensorFault "电流传感器故障
具体故障信息由UDS事件帧报出";
CM_ SG_ 278 BMS_0x116_RollingCounter "从0到15循环计数，如果通信中断，则重新从0开始计数。";
CM_ SG_ 288 Checksum_0x120 "Checksum: IDMSB XOR IDLSB XOR Byte1 XOR Byte2 XOR Byte3 XOR Byte4 XOR Byte5 XOR Byte6 XOR Byte7";
CM_ SG_ 288 MCU_MotorActualTorque "电机实时输出扭矩";
CM_ SG_ 288 MCU_MotorSpeed "电机实时输出转速";
CM_ SG_ 288 MCU_AuthSts "MCU动力防盗认证结果";
CM_ SG_ 288 MCU_OverSpdWarning "电机超速报警";
CM_ SG_ 288 MCU_InverterTempWarning "电机控制器过温报警";
CM_ SG_ 288 MCU_MotorTempWarning "电机过温报警";
CM_ SG_ 288 MCU_OverTemp "MCU请求点亮电机过热灯";
CM_ SG_ 288 MCU_WorkSts "MCU实时工作状态";
CM_ SG_ 288 MCU_FaultLevel "故障等级";
CM_ SG_ 288 MCU_FaultLampOn "MCU请求点亮电机故障灯";
CM_ SG_ 288 MCU_HVLock "MCU高压互锁信号(后驱预留）";
CM_ SG_ 288 Rollingcounter_0x120 "从0到15循环计数，如果通信中断，则重新从0开始计数。";
CM_ SG_ 290 Checksum_0x122 "Checksum: IDMSB XOR IDLSB XOR Byte1 XOR Byte2 XOR Byte3 XOR Byte4 XOR Byte5 XOR Byte6 XOR Byte7";
CM_ SG_ 290 MCU_MaxAvailableTorque "电机可输出最大电动扭矩";
CM_ SG_ 290 MCU_MinAvailableTorque "电机可输出最大发电扭矩";
CM_ SG_ 290 MCU_DeratingTempCoolant "冷却水过温降功率";
CM_ SG_ 290 MCU_damping_En "扭矩补偿标志位";
CM_ SG_ 290 MCU_DeratingTrqMin "发电超限降功率";
CM_ SG_ 290 MCU_DeratingTrqMax "电动超限降功率";
CM_ SG_ 290 MCU_DeratingOvrUdc "过压降功率";
CM_ SG_ 290 MCU_DeratingUndrUdc "欠压降功率";
CM_ SG_ 290 MCU_DeratingOvrIdc "过流降功率";
CM_ SG_ 290 MCU_DeratingUndrIdc "欠流降功率";
CM_ SG_ 290 MCU_DeratingTempEm "电机过温降功率";
CM_ SG_ 290 MCU_DeratingTempInv "控制器过温降功率";
CM_ SG_ 290 Rollingcounter_0x122 "从0到15循环计数，如果通信中断，则重新从0开始计数。";
CM_ SG_ 290 MCU_MotorTorqueDeratingFlg "电机扭矩derating标志位";
CM_ SG_ 290 MCU_HVReady "高压端预充完成";
CM_ SG_ 290 MCU_DeratingOverSpd "电机超速降功率";
CM_ SG_ 289 Checksum_0x121 "Checksum: IDMSB XOR IDLSB XOR Byte1 XOR Byte2 XOR Byte3 XOR Byte4 XOR Byte5 XOR Byte6 XOR Byte7";
CM_ SG_ 289 ESP_VehicleSpeed "Current Vehicle Speed
当前实际车速";
CM_ SG_ 289 ESP_VehicleSpeed_Valid "Vehicle speed value valid
车速有效";
CM_ SG_ 289 ESP_OFF "ESP is diabled by pata（ESP off）";
CM_ SG_ 289 ESP_ABS_Error "ABS_Fault: ESP system has detected a failure which does not allow a reliable ABS regulation and is therefore switched off";
CM_ SG_ 289 ESP_ABS_Intervention "ABS control active - Indication that ESP system (especially ABS module) currently performs a brake intervention";
CM_ SG_ 289 ESP_VDC_TCS_Error "ESP_Fault: VDC/TCS is switched off due to detected failure";
CM_ SG_ 289 ESP_EBD_Error "EBD_Fault: ESP system has detected a heavy fault, which does not even allow a reliable electronic brake distribution and is therefore completely shut down";
CM_ SG_ 289 ESP_VDC_Intervention "VDC controller active: Oversteering brake intervention or Understeering brake intervention";
CM_ SG_ 289 ESP_TCS_Intervention "TCS controller active: Brake intervention or Engine torque reduction intervention";
CM_ SG_ 289 ESP_EBD_Intervention "EBD control active - Indication that ESP system (especially EBD module) currently performs a brake intervention";
CM_ SG_ 289 ESP_HDC_Status "Indicating the status of HDC.";
CM_ SG_ 289 ESP_HDC_Available "HMI Responsible,CAN get degrateHDC statement from DSW and send out";
CM_ SG_ 289 ESP_EPBMainteDiagmodeActive "EPB Maintenance diagnosis mode status";
CM_ SG_ 289 ESP_EPBFailstatus "EPB failure status";
CM_ SG_ 289 ESP_EPBStatus "Indicating the status of EPB";
CM_ SG_ 289 ESP_VehicleStop "Indicates if vehicle is in standstill (if more or equal to two wheels are standstill).
Set to a desired state when standstill is surely reached.
";
CM_ SG_ 289 ESP_VehicleStop_Valid "Check the validity of the signal of VehicleStop.";
CM_ SG_ 289 ESP_MasterCyPressureCmp "Master cylinder pressure
Offset included";
CM_ SG_ 289 ESP_MasterCyPressure_Valid "Indicating MasterCyPressure valid or not";
CM_ SG_ 289 ESP_WheelCyBrakeForce_Exist "No brake pressure applied; Generally it indicates wheel cylinder presure.";
CM_ SG_ 289 ESP_ESPLamp "ESP或者TCS触发点亮仪表信号灯";
CM_ SG_ 289 ESP_AVHstandbyStatus "Indicates AVH in standby mode or not";
CM_ SG_ 289 ESP_AVHActive "Indicates AVH in active or not ";
CM_ SG_ 289 ESP_AVH_availalbe "HMI Responsible,CAN get degrateAVH statement from DSW and send out";
CM_ SG_ 289 ESP_HHC_Available "HHC  is available or not";
CM_ SG_ 289 ESP_HHCActive "Indicates HHCH in active or not ";
CM_ SG_ 289 ESP_HubDiagmodeActive "Indicates Hub diagnosis mode in active or not 
ESC转毂&诊断模式,点亮ABS和ESC黄灯 ";
CM_ SG_ 289 ESP_HAZ_Active "Emergency brake light on, 当减速度过大时，警告灯开启，提醒用户减速度过大 ";
CM_ SG_ 289 ESP_MILLampRequest "ESP Request EMS MIL lamp on
仅适用燃油车";
CM_ SG_ 289 RollingCounter_0x121 "RollingCounter: used 4bit length signal and the arithmetic is increased from 0 to 15 by every message.";
CM_ SG_ 291 MCU_IsCurrent "实际定子电流有效值";
CM_ SG_ 291 MCU_DC_linkVoltage "直流母线电压";
CM_ SG_ 291 MCU_DC_linkCurrent "直流母线电流";
CM_ SG_ 291 MCU_InverterTemp "电机控制器温度";
CM_ SG_ 291 MCU_MotorTemp "电机定子温度";
CM_ SG_ 291 MCU_WaterTemp "控制器冷却水温度";
CM_ SG_ 291 MCU_MotorCount "电机个数";
CM_ SG_ 291 MCU_MotorSeqNum "电机顺序号";
CM_ SG_ 292 MCU_DBCTempU "U相DBC温度";
CM_ SG_ 292 MCU_DBCTempV "V相DBC温度";
CM_ SG_ 292 MCU_DBCTempW "W相DBC温度";
CM_ SG_ 292 MCU_RotorTemp "电机转子温度";
CM_ SG_ 292 MCU_MotoroffsetSts "电机转子偏移角度状态";
CM_ SG_ 292 MCU_stGateDrv "逆变器状态";
CM_ SG_ 292 MCU_Motoroffset "电机转子偏移角度";
CM_ SG_ 545 TBOX_BT_Key_valid "TBOX蓝牙钥匙信息";
CM_ SG_ 545 TBOX_WorkModeCMD "TBOX控制状态";
CM_ SG_ 545 TBOX_Locate_F "TBOX定位异常故障";
CM_ SG_ 545 TBOX_Networking_F "TBOX联网异常故障";
CM_ SG_ 545 TBOX_Memory_F "TBOX存储故障";
CM_ SG_ 545 TBOX_WelcomefuncReq "迎宾功能请求（Tbox检测到蓝牙钥匙从未连接上到连接上并且有效时刻发三帧0x1后回到0x0,发送此信号时，TBOX的NM报文不能请求休眠）";
CM_ SG_ 545 TBOX_Timer_out "TBOX定时器";
CM_ SG_ 545 TBOX_FOTA_mode_ALL "TBOX  FOTA模式";
CM_ SG_ 545 TBOX_RemoteCharge_EndHour "TBOX 发送的预约充电结束时间----时";
CM_ SG_ 545 TBOX_RemotCh_Full_SetSts "TBOX 反馈给 HU 及 APP 的是否充满设置状 态";
CM_ SG_ 545 TBOX_RemoteCharge_Endmin "TBOX 发送的预约充电结束时间----分钟";
CM_ SG_ 599 AC_RemoteAC "空调远程控制请求";
CM_ SG_ 599 AC_RemoteACFeedback "远程空调反馈";
CM_ SG_ 599 AC_SolarIntensity "光照强度";
CM_ SG_ 599 AC_Temp_setvalue "温度调节设置值";
CM_ SG_ 599 AC_inout_MixwindSts "内外混风状态";
CM_ SG_ 599 AC_OutPM25Value "室外PM2.5值";
CM_ SG_ 849 TBOX_BCM_DoorLock_Control_4G "远程APP四门解闭锁信号
(无控制请求时，发送0x0。当激活控制命令时，发送0x1/0x2。连续发送3次，之后将控制信号重新置0x0)";
CM_ SG_ 849 TBOX_BCM_CarLocating "双闪或者鸣笛开启
(无控制请求时，发送0x0。当激活控制命令时，发送0x1/0x2/0x3/0x4。连续发送3次，之后将控制信号重新置0x0)";
CM_ SG_ 849 TBOX_PLG_TrunkunLock "后备箱解闭锁信号,
(无控制请求时，发送0x0。当激活控制命令时，发送0x1。连续发送3次，之后将控制信号重新置0x0，高配PLG执行，低配BCM执行)";
CM_ SG_ 849 TBOX_DSM_heatSwitch "驾驶侧座椅远程加热开关
(无控制请求时，发送0x0。当激活控制命令时，发送0x1/0x2。连续发送3次，之后将控制信号重新置0x0)";
CM_ SG_ 849 TBOX_PSM_heatSwitch "副驾驶侧座椅远程加热开关
(无控制请求时，发送0x0。当激活控制命令时，发送0x1/0x2。连续发送3次，之后将控制信号重新置0x0)";
CM_ SG_ 849 TBOX_DSM_GetMemoryReq "记忆调用请求(关联ID)
(无控制请求时，发送0x0。当激活控制命令时，发送0x1-0xC。连续发送3次，之后将控制信号重新置0x0)";
CM_ SG_ 849 TBOX_BCM_DoorLock_Control_BT "本地蓝牙钥匙四门解闭锁信号
(无控制请求时，发送0x0。当激活控制命令时，发送0x1/0x2。连续发送3次，之后将控制信号重新置0x0)";
CM_ SG_ 849 TBOX_DSM_Targtemp "驾驶侧座椅远程加热目标温度,
（开启状态可以选择发送目标温度）";
CM_ SG_ 849 TBOX_welcomefuncReqsts "迎宾功能使能状态";
CM_ SG_ 849 TBOX_Publish_Wakeup "TBOX推动消息唤醒HU";
CM_ SG_ 849 TBOX_PSM_Targtemp "副驾驶侧座椅远程加热目标温度
（开启状态可以选择发送目标温度）";
CM_ SG_ 849 TBOX_BCM_selflearn_MD1 "天窗玻璃板初始化";
CM_ SG_ 849 TBOX_BCM_selflearn_Mrollo "天窗遮阳帘初始化";
CM_ SG_ 849 TBOX_BCM_forceclose_MD1 "强制关闭玻璃板信号";
CM_ SG_ 849 TBOX_BCM_forceclose_Mrollo "强制关闭遮阳板信号";
CM_ SG_ 849 TBOX_BCM_stopsunroof "停止天窗运动命令";
CM_ SG_ 849 TBOX_BCM_PowerON_Request "上电请求发给BCM
(无控制请求时，发送0x0。当激活控制命令时，发送0x1/0x2/0x3。连续发送5次，之后将控制信号重新置0x0)";
CM_ SG_ 849 TBOX_BCM_PowerON_limit "禁止上电请求
";
CM_ SG_ 849 TBOX_BCM_SrfSlidePosReq "玻璃板滑动打开/关闭信号，大屏或者手机APP触发";
CM_ SG_ 849 TBOX_BCM_ShadeSlidePosReq "遮阳帘位置控制信号";
CM_ SG_ 849 TBOX_BCM_FLWindowsControl "左前车窗远程控制信号
(无控制请求时，发送0x0。当激活控制命令时，发送0x1/0x2/0x3。连续发送3次，之后将控制信号重新置0x0)";
CM_ SG_ 849 TBOX_BCM_FRWindowsControl "右前车窗远程控制信号(无控制请求时，发送0x0。当激活控制命令时，发送0x1/0x2/0x3。连续发送3次，之后将控制信号重新置0x0)";
CM_ SG_ 849 TBOX_BCM_RLWindowsControl "左后车窗远程控制信号(无控制请求时，发送0x0。当激活控制命令时，发送0x1/0x2/0x3。连续发送3次，之后将控制信号重新置0x0)";
CM_ SG_ 849 TBOX_BCM_RRWindowsControl "右后车窗远程控制信号(无控制请求时，发送0x0。当激活控制命令时，发送0x1/0x2/0x3。连续发送3次，之后将控制信号重新置0x0)";
CM_ SG_ 850 TBOX_AC_SystemSet "空调开关";
CM_ SG_ 850 TBOX_AC_Cycle "空调内外循环";
CM_ SG_ 850 TBOX_AC_EAC_Control "压缩机开关";
CM_ SG_ 850 TBOX_AC_AutoMode_Set "Auto模式";
CM_ SG_ 850 TBOX_AC_WindMode_Set "吹风模式";
CM_ SG_ 850 TBOX_AC_BlowingRate_Set "风量调节";
CM_ SG_ 850 TBOX_AC_APTCSW_Set "APTC开关";
CM_ SG_ 850 TBOX_AC_Temp_set "温度调节";
CM_ SG_ 850 TBOX_HU_rebootACK "tbox reboot 应答";
CM_ SG_ 850 TBOX_RemotePhotograph "APP远程开启远程拍照
(无控制请求时，发送0x0。当激活控制命令时，发送0x1/0x2/0x3。连续发送3次，之后将控制信号重新置0x0)";
CM_ SG_ 850 TBOX_PLG_OpenControl "APP控制PLG打开关闭信号";
CM_ SG_ 850 TBOX_RemoteCharge_StartHour "APP发送的预约充电开启时间----时
0x0-0x17: Hour
0x18-0x1F: Invalid";
CM_ SG_ 850 TBOX_RemoteCharge_Setsts "定时充电开启设置状态";
CM_ SG_ 850 TBOX_ChargeCtrl_Setsts "TBOX响应的立即或定时充电选择状态";
CM_ SG_ 850 TBOX_RemoteCharge_Startmin "APP发送的预约充电开启时间----分
0x0-0x3B: Minute
0x3C-0x3F: Invalid
";
CM_ SG_ 850 TBOX_BCM_FLWindowsVoiControl "左前车窗控制信号";
CM_ SG_ 850 TBOX_BCM_FRWindowsVoiControl "右前车窗控制信号";
CM_ SG_ 850 TBOX_BCM_RLWindowsVoiControl "左后车窗控制信号";
CM_ SG_ 850 TBOX_BCM_RRWindowsVoiControl "右后车窗控制信号";
CM_ SG_ 851 Checksum_0x353 "Checksum: IDMSB XOR IDLSB XOR Byte1 XOR Byte2 XOR Byte3 XOR Byte4 XOR Byte5 XOR Byte6 XOR Byte7";
CM_ SG_ 851 TBOX_RemoteChargetime "远程充电时间设置
(无控制请求时，发送0x0。当激活控制命令时，发送0x1-0x3ff。连续发送3次，之后将控制信号重新置0x0)";
CM_ SG_ 851 TBOX_VCU_12vChargeReq "小电瓶充电请求
(无控制请求时，发送0x0。当激活控制命令时，发送0x1。连续发送5次，之后将控制信号重新置0x0)";
CM_ SG_ 851 TBOX_VCU_TimeCharge "定时充电请求信号";
CM_ SG_ 851 TBOX_BTKey_valid "TBOX蓝牙钥匙连接状态";
CM_ SG_ 851 TBOX_ChargeDepthSet "充电深度设置";
CM_ SG_ 851 TBOX_RemoteChargeper "远程充电百分比设置
(无控制请求时，发送0x0。当激活控制命令时，发送0x1-0x64。连续发送3次，之后将控制信号重新置0x0)";
CM_ SG_ 851 TBOX_APS_EPSStrgWhlAngZero "一键回正方向盘信号";
CM_ SG_ 851 TBOX_APS_RequstRemoteParkOut "TBOX允许遥控泊出指令";
CM_ SG_ 851 TBOX_APS_StartRemoteParkOut "按下APP遥控泊出按键状态";
CM_ SG_ 851 TBOX_APS_RequstRemoteParkIn "TBOX允许遥控泊入指令";
CM_ SG_ 851 TBOX_APS_StartRemoteParkIn "按下APP遥控泊入按键状态";
CM_ SG_ 851 TBOX_APS_PoewerOff_Request "TBOX请求APS下电";
CM_ SG_ 851 TBOX_APS_StraightOut_Request1 "TBOX请求APS执行左转、右转";
CM_ SG_ 851 TBOX_APS_StraightOut_Request2 "TBOX请求APS执行前进、后退";
CM_ SG_ 851 TBOX_APS_PowerON_Request "上电请求，发给APA
(无控制请求时，发送0x0。当激活控制命令时，发送0x1/0x2/0x3。连续发送5次，之后将控制信号重新置0x0)";
CM_ SG_ 851 TBOX_VCU_RemoteChrgLock "远程解锁电子锁";
CM_ SG_ 851 TBOX_FOTA_mode "FOTA模式";
CM_ SG_ 851 TBOX_FOTA_wakeup "TBOX唤醒HU/ICM/RSE/DVR启动OTA升级";
CM_ SG_ 851 RollingCounter_0x353 "RollingCounter: used 4bit length signal and the arithmetic is increased from 0 to 15 by every message.";
CM_ SG_ 853 TBOX_TimeSyncSts "TBOX发送的时间同步有效位";
CM_ SG_ 853 TBOX_TimeSyncData_Year "TBOX发送的同步时间数据----年
0x0-0x63: Year
0x64-0x7F: Invalid
";
CM_ SG_ 853 TBOX_TimeSyncData_Month "TBOX发送的同步时间数据----月
0x0: Invalid
0x1-0xC: Month";
CM_ SG_ 853 TBOX_TimeSyncData_Day "TBOX发送的同步时间数据----日
0x0: Invalid
0x01-0x1F: Day";
CM_ SG_ 853 TBOX_TimeSyncData_Hour "ACM发送的同步时间数据----时
0x0-0x17: Hour
0x18-0x1F: Invalid";
CM_ SG_ 853 TBOX_TimeSyncData_Minute "TBOX发送的同步时间数据----分
0x0-0x3B: Minute
0x3C-0x3F: Invalid
";
CM_ SG_ 853 TBOX_TimeSyncData_Second "TBOX发送的同步时间数据----秒
0x00-0x3B: Second
0x3C-0x3F: Invalid
";
CM_ SG_ 1026 TBOX_NM_DA "目标地址";
CM_ SG_ 1026 TBOX_NM_ALIVE "TBOX_NM_ALIVE 0-未激活；1-已激活；";
CM_ SG_ 1026 TBOX_NM_RING "TBOX_NM_RING 0-未激活；1-已激活；";
CM_ SG_ 1026 TBOX_NM_LIMPHOME "TBOX_NM_LIMPHOME 0-未激活；1-已激活；";
CM_ SG_ 1026 TBOX_NM_SLEEP_INDICATION "TBOX_NM_SLEEP_INDICATION 0-未激活；1-已激活；";
CM_ SG_ 1026 TBOX_NM_SLEEP_ACK "TBOX_NM_SLEEP_ACK 0-未激活；1-已激活；";
CM_ SG_ 1028 GW_Tbox_NM_DA "目标地址";
CM_ SG_ 1028 GW_Tbox_NM_ALIVE "Alive报文";
CM_ SG_ 1028 GW_Tbox_NM_RING "Ring报文";
CM_ SG_ 1028 GW_Tbox_NM_LIMPHOME "Limphome报文";
CM_ SG_ 1028 GW_Tbox_NM_SLEEP_Ind "睡眠标志位";
CM_ SG_ 1028 GW_Tbox_NM_SLEEP_ACK "睡眠确认位";
CM_ SG_ 1299 BMS_MaxTempNo "电池最高温度编号";
CM_ SG_ 1299 BMS_MaxTemp "电池最高温度";
CM_ SG_ 1299 BMS_MinTempNo "电池最低温度编号";
CM_ SG_ 1299 BMS_MinTemp "电池最低温度";
CM_ SG_ 1299 BMS_BattTempDev "电池温度差";
CM_ SG_ 1299 BMS_CCTemp1 "快充接口1温度";
CM_ SG_ 1299 BMS_CCTemp2 "快充接口2温度";
CM_ SG_ 1299 BMS_0x513_RollingCounter "从0到15循环计数，如果通信中断，则重新从0开始计数。";
CM_ SG_ 1300 BMS_ModuleBusbarMaxTempNo "模组busbar最高温度编号";
CM_ SG_ 1300 BMS_ModuleBusbarMaxTemp "模组busbar最高温度";
CM_ SG_ 1300 BMS_ModuleBusbarMinTempNo "模组busbar最低温度编号";
CM_ SG_ 1300 BMS_ModuleBusbarMinTemp "模组busbar最低温度";
CM_ SG_ 1300 BMS_0x514_RollingCounter "从0到15循环计数，如果通信中断，则重新从0开始计数。";
CM_ SG_ 1328 BMS_BattCellNum1Vol "1号单体电压值";
CM_ SG_ 1328 BMS_BattCellNum2Vol "2号单体电压值";
CM_ SG_ 1328 BMS_BattCellNum3Vol "3号单体电压值";
CM_ SG_ 1328 BMS_BattCellNum4Vol "4号单体电压值";
CM_ SG_ 1329 BMS_BattCellNum5Vol "5号单体电压值";
CM_ SG_ 1329 BMS_BattCellNum6Vol "6号单体电压值";
CM_ SG_ 1329 BMS_BattCellNum7Vol "7号单体电压值";
CM_ SG_ 1329 BMS_BattCellNum8Vol "8号单体电压值";
CM_ SG_ 1330 BMS_BattCellNum9Vol "9号单体电压值";
CM_ SG_ 1330 BMS_BattCellNum10Vol "10号单体电压值";
CM_ SG_ 1330 BMS_BattCellNum11Vol "11号单体电压值";
CM_ SG_ 1330 BMS_BattCellNum12Vol "12号单体电压值";
CM_ SG_ 1331 BMS_BattCellNum13Vol "13号单体电压值";
CM_ SG_ 1331 BMS_BattCellNum14Vol "14号单体电压值";
CM_ SG_ 1331 BMS_BattCellNum15Vol "15号单体电压值";
CM_ SG_ 1331 BMS_BattCellNum16Vol "16号单体电压值";
CM_ SG_ 1332 BMS_BattCellNum17Vol "17号单体电压值";
CM_ SG_ 1332 BMS_BattCellNum18Vol "18号单体电压值";
CM_ SG_ 1332 BMS_BattCellNum19Vol "19号单体电压值";
CM_ SG_ 1332 BMS_BattCellNum20Vol "20号单体电压值";
CM_ SG_ 1333 BMS_BattCellNum21Vol "21号单体电压值";
CM_ SG_ 1333 BMS_BattCellNum22Vol "22号单体电压值";
CM_ SG_ 1333 BMS_BattCellNum23Vol "23号单体电压值";
CM_ SG_ 1333 BMS_BattCellNum24Vol "24号单体电压值";
CM_ SG_ 1334 BMS_BattCellNum25Vol "25号单体电压值";
CM_ SG_ 1334 BMS_BattCellNum26Vol "26号单体电压值";
CM_ SG_ 1334 BMS_BattCellNum27Vol "27号单体电压值";
CM_ SG_ 1334 BMS_BattCellNum28Vol "28号单体电压值";
CM_ SG_ 1335 BMS_BattCellNum29Vol "29号单体电压值";
CM_ SG_ 1335 BMS_BattCellNum30Vol "30号单体电压值";
CM_ SG_ 1335 BMS_BattCellNum31Vol "31号单体电压值";
CM_ SG_ 1335 BMS_BattCellNum32Vol "32号单体电压值";
CM_ SG_ 1336 BMS_BattCellNum33Vol "33号单体电压值";
CM_ SG_ 1336 BMS_BattCellNum34Vol "34号单体电压值";
CM_ SG_ 1336 BMS_BattCellNum35Vol "35号单体电压值";
CM_ SG_ 1336 BMS_BattCellNum36Vol "36号单体电压值";
CM_ SG_ 1337 BMS_BattCellNum37Vol "37号单体电压值";
CM_ SG_ 1337 BMS_BattCellNum38Vol "38号单体电压值";
CM_ SG_ 1337 BMS_BattCellNum39Vol "39号单体电压值";
CM_ SG_ 1337 BMS_BattCellNum40Vol "40号单体电压值";
CM_ SG_ 1338 BMS_BattCellNum41Vol "41号单体电压值";
CM_ SG_ 1338 BMS_BattCellNum42Vol "42号单体电压值";
CM_ SG_ 1338 BMS_BattCellNum43Vol "43号单体电压值";
CM_ SG_ 1338 BMS_BattCellNum44Vol "44号单体电压值";
CM_ SG_ 1339 BMS_BattCellNum45Vol "45号单体电压值";
CM_ SG_ 1339 BMS_BattCellNum46Vol "46号单体电压值";
CM_ SG_ 1339 BMS_BattCellNum47Vol "47号单体电压值";
CM_ SG_ 1339 BMS_BattCellNum48Vol "48号单体电压值";
CM_ SG_ 1340 BMS_BattCellNum49Vol "49号单体电压值";
CM_ SG_ 1340 BMS_BattCellNum50Vol "50号单体电压值";
CM_ SG_ 1340 BMS_BattCellNum51Vol "51号单体电压值";
CM_ SG_ 1340 BMS_BattCellNum52Vol "52号单体电压值";
CM_ SG_ 1341 BMS_BattCellNum53Vol "53号单体电压值";
CM_ SG_ 1341 BMS_BattCellNum54Vol "54号单体电压值";
CM_ SG_ 1341 BMS_BattCellNum55Vol "55号单体电压值";
CM_ SG_ 1341 BMS_BattCellNum56Vol "56号单体电压值";
CM_ SG_ 1342 BMS_BattCellNum57Vol "57号单体电压值";
CM_ SG_ 1342 BMS_BattCellNum58Vol "58号单体电压值";
CM_ SG_ 1342 BMS_BattCellNum59Vol "59号单体电压值";
CM_ SG_ 1342 BMS_BattCellNum60Vol "60号单体电压值";
CM_ SG_ 1343 BMS_BattCellNum61Vol "61号单体电压值";
CM_ SG_ 1343 BMS_BattCellNum62Vol "62号单体电压值";
CM_ SG_ 1343 BMS_BattCellNum63Vol "63号单体电压值";
CM_ SG_ 1343 BMS_BattCellNum64Vol "64号单体电压值";
CM_ SG_ 1344 BMS_BattCellNum65Vol "65号单体电压值";
CM_ SG_ 1344 BMS_BattCellNum66Vol "66号单体电压值";
CM_ SG_ 1344 BMS_BattCellNum67Vol "67号单体电压值";
CM_ SG_ 1344 BMS_BattCellNum68Vol "68号单体电压值";
CM_ SG_ 1345 BMS_BattCellNum69Vol "69号单体电压值";
CM_ SG_ 1345 BMS_BattCellNum70Vol "70号单体电压值";
CM_ SG_ 1345 BMS_BattCellNum71Vol "71号单体电压值";
CM_ SG_ 1345 BMS_BattCellNum72Vol "72号单体电压值";
CM_ SG_ 1346 BMS_BattCellNum73Vol "73号单体电压值";
CM_ SG_ 1346 BMS_BattCellNum74Vol "74号单体电压值";
CM_ SG_ 1346 BMS_BattCellNum75Vol "75号单体电压值";
CM_ SG_ 1346 BMS_BattCellNum76Vol "76号单体电压值";
CM_ SG_ 1347 BMS_BattCellNum77Vol "77号单体电压值";
CM_ SG_ 1347 BMS_BattCellNum78Vol "78号单体电压值";
CM_ SG_ 1347 BMS_BattCellNum79Vol "79号单体电压值";
CM_ SG_ 1347 BMS_BattCellNum80Vol "80号单体电压值";
CM_ SG_ 1348 BMS_BattCellNum81Vol "81号单体电压值";
CM_ SG_ 1348 BMS_BattCellNum82Vol "82号单体电压值";
CM_ SG_ 1348 BMS_BattCellNum83Vol "83号单体电压值";
CM_ SG_ 1348 BMS_BattCellNum84Vol "84号单体电压值";
CM_ SG_ 1349 BMS_BattCellNum85Vol "85号单体电压值";
CM_ SG_ 1349 BMS_BattCellNum86Vol "86号单体电压值";
CM_ SG_ 1349 BMS_BattCellNum87Vol "87号单体电压值";
CM_ SG_ 1349 BMS_BattCellNum88Vol "88号单体电压值";
CM_ SG_ 1350 BMS_BattCellNum89Vol "89号单体电压值";
CM_ SG_ 1350 BMS_BattCellNum90Vol "90号单体电压值";
CM_ SG_ 1350 BMS_BattCellNum91Vol "91号单体电压值";
CM_ SG_ 1350 BMS_BattCellNum92Vol "92号单体电压值";
CM_ SG_ 1351 BMS_BattCellNum93Vol "93号单体电压值";
CM_ SG_ 1351 BMS_BattCellNum94Vol "94号单体电压值";
CM_ SG_ 1351 BMS_BattCellNum95Vol "95号单体电压值";
CM_ SG_ 1351 BMS_BattCellNum96Vol "96号单体电压值";
CM_ SG_ 1352 BMS_BattCellNum97Vol "97号单体电压值";
CM_ SG_ 1352 BMS_BattCellNum98Vol "98号单体电压值";
CM_ SG_ 1352 BMS_BattCellNum99Vol "99号单体电压值";
CM_ SG_ 1352 BMS_BattCellNum100Vol "100号单体电压值";
CM_ SG_ 1353 BMS_BattCellNum101Vol "101号单体电压值";
CM_ SG_ 1353 BMS_BattCellNum102Vol "102号单体电压值";
CM_ SG_ 1353 BMS_BattCellNum103Vol "103号单体电压值";
CM_ SG_ 1353 BMS_BattCellNum104Vol "104号单体电压值";
CM_ SG_ 1354 BMS_BattCellNum105Vol "105号单体电压值";
CM_ SG_ 1354 BMS_BattCellNum106Vol "106号单体电压值";
CM_ SG_ 1354 BMS_BattCellNum107Vol "107号单体电压值";
CM_ SG_ 1354 BMS_BattCellNum108Vol "108号单体电压值";
CM_ SG_ 1492 TBOX_SWVersion_Supplier "TBOX软件供应商代码（有电咖定义，如A/B/C分别代表A点/B点/C点供应商，定义参考诊断规范版本号定义）";
CM_ SG_ 1492 TBOX_SWVersion_Main "TBOX软件版本-大版本";
CM_ SG_ 1492 TBOX_SWVersion_Sub1 "TBOX软件版本-小版本第一位";
CM_ SG_ 1492 TBOX_SWVersion_Sub2 "TBOX软件版本-小版本第二位";
CM_ SG_ 1492 TBOX_HWVersion_Supplier "TBOX硬件件供应商代码";
CM_ SG_ 1492 TBOX_HWVersion_Main "TBOX硬件版本-大版本";
CM_ SG_ 1492 TBOX_HWVersion_Sub1 "TBOX硬件版本-小版本第一位";
CM_ SG_ 1492 TBOX_HWVersion_Sub2 "TBOX硬件版本-小版本第二位";
CM_ SG_ 1520 BMS_BattTempSensorNum1 "1号温度探针温度值";
CM_ SG_ 1520 BMS_BattTempSensorNum2 "2号温度探针温度值";
CM_ SG_ 1520 BMS_BattTempSensorNum3 "3号温度探针温度值";
CM_ SG_ 1520 BMS_BattTempSensorNum4 "4号温度探针温度值";
CM_ SG_ 1520 BMS_BattTempSensorNum5 "5号温度探针温度值";
CM_ SG_ 1520 BMS_BattTempSensorNum6 "6号温度探针温度值";
CM_ SG_ 1520 BMS_BattTempSensorNum7 "7号温度探针温度值";
CM_ SG_ 1520 BMS_BattTempSensorNum8 "8号温度探针温度值";
CM_ SG_ 1521 BMS_BattTempSensorNum9 "9号温度探针温度值";
CM_ SG_ 1521 BMS_BattTempSensorNum10 "10号温度探针温度值";
CM_ SG_ 1521 BMS_BattTempSensorNum11 "11号温度探针温度值";
CM_ SG_ 1521 BMS_BattTempSensorNum12 "12号温度探针温度值";
CM_ SG_ 1521 BMS_BattTempSensorNum13 "13号温度探针温度值";
CM_ SG_ 1521 BMS_BattTempSensorNum14 "14号温度探针温度值";
CM_ SG_ 1521 BMS_BattTempSensorNum15 "15号温度探针温度值";
CM_ SG_ 1521 BMS_BattTempSensorNum16 "16号温度探针温度值";
CM_ SG_ 1522 BMS_BattTempSensorNum17 "17号温度探针温度值";
CM_ SG_ 1522 BMS_BattTempSensorNum18 "18号温度探针温度值";
CM_ SG_ 1522 BMS_BattTempSensorNum19 "19号温度探针温度值";
CM_ SG_ 1522 BMS_BattTempSensorNum20 "20号温度探针温度值";
CM_ SG_ 1522 BMS_BattTempSensorNum21 "21号温度探针温度值";
CM_ SG_ 1522 BMS_BattTempSensorNum22 "22号温度探针温度值";
CM_ SG_ 1522 BMS_BattTempSensorNum23 "23号温度探针温度值";
CM_ SG_ 1522 BMS_BattTempSensorNum24 "24号温度探针温度值";
CM_ SG_ 1523 BMS_BattTempSensorNum25 "25号温度探针温度值";
CM_ SG_ 1523 BMS_BattTempSensorNum26 "26号温度探针温度值";
CM_ SG_ 1523 BMS_BattTempSensorNum27 "27号温度探针温度值";
CM_ SG_ 1523 BMS_BattTempSensorNum28 "28号温度探针温度值";
CM_ SG_ 1523 BMS_BattTempSensorNum29 "29号温度探针温度值";
CM_ SG_ 1523 BMS_BattTempSensorNum30 "30号温度探针温度值";
CM_ SG_ 1523 BMS_BattTempSensorNum31 "31号温度探针温度值";
CM_ SG_ 1523 BMS_BattTempSensorNum32 "32号温度探针温度值";
CM_ SG_ 1524 BMS_BattTempSensorNum33 "33号温度探针温度值";
CM_ SG_ 1524 BMS_BattTempSensorNum34 "34号温度探针温度值";
CM_ SG_ 1524 BMS_BattTempSensorNum35 "35号温度探针温度值";
CM_ SG_ 1524 BMS_BattTempSensorNum36 "36号温度探针温度值";
CM_ SG_ 1524 BMS_BattTempSensorNum37 "37号温度探针温度值";
CM_ SG_ 1524 BMS_BattTempSensorNum38 "38号温度探针温度值";
CM_ SG_ 1524 BMS_BattTempSensorNum39 "39号温度探针温度值";
CM_ SG_ 1524 BMS_BattTempSensorNum40 "40号温度探针温度值";
CM_ SG_ 1473 GW_SWVersion_Supplier "GW软件供应商代码（有电咖定义，如A/B/C分别代表A点/B点/C点供应商，定义参考诊断规范版本号定义）";
CM_ SG_ 1473 GW_SWVersion_Main "GW软件版本-大版本";
CM_ SG_ 1473 GW_SWVersion_Sub1 "GW软件版本-小版本第一位";
CM_ SG_ 1473 GW_SWVersion_Sub2 "GW软件版本-小版本第二位";
CM_ SG_ 1473 GW_HWVersion_Supplier "GW硬件件供应商代码";
CM_ SG_ 1473 GW_HWVersion_Main "GW硬件版本-大版本";
CM_ SG_ 1473 GW_HWVersion_Sub1 "GW硬件版本-小版本第一位";
CM_ SG_ 1473 GW_HWVersion_Sub2 "GW硬件版本-小版本第二位";

BA_DEF_ BO_  "NmMessage" ENUM "No","Yes";
BA_DEF_ BO_  "GenMsgSendType" ENUM  "cyclic","IfActive","Event","CA","CE","NoMsgSendType";
BA_DEF_ BO_  "GenMsgCycleTime" INT 0 0;
BA_DEF_ SG_  "GenSigSendType" ENUM  "cyclic","OnChange","OnWrite","IfActive","OnChangeWithRepetition","OnWriteWithRepetition","IfActiveWithRepetition","NoSigSendType","OnChangeAndIfActive", "OnChangeAndIfActiveWithRepetition","CA","CE","Event";
BA_DEF_ SG_  "GenSigStartValue" INT 0 0;

BA_DEF_DEF_  "NmMessage" "No";
BA_DEF_DEF_  "GenMsgSendType" "cyclic";
BA_DEF_DEF_  "GenMsgCycleTime" 0;
BA_DEF_DEF_  "GenSigSendType" "cyclic";
BA_DEF_DEF_  "GenSigStartValue" 0;
BA_ "GenMsgCycleTime" BO_ 665 100;
BA_ "GenSigStartValue" SG_ 665 FLWM_WinPstSt 127;
BA_ "GenSigStartValue" SG_ 665 FRWM_WinPstSt 127;
BA_ "GenSigStartValue" SG_ 665 RLWM_WinPstSt 127;
BA_ "GenSigStartValue" SG_ 665 RRWM_WinPstSt 127;
BA_ "GenMsgCycleTime" BO_ 583 100;
BA_ "GenSigSendType" SG_ 583 BCM_StartWarning 1;
BA_ "GenSigSendType" SG_ 583 BCM_PowerOffWarning 1;
BA_ "GenSigSendType" SG_ 583 BCM_PowerONWarning 1;
BA_ "GenMsgCycleTime" BO_ 1282 100;
BA_ "GenMsgCycleTime" BO_ 277 100;
BA_ "GenMsgCycleTime" BO_ 1632 100;
BA_ "GenMsgCycleTime" BO_ 261 100;
BA_ "GenMsgCycleTime" BO_ 1556 100;
BA_ "GenSigStartValue" SG_ 1556 OBC_TempAct 40;
BA_ "GenMsgCycleTime" BO_ 1553 100;
BA_ "GenSigStartValue" SG_ 1553 OBC_SoketTemp_N 40;
BA_ "GenSigStartValue" SG_ 1553 OBC_CoolantPlateTemp 55;
BA_ "GenSigStartValue" SG_ 1553 OBC_SoketTemp_L 40;
BA_ "GenMsgCycleTime" BO_ 1552 100;
BA_ "GenMsgCycleTime" BO_ 1360 200;
BA_ "GenMsgCycleTime" BO_ 392 100;
BA_ "GenMsgCycleTime" BO_ 905 100;
BA_ "GenSigStartValue" SG_ 905 DCDC_TempAct 40;
BA_ "GenMsgCycleTime" BO_ 1512 10000;
BA_ "GenMsgCycleTime" BO_ 1513 10000;
BA_ "GenMsgCycleTime" BO_ 1514 10000;
BA_ "GenMsgCycleTime" BO_ 1515 10000;
BA_ "GenMsgCycleTime" BO_ 1516 10000;
BA_ "GenMsgCycleTime" BO_ 1517 10000;
BA_ "GenMsgCycleTime" BO_ 1518 10000;
BA_ "GenMsgCycleTime" BO_ 1488 10000;
BA_ "GenMsgCycleTime" BO_ 1489 10000;
BA_ "GenMsgCycleTime" BO_ 1490 10000;
BA_ "GenMsgCycleTime" BO_ 1491 10000;
BA_ "GenMsgCycleTime" BO_ 1496 10000;
BA_ "GenMsgCycleTime" BO_ 1497 10000;
BA_ "GenMsgCycleTime" BO_ 1498 10000;
BA_ "GenMsgCycleTime" BO_ 1499 10000;
BA_ "GenMsgCycleTime" BO_ 1519 10000;
BA_ "GenMsgCycleTime" BO_ 1776 10000;
BA_ "GenMsgCycleTime" BO_ 1493 10000;
BA_ "GenSigStartValue" SG_ 1493 DSM_SWVersion_Supplier 10;
BA_ "GenSigStartValue" SG_ 1493 DSM_SWVersion_Main 10;
BA_ "GenSigStartValue" SG_ 1493 DSM_HWVersion_Supplier 10;
BA_ "GenSigStartValue" SG_ 1493 DSM_HWVersion_Main 10;
BA_ "GenMsgCycleTime" BO_ 1500 10000;
BA_ "GenSigStartValue" SG_ 1500 AVAS_SWVersion_Supplier 10;
BA_ "GenSigStartValue" SG_ 1500 AVAS_SWVersion_Main 10;
BA_ "GenSigStartValue" SG_ 1500 AVAS_HWVersion_Supplier 10;
BA_ "GenSigStartValue" SG_ 1500 AVAS_HWVersion_Main 10;
BA_ "GenMsgCycleTime" BO_ 1501 10000;
BA_ "GenSigStartValue" SG_ 1501 BCM_SWVersion_Supplier 10;
BA_ "GenSigStartValue" SG_ 1501 BCM_SWVersion_Main 10;
BA_ "GenSigStartValue" SG_ 1501 BCM_HWVersion_Supplier 10;
BA_ "GenSigStartValue" SG_ 1501 BCM_HWVersion_Main 10;
BA_ "GenMsgCycleTime" BO_ 1502 10000;
BA_ "GenSigStartValue" SG_ 1502 PLG_SWVersion_Supplier 10;
BA_ "GenSigStartValue" SG_ 1502 PLG_SWVersion_Main 10;
BA_ "GenSigStartValue" SG_ 1502 PLG_HWVersion_Supplier 10;
BA_ "GenSigStartValue" SG_ 1502 PLG_HWVersion_Main 10;
BA_ "GenMsgCycleTime" BO_ 1504 5000;
BA_ "GenSigStartValue" SG_ 1504 BMS_SWVersion_Supplier 10;
BA_ "GenSigStartValue" SG_ 1504 BMS_SWVersion_Main 10;
BA_ "GenSigStartValue" SG_ 1504 BMS_HWVersion_Supplier 10;
BA_ "GenSigStartValue" SG_ 1504 BMS_HWVersion_Main 10;
BA_ "GenMsgCycleTime" BO_ 1505 5000;
BA_ "GenSigStartValue" SG_ 1505 VCU_SWVersion_Supplier 10;
BA_ "GenSigStartValue" SG_ 1505 VCU_SWVersion_Main 10;
BA_ "GenSigStartValue" SG_ 1505 VCU_HWVersion_Supplier 10;
BA_ "GenSigStartValue" SG_ 1505 VCU_HWVersion_Main 10;
BA_ "GenMsgCycleTime" BO_ 1506 5000;
BA_ "GenSigStartValue" SG_ 1506 MCU_SWVersion_Supplier 10;
BA_ "GenSigStartValue" SG_ 1506 MCU_SWVersion_Main 10;
BA_ "GenSigStartValue" SG_ 1506 MCU_HWVersion_Supplier 10;
BA_ "GenSigStartValue" SG_ 1506 MCU_HWVersion_Main 10;
BA_ "GenMsgCycleTime" BO_ 1507 5000;
BA_ "GenSigStartValue" SG_ 1507 DCDC_SWVersion_Supplier 10;
BA_ "GenSigStartValue" SG_ 1507 DCDC_SWVersion_Main 10;
BA_ "GenSigStartValue" SG_ 1507 DCDC_HWVersion_Supplier 10;
BA_ "GenSigStartValue" SG_ 1507 DCDC_HWVersion_Main 10;
BA_ "GenMsgCycleTime" BO_ 1508 5000;
BA_ "GenSigStartValue" SG_ 1508 OBC_SWVersion_Supplier 10;
BA_ "GenSigStartValue" SG_ 1508 OBC_SWVersion_Main 10;
BA_ "GenSigStartValue" SG_ 1508 OBC_HWVersion_Supplier 10;
BA_ "GenSigStartValue" SG_ 1508 OBC_HWVersion_Main 10;
BA_ "GenMsgCycleTime" BO_ 1510 10000;
BA_ "GenSigStartValue" SG_ 1510 ACU_SWVersion_Supplier 10;
BA_ "GenSigStartValue" SG_ 1510 ACU_SWVersion_Main 10;
BA_ "GenSigStartValue" SG_ 1510 ACU_HWVersion_Supplier 10;
BA_ "GenSigStartValue" SG_ 1510 ACU_HWVersion_Main 10;
BA_ "GenMsgCycleTime" BO_ 1511 10000;
BA_ "GenSigStartValue" SG_ 1511 WPTC_SWVersion_Supplier 10;
BA_ "GenSigStartValue" SG_ 1511 WPTC_SWVersion_Main 10;
BA_ "GenSigStartValue" SG_ 1511 WPTC_HWVersion_Supplier 10;
BA_ "GenSigStartValue" SG_ 1511 WPTC_HWVersion_Main 10;
BA_ "GenMsgCycleTime" BO_ 804 100;
BA_ "GenMsgCycleTime" BO_ 835 100;
BA_ "GenMsgCycleTime" BO_ 774 1000;
BA_ "GenMsgCycleTime" BO_ 528 10;
BA_ "GenMsgCycleTime" BO_ 596 100;
BA_ "GenMsgCycleTime" BO_ 1009 200;
BA_ "GenSigSendType" SG_ 1009 DVR_ControlResult 1;
BA_ "GenSigSendType" SG_ 1009 DVR_GsensorCrashStatus 1;
BA_ "GenSigSendType" SG_ 1009 DVR_requestWiFiopen 1;
BA_ "GenSigSendType" SG_ 1009 DVR_Network_Set 1;
BA_ "GenSigSendType" SG_ 1009 DVR_LocalPhotographResult 1;
BA_ "GenSigSendType" SG_ 1009 DVR_LocalRecordResult 1;
BA_ "GenSigSendType" SG_ 1009 DVR_Frameinterval 1;
BA_ "GenSigSendType" SG_ 1009 DVR_FrameCount 1;
BA_ "GenSigSendType" SG_ 1009 DVR_PlayRate 1;
BA_ "GenSigSendType" SG_ 1009 DVR_LocalTimelapseRecordResult 1;
BA_ "GenMsgCycleTime" BO_ 676 100;
BA_ "GenSigSendType" SG_ 676 DSM_MemoryAlarm 1;
BA_ "GenSigSendType" SG_ 676 DSM_DeleteMemoryRsp 1;
BA_ "GenSigSendType" SG_ 676 DSM_GetMemoryRsp 1;
BA_ "GenSigStartValue" SG_ 676 DSM_PSMheattemp 63;
BA_ "GenSigStartValue" SG_ 676 DSM_DSMheattemp 63;
BA_ "GenMsgSendType" BO_ 24 2;
BA_ "GenSigSendType" SG_ 24 BCM_AuthReq_TBOX_NSM_Code 1;
BA_ "GenMsgSendType" BO_ 25 2;
BA_ "GenSigSendType" SG_ 25 TBOX_AuthResp_BCM_Code 1;
BA_ "GenMsgCycleTime" BO_ 256 20;
BA_ "GenMsgCycleTime" BO_ 258 20;
BA_ "GenSigStartValue" SG_ 258 BMS_Insulation_R 1022;
BA_ "GenMsgCycleTime" BO_ 274 100;
BA_ "GenMsgCycleTime" BO_ 278 100;
BA_ "GenMsgCycleTime" BO_ 288 20;
BA_ "GenSigStartValue" SG_ 288 MCU_MotorActualTorque 32766;
BA_ "GenSigStartValue" SG_ 288 MCU_MotorSpeed 65534;
BA_ "GenMsgCycleTime" BO_ 290 100;
BA_ "GenSigStartValue" SG_ 290 MCU_MaxAvailableTorque 2046;
BA_ "GenSigStartValue" SG_ 290 MCU_MinAvailableTorque 2046;
BA_ "GenMsgCycleTime" BO_ 289 20;
BA_ "GenMsgCycleTime" BO_ 291 100;
BA_ "GenSigStartValue" SG_ 291 MCU_DC_linkVoltage 1022;
BA_ "GenSigStartValue" SG_ 291 MCU_DC_linkCurrent 2046;
BA_ "GenSigStartValue" SG_ 291 MCU_InverterTemp 254;
BA_ "GenSigStartValue" SG_ 291 MCU_MotorTemp 254;
BA_ "GenSigStartValue" SG_ 291 MCU_WaterTemp 254;
BA_ "GenSigStartValue" SG_ 291 MCU_MotorCount 1;
BA_ "GenSigStartValue" SG_ 291 MCU_MotorSeqNum 1;
BA_ "GenMsgCycleTime" BO_ 292 100;
BA_ "GenSigStartValue" SG_ 292 MCU_RotorTemp 254;
BA_ "GenSigStartValue" SG_ 292 MCU_Motoroffset 1022;
BA_ "GenMsgCycleTime" BO_ 545 100;
BA_ "GenSigSendType" SG_ 545 TBOX_WelcomefuncReq 1;
BA_ "GenMsgCycleTime" BO_ 599 100;
BA_ "GenMsgCycleTime" BO_ 849 100;
BA_ "GenSigSendType" SG_ 849 TBOX_BCM_DoorLock_Control_4G 1;
BA_ "GenSigSendType" SG_ 849 TBOX_BCM_CarLocating 1;
BA_ "GenSigSendType" SG_ 849 TBOX_PLG_TrunkunLock 1;
BA_ "GenSigSendType" SG_ 849 TBOX_DSM_heatSwitch 1;
BA_ "GenSigSendType" SG_ 849 TBOX_PSM_heatSwitch 1;
BA_ "GenSigSendType" SG_ 849 TBOX_DSM_GetMemoryReq 1;
BA_ "GenSigSendType" SG_ 849 TBOX_BCM_DoorLock_Control_BT 1;
BA_ "GenSigSendType" SG_ 849 TBOX_DSM_Targtemp 1;
BA_ "GenSigStartValue" SG_ 849 TBOX_DSM_Targtemp 63;
BA_ "GenSigSendType" SG_ 849 TBOX_Publish_Wakeup 1;
BA_ "GenSigSendType" SG_ 849 TBOX_PSM_Targtemp 1;
BA_ "GenSigStartValue" SG_ 849 TBOX_PSM_Targtemp 63;
BA_ "GenSigSendType" SG_ 849 TBOX_BCM_forceclose_MD1 1;
BA_ "GenSigSendType" SG_ 849 TBOX_BCM_forceclose_Mrollo 1;
BA_ "GenSigSendType" SG_ 849 TBOX_BCM_stopsunroof 1;
BA_ "GenSigSendType" SG_ 849 TBOX_BCM_PowerON_Request 1;
BA_ "GenSigSendType" SG_ 849 TBOX_BCM_SrfSlidePosReq 1;
BA_ "GenSigStartValue" SG_ 849 TBOX_BCM_SrfSlidePosReq 254;
BA_ "GenSigSendType" SG_ 849 TBOX_BCM_ShadeSlidePosReq 1;
BA_ "GenSigStartValue" SG_ 849 TBOX_BCM_ShadeSlidePosReq 254;
BA_ "GenSigSendType" SG_ 849 TBOX_BCM_FLWindowsControl 1;
BA_ "GenSigSendType" SG_ 849 TBOX_BCM_FRWindowsControl 1;
BA_ "GenSigSendType" SG_ 849 TBOX_BCM_RLWindowsControl 1;
BA_ "GenSigSendType" SG_ 849 TBOX_BCM_RRWindowsControl 1;
BA_ "GenMsgCycleTime" BO_ 850 100;
BA_ "GenSigSendType" SG_ 850 TBOX_AC_SystemSet 1;
BA_ "GenSigSendType" SG_ 850 TBOX_AC_Cycle 1;
BA_ "GenSigSendType" SG_ 850 TBOX_AC_EAC_Control 1;
BA_ "GenSigSendType" SG_ 850 TBOX_AC_AutoMode_Set 1;
BA_ "GenSigSendType" SG_ 850 TBOX_AC_WindMode_Set 1;
BA_ "GenSigSendType" SG_ 850 TBOX_AC_BlowingRate_Set 1;
BA_ "GenSigSendType" SG_ 850 TBOX_AC_APTCSW_Set 1;
BA_ "GenSigSendType" SG_ 850 TBOX_AC_Temp_set 1;
BA_ "GenSigSendType" SG_ 850 TBOX_RemotePhotograph 1;
BA_ "GenSigSendType" SG_ 850 TBOX_PLG_OpenControl 1;
BA_ "GenSigSendType" SG_ 850 TBOX_BCM_FLWindowsVoiControl 1;
BA_ "GenSigSendType" SG_ 850 TBOX_BCM_FRWindowsVoiControl 1;
BA_ "GenSigSendType" SG_ 850 TBOX_BCM_RLWindowsVoiControl 1;
BA_ "GenSigSendType" SG_ 850 TBOX_BCM_RRWindowsVoiControl 1;
BA_ "GenMsgCycleTime" BO_ 851 100;
BA_ "GenSigSendType" SG_ 851 TBOX_VCU_12vChargeReq 1;
BA_ "GenSigSendType" SG_ 851 TBOX_ChargeDepthSet 1;
BA_ "GenSigSendType" SG_ 851 TBOX_APS_EPSStrgWhlAngZero 1;
BA_ "GenSigSendType" SG_ 851 TBOX_APS_PoewerOff_Request 1;
BA_ "GenSigSendType" SG_ 851 TBOX_APS_PowerON_Request 1;
BA_ "GenMsgCycleTime" BO_ 853 1000;
BA_ "GenSigStartValue" SG_ 853 TBOX_TimeSyncData_Month 1;
BA_ "GenSigStartValue" SG_ 853 TBOX_TimeSyncData_Day 1;
BA_ "NmMessage" BO_ 1026 1;
BA_ "GenMsgSendType" BO_ 1026 2;
BA_ "GenSigSendType" SG_ 1026 TBOX_NM_DA 1;
BA_ "GenSigSendType" SG_ 1026 TBOX_NM_ALIVE 1;
BA_ "GenSigSendType" SG_ 1026 TBOX_NM_RING 1;
BA_ "GenSigSendType" SG_ 1026 TBOX_NM_LIMPHOME 1;
BA_ "GenSigSendType" SG_ 1026 TBOX_NM_SLEEP_INDICATION 1;
BA_ "GenSigSendType" SG_ 1026 TBOX_NM_SLEEP_ACK 1;
BA_ "NmMessage" BO_ 1028 1;
BA_ "GenMsgSendType" BO_ 1028 2;
BA_ "GenSigSendType" SG_ 1028 GW_Tbox_NM_DA 1;
BA_ "GenSigSendType" SG_ 1028 GW_Tbox_NM_ALIVE 1;
BA_ "GenSigSendType" SG_ 1028 GW_Tbox_NM_RING 1;
BA_ "GenSigSendType" SG_ 1028 GW_Tbox_NM_LIMPHOME 1;
BA_ "GenSigSendType" SG_ 1028 GW_Tbox_NM_SLEEP_Ind 1;
BA_ "GenSigSendType" SG_ 1028 GW_Tbox_NM_SLEEP_ACK 1;
BA_ "GenMsgCycleTime" BO_ 1299 500;
BA_ "GenSigStartValue" SG_ 1299 BMS_MaxTemp 255;
BA_ "GenSigStartValue" SG_ 1299 BMS_MinTemp 255;
BA_ "GenSigStartValue" SG_ 1299 BMS_BattTempDev 255;
BA_ "GenSigStartValue" SG_ 1299 BMS_CCTemp1 255;
BA_ "GenSigStartValue" SG_ 1299 BMS_CCTemp2 255;
BA_ "GenMsgCycleTime" BO_ 1300 500;
BA_ "GenMsgCycleTime" BO_ 1328 1000;
BA_ "GenMsgCycleTime" BO_ 1329 1000;
BA_ "GenMsgCycleTime" BO_ 1330 1000;
BA_ "GenMsgCycleTime" BO_ 1331 1000;
BA_ "GenMsgCycleTime" BO_ 1332 1000;
BA_ "GenMsgCycleTime" BO_ 1333 1000;
BA_ "GenMsgCycleTime" BO_ 1334 1000;
BA_ "GenMsgCycleTime" BO_ 1335 1000;
BA_ "GenMsgCycleTime" BO_ 1336 1000;
BA_ "GenMsgCycleTime" BO_ 1337 1000;
BA_ "GenMsgCycleTime" BO_ 1338 1000;
BA_ "GenMsgCycleTime" BO_ 1339 1000;
BA_ "GenMsgCycleTime" BO_ 1340 1000;
BA_ "GenMsgCycleTime" BO_ 1341 1000;
BA_ "GenMsgCycleTime" BO_ 1342 1000;
BA_ "GenMsgCycleTime" BO_ 1343 1000;
BA_ "GenMsgCycleTime" BO_ 1344 1000;
BA_ "GenMsgCycleTime" BO_ 1345 1000;
BA_ "GenMsgCycleTime" BO_ 1346 1000;
BA_ "GenMsgCycleTime" BO_ 1347 1000;
BA_ "GenMsgCycleTime" BO_ 1348 1000;
BA_ "GenMsgCycleTime" BO_ 1349 1000;
BA_ "GenMsgCycleTime" BO_ 1350 1000;
BA_ "GenMsgCycleTime" BO_ 1351 1000;
BA_ "GenMsgCycleTime" BO_ 1352 1000;
BA_ "GenMsgCycleTime" BO_ 1353 1000;
BA_ "GenMsgCycleTime" BO_ 1354 1000;
BA_ "GenMsgCycleTime" BO_ 1492 10000;
BA_ "GenMsgCycleTime" BO_ 1520 1000;
BA_ "GenMsgCycleTime" BO_ 1521 1000;
BA_ "GenMsgCycleTime" BO_ 1522 1000;
BA_ "GenMsgCycleTime" BO_ 1523 1000;
BA_ "GenMsgCycleTime" BO_ 1524 1000;
BA_ "GenMsgCycleTime" BO_ 1473 10000;
VAL_ 665 CSW_Key_StartStop 3 "Reserved" 2 "long pressed" 1 "short pressed" 0 "Key not pressed" ;
VAL_ 665 CSW_Key_AutoParking 3 "Reserved" 2 "Reserved" 1 "pressed" 0 "Key not pressed" ;
VAL_ 665 CSW_Key_LiftGate 3 "Reserved" 2 "Reserved" 1 "pressed" 0 "Key not pressed" ;
VAL_ 665 CSW_WindowLOCK 3 "Reserved" 2 "Reserved" 1 "pressed" 0 "Key not pressed" ;
VAL_ 665 CSW_Key_FrontDefrost 3 "Reserved" 2 "Reserved" 1 "pressed" 0 "Key not pressed" ;
VAL_ 665 ESCL_DiagError 1 "Authenticatio error" 0 "Authenticatio ok" ;
VAL_ 665 ESCL_authentification_error 1 "Authenticatio error" 0 "Authenticatio ok" ;
VAL_ 665 ESCL_unlock_status 1 "unlocked" 0 "not unlocked" ;
VAL_ 665 ESCL_lock_status 1 "locked" 0 "not locked" ;
VAL_ 665 FLWM_AntiPinchDetecte 1 "Detected" 0 "No Detected" ;
VAL_ 665 FRWM_AntiPinchDetecte 1 "Detected" 0 "No Detected" ;
VAL_ 665 RLWM_AntiPinchDetecte 1 "Detected" 0 "No Detected" ;
VAL_ 665 RRWM_AntiPinchDetecte 1 "Detected" 0 "No Detected" ;
VAL_ 665 FLWM_Opend 1 "Opend" 0 "No Opend" ;
VAL_ 665 FLWM_Closed 1 "Closed" 0 "No Closed" ;
VAL_ 665 FRWM_Opend 1 "Opend" 0 "No Opend" ;
VAL_ 665 FRWM_Closed 1 "Closed" 0 "No Closed" ;
VAL_ 665 RLWM_Opend 1 "Opend" 0 "No Opend" ;
VAL_ 665 RLWM_Closed 1 "Closed" 0 "No Closed" ;
VAL_ 665 RRWM_Opend 1 "Opend" 0 "No Opend" ;
VAL_ 665 RRWM_Closed 1 "Closed" 0 "No Closed" ;
VAL_ 665 FLWM_WinMoveSt 3 "Invalid" 2 "Window Openning" 1 "Window Closing" 0 "Stopped" ;
VAL_ 665 FRWM_WinMoveSt 3 "Invalid" 2 "Window Openning" 1 "Window Closing" 0 "Stopped" ;
VAL_ 665 RLWM_WinMoveSt 3 "Invalid" 2 "Window Openning" 1 "Window Closing" 0 "Stopped" ;
VAL_ 665 RRWM_WinMoveSt 3 "Invalid" 2 "Window Openning" 1 "Window Closing" 0 "Stopped" ;
VAL_ 583 BCM_StartWarning 7 "Reserved" 6 "Reserved" 5 "Reserved" 4 "Reserved" 3 "无法进入P档，请重新上电（仪表提醒）" 2 "请确认档位在P档后再次启动（仪表提醒）" 1 "车内未检测到合法钥匙（仪表提醒）" 0 "默认值" ;
VAL_ 583 BCM_PowerOffWarning 7 "Reserved" 6 "Reserved" 5 "Reserved" 4 "Reserved" 3 "Reserved" 2 "紧急下电" 1 "请在P档或者N档静止时下电（仪表提醒）" 0 "默认值（发生正常下电，上电或下电稳态）" ;
VAL_ 583 BCM_PowerONWarning 7 "Reserved" 6 "Reserved" 5 "钥匙不匹配（仪表提醒）" 4 "预留" 3 "远程禁止上电" 2 "转向管柱锁未解锁，请转动方向盘再次上电（仪表提醒，ESCL取消后此信号不触发）" 1 "车内未检测到合法钥匙（仪表提醒）" 0 "默认值" ;
VAL_ 583 BCM_AuthSts 3 "保留" 2 "防盗认证成功" 1 "防盗认证失败" 0 "上电默认状态" ;
VAL_ 583 BCM_ESCLSysFail 3 "预留" 2 "预留" 1 "故障" 0 "无故障" ;
VAL_ 583 BCM_LODO_Reminder 3 "预留" 2 "预留" 1 "提醒" 0 "无提醒" ;
VAL_ 583 BCM_brakeLightfail 3 "预留" 2 "预留" 1 "提醒" 0 "无提醒" ;
VAL_ 1282 TPMS_FL_Warning_Sts 1 "Warning" 0 "No Warning" ;
VAL_ 1282 TPMS_FR_Warning_Sts 1 "Warning" 0 "No Warning" ;
VAL_ 1282 TPMS_RL_Warning_Sts 1 "Warning" 0 "No Warning" ;
VAL_ 1282 TPMS_RR_Warning_Sts 1 "Warning" 0 "No Warning" ;
VAL_ 1282 TPMS_FL_Fault_Sts 1 "Fault" 0 "No Fault" ;
VAL_ 1282 TPMS_FR_Fault_Sts 1 "Fault" 0 "No Fault" ;
VAL_ 1282 TPMS_RL_Fault_Sts 1 "Fault" 0 "No Fault" ;
VAL_ 1282 TPMS_RR_Fault_Sts 1 "Fault" 0 "No Fault" ;
VAL_ 1282 TPMS_FL_leakage_Sts 1 "Quik_leakage" 0 "Normal" ;
VAL_ 1282 TPMS_FR_leakage_Sts 1 "Quik_leakage" 0 "Normal" ;
VAL_ 1282 TPMS_RL_leakage_Sts 1 "Quik_leakage" 0 "Normal" ;
VAL_ 1282 TPMS_RR_leakage_Sts 1 "Quik_leakage" 0 "Normal" ;
VAL_ 1282 TPMS_FLPressure_Sts 3 "Reserved" 2 "high_pressure" 1 "Low_pressure" 0 "Normal" ;
VAL_ 1282 TPMS_FRPressure_Sts 3 "Reserved" 2 "high_pressure" 1 "Low_pressure" 0 "Normal" ;
VAL_ 1282 TPMS_RLPressure_Sts 3 "Reserved" 2 "high_pressure" 1 "Low_pressure" 0 "Normal" ;
VAL_ 1282 TPMS_RRPressure_Sts 3 "Reserved" 2 "high_pressure" 1 "Low_pressure" 0 "Normal" ;
VAL_ 1282 TPMS_FL_HighTemp_Sts 1 "High_Temp" 0 "Normal" ;
VAL_ 1282 TPMS_FR_HighTemp_Sts 1 "High_Temp" 0 "Normal" ;
VAL_ 1282 TPMS_RL_HighTemp_Sts 1 "High_Temp" 0 "Normal" ;
VAL_ 1282 TPMS_RR_HighTemp_Sts 1 "High_Temp" 0 "Normal" ;
VAL_ 1282 TPMS_FL_battery_Sts 1 "battery_low" 0 "Normal" ;
VAL_ 1282 TPMS_FR_battery_Sts 1 "battery_low" 0 "Normal" ;
VAL_ 1282 TPMS_RL_battery_Sts 1 "battery_low" 0 "Normal" ;
VAL_ 1282 TPMS_RR_battery_Sts 1 "battery_low" 0 "Normal" ;
VAL_ 1282 TPMS_FL_SensorError_Sts 1 "Sensor_Error" 0 "Normal" ;
VAL_ 1282 TPMS_FR_SensorError_Sts 1 "Sensor_Error" 0 "Normal" ;
VAL_ 1282 TPMS_RL_SensorError_Sts 1 "Sensor_Error" 0 "Normal" ;
VAL_ 1282 TPMS_RR_SensorError_Sts 1 "Sensor_Error" 0 "Normal" ;
VAL_ 1282 TPMS_FL_failure_Sts 1 "Sensor_failure" 0 "Normal" ;
VAL_ 1282 TPMS_FR_failure_Sts 1 "Sensor_failure" 0 "Normal" ;
VAL_ 1282 TPMS_RL_failure_Sts 1 "Sensor_failure" 0 "Normal" ;
VAL_ 1282 TPMS_RR_failure_Sts 1 "Sensor_failure" 0 "Normal" ;
VAL_ 1282 TPMS_FL_learn_Sts 3 "ID_repeat" 2 "Learn_succcess" 1 "Waiting_learn" 0 "No_learn" ;
VAL_ 1282 TPMS_FR_learn_Sts 3 "ID_repeat" 2 "Learn_succcess" 1 "Waiting_learn" 0 "No_learn" ;
VAL_ 1282 TPMS_RL_learn_Sts 3 "ID_repeat" 2 "Learn_succcess" 1 "Waiting_learn" 0 "No_learn" ;
VAL_ 1282 TPMS_RR_learn_Sts 3 "ID_repeat" 2 "Learn_succcess" 1 "Waiting_learn" 0 "No_learn" ;
VAL_ 1282 TPMS_FL_CRC_Error 1 "Error" 0 "No_Error" ;
VAL_ 1282 TPMS_FR_CRC_Error 1 "Error" 0 "No_Error" ;
VAL_ 1282 TPMS_RL_CRC_Error 1 "Error" 0 "No_Error" ;
VAL_ 1282 TPMS_RR_CRC_Error 1 "Error" 0 "No_Error" ;
VAL_ 1632 DCDC_OverTemp 1 "Fault" 0 "Not Fault" ;
VAL_ 1632 DCDC_DischargeFail 1 "Fault" 0 "Not Fault" ;
VAL_ 1632 DCDC_TBOX_WorkSts 3 "无效" 2 "异常" 1 "工作" 0 "断开" ;
VAL_ 1632 DCDC_TBOX_TempFault 1 "Fault" 0 "Not Fault" ;
VAL_ 1632 DCDC_InsideVolHig 1 "Fault" 0 "Not Fault" ;
VAL_ 1632 DCDC_InsideVolLow 1 "Fault" 0 "Not Fault" ;
VAL_ 1632 DCDC_OutputCurHig 1 "Fault" 0 "Not Fault" ;
VAL_ 1632 DCDC_OutputVolHig 1 "Fault" 0 "Not Fault" ;
VAL_ 1632 DCDC_OutputVolLow 1 "Fault" 0 "Not Fault" ;
VAL_ 1632 DCDC_InputCurHig 1 "Fault" 0 "Not Fault" ;
VAL_ 1632 DCDC_InputVolHig 1 "Fault" 0 "Not Fault" ;
VAL_ 1632 DCDC_InputVolLow 1 "Fault" 0 "Not Fault" ;
VAL_ 1632 DCDC_OutputOpen 1 "Fault" 0 "Not Fault" ;
VAL_ 1632 DCDC_HardFail 1 "Fault" 0 "Not Fault" ;
VAL_ 1632 DCDC_InsideShotCirc 1 "Fault" 0 "Not Fault" ;
VAL_ 1632 DCDC_OutputShotCirc 1 "Fault" 0 "Not Fault" ;
VAL_ 1632 DCDC_CommunTimeOut 1 "Fault" 0 "Not Fault" ;
VAL_ 1632 DCDC_InsideCurHig 1 "Fault" 0 "Not Fault" ;
VAL_ 261 BMS_ChrRequest 7 "预留" 6 "预留" 5 "预留" 4 "预留" 3 "预留" 2 "预留" 1 "Request" 0 "No Request" ;
VAL_ 261 BMS_VCU_TotalEnergy 524287 "Invalid" ;
VAL_ 1556 OBC_ElockSts 3 "Locked Fail" 2 "Unlocked  Fail" 1 "Locked" 0 "Unlocked" ;
VAL_ 1556 OBC_ChrgLockSts 7 "预留" 6 "解锁失败" 5 "上锁失败" 4 "正在上锁" 3 "正在解锁" 2 "上锁" 1 "解锁" 0 "默认" ;
VAL_ 1556 OBC_RecoTimingSts 1 "Active" 0 "Inactive" ;
VAL_ 1553 OBC_SocketTempHig 1 "Fault" 0 "Not Fault" ;
VAL_ 1553 OBC_InputVolLow 1 "Fault" 0 "Not Fault" ;
VAL_ 1553 OBC_HardTempHig 1 "Fault" 0 "Not Fault" ;
VAL_ 1553 OBC_OutputShorCir 1 "Fault" 0 "Not Fault" ;
VAL_ 1553 OBC_OutputVolHig 1 "Fault" 0 "Not Fault" ;
VAL_ 1553 OBC_OutputVolLow 1 "Fault" 0 "Not Fault" ;
VAL_ 1553 OBC_PFCOutputVolHig 1 "Fault" 0 "Not Fault" ;
VAL_ 1553 OBC_PFCOutputVolLow 1 "Fault" 0 "Not Fault" ;
VAL_ 1553 OBC_CommTimeOut 1 "Fault" 0 "Not Fault" ;
VAL_ 1553 OBC_InputCurHig 1 "Fault" 0 "Not Fault" ;
VAL_ 1553 OBC_InputVolHig 1 "Fault" 0 "Not Fault" ;
VAL_ 1553 OBC_BMSVolLow 1 "Fault" 0 "Not Fault" ;
VAL_ 1553 OBC_BMSVolHig 1 "Fault" 0 "Not Fault" ;
VAL_ 1553 OBC_ContraryConnect 1 "Fault" 0 "Not Fault" ;
VAL_ 1553 OBC_InsideComTimeOut 1 "Fault" 0 "Not Fault" ;
VAL_ 1553 OBC_ElockFail 1 "Fault" 0 "Not Fault" ;
VAL_ 1553 OBC_HardFail 1 "Fault" 0 "Not Fault" ;
VAL_ 1553 OBC_OutputCurHig 1 "Fault" 0 "Not Fault" ;
VAL_ 1552 OBC_CC_Status 7 "预留" 6 "CC接地" 5 "100Ohm" 4 "220Ohm" 3 "680Ohm" 2 "1500Ohm" 1 "半连接" 0 "无连接" ;
VAL_ 1360 OBC_ChrgFailLevel 7 "预留" 6 "预留" 5 "预留" 4 "预留" 3 "三级故障" 2 "二级故障" 1 "一级故障" 0 "无故障" ;
VAL_ 1360 OBC_CCLineSts 1 "Connected" 0 "Not connected" ;
VAL_ 1360 OBC_DeratingSts 1 "Derating" 0 "No derating" ;
VAL_ 1360 OBC_ChrgSts 7 "Reserved" 6 "Aftercharge" 5 "Shutdown" 4 "Failure" 3 "PowerActive" 2 "Standby" 1 "PreStart" 0 "Initialization" ;
VAL_ 1360 OBC_OBCStsCPLine 1 "Connected" 0 "Not connected" ;
VAL_ 1360 OBC_S2Sts 1 "Closed" 0 "Opened" ;
VAL_ 1360 OBC_ChrgAllowedSts 1 "Allowed" 0 "NotAllowed" ;
VAL_ 392 DCDC_ErrorLevel 7 "Reserved" 6 "Reserved" 5 "Reserved" 4 "Reserved" 3 "三级故障" 2 "二级故障" 1 "一级故障" 0 "无故障" ;
VAL_ 392 DCDC_stMode 7 "Reserved" 6 "Reserved" 5 "Reserved" 4 "Failure" 3 "Discharge" 2 "Buck" 1 "Standby" 0 "Init" ;
VAL_ 392 DCDC_DischargeMode 3 "泄放失败" 2 "泄放完成" 1 "泄放中" 0 "未泄放" ;
VAL_ 905 DCDC_DeratingSts 1 "derating" 0 "normal" ;
VAL_ 1504 BMS_SWVersion_Supplier 10 "捷新/捷能" ;
VAL_ 1504 BMS_SWVersion_Main 3 "SOP" 2 "PVS-C样" 1 "PT-A/B样" ;
VAL_ 1504 BMS_HWVersion_Supplier 10 "捷新/捷能" ;
VAL_ 1504 BMS_HWVersion_Main 3 "SOP" 2 "PVS-C样" 1 "PT-A/B样" ;
VAL_ 1504 BMS_PackEnergy 77 "77kWh" 54 "54kWh" ;
VAL_ 1504 BMS_CellSupplier 17 "捷威" 16 "万向" ;
VAL_ 835 PLG_Trunk_Sts 7 "Latch cinching正在上锁" 6 "Latch releasing正在解锁" 5 "PLG stopped" 4 "Closing" 3 "Opening" 2 "Fully closed" 1 "Fully opened" 0 "PLG unknown" ;
VAL_ 835 PLG_Shutface_SW 1 "active导通" 0 "inactive断开" ;
VAL_ 835 PLG_Latc_PawlSW 1 "active尾门打开" 0 "inactive尾门关闭" ;
VAL_ 835 PLG_Latch_SecondarySW 1 "active导通" 0 "inactive断开" ;
VAL_ 835 PLG_Latch_0PositionSW 1 "active导通" 0 "inactive断开" ;
VAL_ 835 PLG_LearnedSts 1 "Learned" 0 "Unlearn" ;
VAL_ 835 PLG_KickActiveReq 1 "Request" 0 "NoRequest" ;
VAL_ 835 PLG_HallSensor 1 "NOK" 0 "OK" ;
VAL_ 835 PLG_OpenAngValid 1 "SignalInvalid" 0 "Signalvalid" ;
VAL_ 835 PLG_LatchMorSts 3 "SignalInvalid" 2 "ShortBattery" 1 "ShortGround" 0 "OK" ;
VAL_ 835 PLG_GearMor1Sts 3 "SignalInvalid" 2 "ShortBattery" 1 "ShortGround" 0 "OK" ;
VAL_ 835 PLG_GearMor2Sts 3 "SignalInvalid" 2 "ShortBattery" 1 "ShortGround" 0 "OK" ;
VAL_ 835 PLG_mode 3 "预留" 2 "手动模式（预留）" 1 "车库模式" 0 "正常模式" ;
VAL_ 835 PLG_TBOXUnlockEnableSts 1 "enable" 0 "disable" ;
VAL_ 835 PLG_Fault 1 "Fault" 0 "Default" ;
VAL_ 835 PLG_FaultSts 7 "Fault 7" 6 "Fault 6" 5 "Fault 5" 4 "Fault 4" 3 "Fault 3" 2 "Fault 2" 1 "Fault 1" 0 "Default" ;
VAL_ 528 ACU_CrashStatus 1 "crash" 0 "no crash" ;
VAL_ 528 ACU_AirBagFailSts 3 "Not Used" 2 "lamp flashing（ACU自检）" 1 "lamp on" 0 "lamp off" ;
VAL_ 528 ACU_SBR_Driver 3 "Reserved" 2 "flash and buzzing" 1 "lamp on" 0 "lamp off" ;
VAL_ 528 ACU_SBR_Passenger 3 "Reserved" 2 "flash and buzzing" 1 "lamp on" 0 "lamp off" ;
VAL_ 528 ACU_SBR_RLPassenger 3 "Reserved" 2 "Reserved" 1 "lamp on" 0 "lamp off" ;
VAL_ 528 ACU_SBR_MidPassenger 3 "Reserved" 2 "Reserved" 1 "lamp on" 0 "lamp off" ;
VAL_ 528 ACU_SBR_RRPassenger 3 "Reserved" 2 "Reserved" 1 "lamp on" 0 "lamp off" ;
VAL_ 528 ACU_DrvSeatBeltSWSts 1 "Buckle on" 0 "Buckle off" ;
VAL_ 528 ACU_PsSeatBeltSWSts 1 "Buckle on" 0 "Buckle off" ;
VAL_ 528 ACU_RLPsSeatBeltSWSts 1 "Buckle on" 0 "Buckle off" ;
VAL_ 528 ACU_MidPsSeatBeltSWSts 1 "Buckle on" 0 "Buckle off" ;
VAL_ 528 ACU_RRPsSeatBeltSWSts 1 "Buckle on" 0 "Buckle off" ;
VAL_ 596 AC_SystemSts 1 "ON" 0 "OFF" ;
VAL_ 596 AC_CycleSts 1 "外循环" 0 "内循环" ;
VAL_ 596 AC_EACSts 1 "ON" 0 "OFF" ;
VAL_ 596 AC_AutoModeSts 1 "on" 0 "off" ;
VAL_ 596 AC_APTC_StartStop 3 "Invalid" 2 "Stop" 1 "Start" 0 "Default" ;
VAL_ 596 AC_StartStopEAC 3 "Invalid" 2 "Stop" 1 "Start" 0 "Default" ;
VAL_ 596 AC_WindModeSts 7 "reserved" 6 "reserved" 5 "Blow defrost" 4 "Blow face" 3 "Blow foot&defrost1" 2 "Blow foot" 1 "Blow face&foot" 0 "default" ;
VAL_ 596 AC_BlowingRateSts 7 "Level7" 6 "Level6" 5 "Level5" 4 "Level4" 3 "Level3" 2 "Level2" 1 "Level1" 0 "关闭" ;
VAL_ 596 AC_APTCSWsts 1 "开" 0 "关" ;
VAL_ 596 AC_SysFaultsts 1 "故障" 0 "无故障" ;
VAL_ 596 AC_BatCoolingValve 1 "on" 0 "off" ;
VAL_ 596 AC_ComftCoolingValve 1 "on" 0 "off" ;
VAL_ 596 AC_FdefrostSts 1 "on" 0 "off" ;
VAL_ 1009 DVR_Sdcard_Sts 7 "Custom full（TF卡用户拍摄存储空间不足，请及时清理数据）" 6 "Emergency event full（TF卡紧急录像存储空间不足，请及时清理数据或打开紧急录像循环覆盖开关）" 5 "Full（TF卡可用空间不足，请及时清理数据）" 4 "Abnormal（TF卡异常，请格式化TF卡或者换新卡）" 3 "Capacity unsupported（TF卡容量不支持，请使用8~128GB容量范围的TF卡）" 2 "Filesystem unsupported（TF卡文件系统不支持，请格式化TF卡）" 1 "Not inserted（TF卡未插入，请插入TF卡）" 0 "Normal（TF卡正常）" ;
VAL_ 1009 DVR_DrivingRecord 1 "打开" 0 "关闭" ;
VAL_ 1009 DVR_VideoResolution 3 "保留" 2 "720P@30fps" 1 "1080P@30fps" 0 "保留" ;
VAL_ 1009 DVR_VideoTimeSts 3 "5分钟" 2 "3分钟" 1 "1分钟" 0 "保留" ;
VAL_ 1009 DVR_ShutdownDelay 3 "3分钟" 2 "1分钟" 1 "10秒" 0 "关闭" ;
VAL_ 1009 DVR_VideoCoverageSW 1 "覆盖" 0 "不覆盖" ;
VAL_ 1009 DVR_GSensorSensy 3 "高" 2 "中" 1 "低" 0 "保留" ;
VAL_ 1009 DVR_ParkMonitor 1 "开启" 0 "关闭" ;
VAL_ 1009 DVR_TapeSwitch 1 "开启" 0 "关闭" ;
VAL_ 1009 DVR_HDRSwitch 1 "开启" 0 "关闭" ;
VAL_ 1009 DVR_DriveInfoOverlay 1 "开启" 0 "关闭" ;
VAL_ 1009 DVR_SdcardFormateSts 3 "Reserved" 2 "Succeed" 1 "Fail" 0 "default" ;
VAL_ 1009 DVR_FactoryDefaultSts 3 "Reserved" 2 "Succeed" 1 "Fail" 0 "default" ;
VAL_ 1009 DVR_SystemSts 1 "设备异常" 0 "设备正常" ;
VAL_ 1009 DVR_ControlResult 3 "Remote photo take fai" 2 "Remote photo take succeed" 1 "Remote photo taking" 0 "Invalid" ;
VAL_ 1009 DVR_GsensorCrashStatus 1 "crash" 0 "no crash" ;
VAL_ 1009 DVR_requestWiFiopen 1 "request wifi open" 0 "deault" ;
VAL_ 1009 DVR_Network_Set 3 "Reversed" 2 "Off【DVR请求HU将Wi-Fi热点和移动数据（娱乐）流量恢复到自动打开前状态】" 1 "On【DVR请求HU自动打开Wi-Fi热点和移动数据（娱乐）流量】" 0 "default" ;
VAL_ 1009 DVR_LocalPhotographResult 3 "Photo take fail" 2 "Photo take succeed" 1 "Photo taking" 0 "Invalid" ;
VAL_ 1009 DVR_LocalRecordResult 3 "Record fail" 2 "Record succeed" 1 "Recording" 0 "Invalid" ;
VAL_ 1009 DVR_LocalTimelapseRecordResult 3 "Timelapse record fail" 2 "Timelapse record succeed" 1 "Timelapse recording" 0 "Invalid" ;
VAL_ 676 DSM_EasyEntrySWSts 1 "disable" 0 "enable" ;
VAL_ 676 DSM_DSMHeatSWsts 1 "enable" 0 "disable" ;
VAL_ 676 DSM_MemoryAlarm 3 "Reserved" 2 "successed" 1 "failed" 0 "default" ;
VAL_ 676 DSM_DeleteMemoryRsp 3 "预留" 2 "删除失败" 1 "删除成功" 0 "default" ;
VAL_ 676 DSM_GetMemoryRsp 3 "调节中止" 2 "调节失败" 1 "调节成功" 0 "Default" ;
VAL_ 676 DSM_DseatMemoryPosition 15 "reserved" 14 "reserved" 13 "reserved" 12 "reserved" 11 "Last position" 10 "10 Position" 9 "9 Position" 8 "8 Position" 7 "7 Position" 6 "6 Position" 5 "5 Position" 4 "4 Position" 3 "3 Position" 2 "2 Position" 1 "1 Position" 0 "Not_MemoryPosition" ;
VAL_ 676 DSM_SLV_DirectionSts 3 "Invalid" 2 "Back" 1 "Forward" 0 "Stop" ;
VAL_ 676 DSM_SHV_DirectionSts 3 "Invalid" 2 "Down" 1 "Up" 0 "Stop" ;
VAL_ 676 DSM_LNV_DirectionSts 3 "Invalid" 2 "Back" 1 "Forward" 0 "Stop" ;
VAL_ 676 DSM_SLV_CalibrationSts 3 "Reserved" 2 "Calibration complete" 1 "Calibration incomplete" 0 "Default" ;
VAL_ 676 DSM_SHV_CalibrationSts 3 "Reserved" 2 "Calibration complete" 1 "Calibration incomplete" 0 "Default" ;
VAL_ 676 DSM_LNV_CalibrationSts 3 "Reserved" 2 "Calibration complete" 1 "Calibration incomplete" 0 "Default" ;
VAL_ 676 DSM_DSLV_MotorfaultSts 1 "fault" 0 "no fault" ;
VAL_ 676 DSM_DSHV_MotorfaultSts 1 "fault" 0 "no fault" ;
VAL_ 676 DSM_DSNV_MotorfaultSts 1 "fault" 0 "no fault" ;
VAL_ 676 DSM_PSMHeatfault 1 "fault" 0 "no fault" ;
VAL_ 676 DSM_PSMHeatSWsts 1 "enable" 0 "disable" ;
VAL_ 676 DSM_DSMHeatfault 1 "fault" 0 "no fault" ;
VAL_ 256 BMS_WaringLevel 7 "预留" 6 "预留" 5 "预留" 4 "预留" 3 "三级告警" 2 "二级告警" 1 "一级告警" 0 "无告警" ;
VAL_ 256 BMS_RelayChrPos 3 "Debounce（预留）" 2 "Fault （故障)" 1 "Close（闭合）" 0 "Open （断开）" ;
VAL_ 256 BMS_RelayNeg 3 "Debounce（预留）" 2 "Fault （故障)" 1 "Close（闭合）" 0 "Open （断开）" ;
VAL_ 256 BMS_RelayPre 3 "Debounce（预留）" 2 "Fault （故障)" 1 "Close（闭合）" 0 "Open （断开）" ;
VAL_ 256 BMS_RelayPos 3 "Debounce（预留）" 2 "Fault （故障)" 1 "Close（闭合）" 0 "Open （断开）" ;
VAL_ 256 BMS_RelayChrNeg 3 "Debounce（预留）" 2 "Fault （故障)" 1 "Close（闭合）" 0 "Open （断开）" ;
VAL_ 256 BMS_State 15 "Error" 14 "预留" 13 "预留" 12 "预留" 11 "预留" 10 "预留" 9 "预留" 8 "预留" 7 "预留" 6 "AfterRun" 5 "Fast_Charging" 4 "Slow_Charging" 3 "DisCharging" 2 "Precharging" 1 "Standby" 0 "Initialazation" ;
VAL_ 256 BMS_ChrFastState 3 "充电故障" 2 "充电完成" 1 "充电中" 0 "未充电" ;
VAL_ 256 BMS_SPreCharging 3 "预充失败" 2 "预充完成" 1 "预充中" 0 "未预充" ;
VAL_ 256 BMS_ChrSlowState 3 "充电故障" 2 "充电完成" 1 "充电中" 0 "未充电" ;
VAL_ 258 BMS_WakeUpSignal 1 "KL15_ON" 0 "KL15_OFF" ;
VAL_ 258 BMS_BalanceSts 1 "电池开启" 0 "电池关闭" ;
VAL_ 258 BMS_HVIL1_State 3 "预留" 2 "断开" 1 "闭合" 0 "未检测" ;
VAL_ 258 BMS_HVIL2_State 3 "预留" 2 "断开" 1 "闭合" 0 "未检测" ;
VAL_ 278 BMS_CellOverVolWaring 3 "三级故障" 2 "二级故障" 1 "一级故障" 0 "Not fault" ;
VAL_ 278 BMS_CellUnderVolWaring 3 "三级故障" 2 "二级故障" 1 "一级故障" 0 "Not fault" ;
VAL_ 278 BMS_TempOverWaring 3 "三级故障" 2 "二级故障" 1 "一级故障" 0 "Not fault" ;
VAL_ 278 BMS_TempUnderWaring 3 "三级故障" 2 "二级故障" 1 "一级故障" 0 "Not fault" ;
VAL_ 278 BMS_CellVolDevWaring 3 "三级故障" 2 "二级故障" 1 "一级故障" 0 "Not fault" ;
VAL_ 278 BMS_TempDveWaring 3 "三级故障" 2 "二级故障" 1 "一级故障" 0 "Not fault" ;
VAL_ 278 BMS_BattOverVolWaring 3 "三级故障" 2 "二级故障" 1 "一级故障" 0 "Not fault" ;
VAL_ 278 BMS_BattUnderVolWaring 3 "三级故障" 2 "二级故障" 1 "一级故障" 0 "Not fault" ;
VAL_ 278 BMS_DCChargePlugTempOverHigh 1 "故障" 0 "正常" ;
VAL_ 278 BMS_DisCharOverCurr 3 "三级故障" 2 "二级故障" 1 "一级故障" 0 "Not fault" ;
VAL_ 278 BMS_RegenOverCurr 3 "三级故障" 2 "二级故障" 1 "一级故障" 0 "Not fault" ;
VAL_ 278 BMS_InnerCANTimeout 1 "故障" 0 "正常" ;
VAL_ 278 BMS_ISOWaring 3 "三级故障" 2 "二级故障" 1 "一级故障" 0 "Not fault" ;
VAL_ 278 BMS_BCUHWFault 1 "故障" 0 "正常" ;
VAL_ 278 BMS_NegRelayFault 3 "预留" 2 "断开" 1 "黏连" 0 "正常" ;
VAL_ 278 BMS_PosRelayFault 3 "预留" 2 "断开" 1 "黏连" 0 "正常" ;
VAL_ 278 BMS_PreRelayFault 3 "预留" 2 "断开" 1 "黏连" 0 "正常" ;
VAL_ 278 BMS_LowVoltageMSD 1 "断开" 0 "正常" ;
VAL_ 278 BMS_CharPosRelayFault 3 "预留" 2 "断开" 1 "黏连" 0 "正常" ;
VAL_ 278 BMS_CharNegRelayFault 3 "预留" 2 "断开" 1 "黏连" 0 "正常" ;
VAL_ 278 BMS_BMUFault 1 "故障" 0 "正常" ;
VAL_ 278 BMS_VcuCANTimeout 1 "故障" 0 "正常" ;
VAL_ 278 BMS_BattHVDisaccord 1 "故障" 0 "正常" ;
VAL_ 278 BMS_PressureSensorFault 1 "故障" 0 "正常" ;
VAL_ 278 BMS_SOClow 3 "三级故障" 2 "二级故障" 1 "一级故障" 0 "Not fault" ;
VAL_ 278 BMS_Mismatch 1 "Mismatch" 0 "Match" ;
VAL_ 278 BMS_SOCOverHigh 1 "SOC过高" 0 "SOC正常" ;
VAL_ 278 BMS_BattOverCharge 1 "动力电池过充" 0 "正常" ;
VAL_ 278 BMS_SOCSkip 1 "SOC跳变报警" 0 "正常" ;
VAL_ 278 BMS_FCGOverCurr 1 "过流" 0 "正常" ;
VAL_ 278 BMS_SCGOverCurr 1 "过流" 0 "正常" ;
VAL_ 278 BMS_LiquidLeak 1 "漏液" 0 "正常" ;
VAL_ 278 BMS_CrashFault 1 "碰撞" 0 "正常" ;
VAL_ 278 BMS_ThermRunAway 1 "热失控" 0 "正常" ;
VAL_ 278 BMS_Maintenance 3 "预留" 2 "预留" 1 "电池保养" 0 "正常" ;
VAL_ 278 BMS_BusbarTempOverWaring 1 "过温" 0 "正常" ;
VAL_ 278 BMS_FuseFault 1 "故障" 0 "正常" ;
VAL_ 278 BMS_CurrSensorFault 3 "三级故障" 2 "二级故障" 1 "一级故障" 0 "Not fault" ;
VAL_ 288 MCU_MotorActualTorque 32767 "Failure" 32766 "Init" ;
VAL_ 288 MCU_MotorSpeed 65535 "Failure" 65534 "Init" ;
VAL_ 288 MCU_AuthSts 3 "Reserved" 2 "Auth Pass" 1 "Auth Not Pass" 0 "Init(认证正在进行）" ;
VAL_ 288 MCU_OverSpdWarning 1 "Warning" 0 "Not Warning" ;
VAL_ 288 MCU_InverterTempWarning 1 "Warning" 0 "Not Warning" ;
VAL_ 288 MCU_MotorTempWarning 1 "Warning" 0 "Not Warning" ;
VAL_ 288 MCU_OverTemp 1 "MCU请求点亮电机过热灯" 0 "MCU无点亮电机过热灯请求" ;
VAL_ 288 MCU_WorkSts 15 "Invalid" 11 "HillHold" 10 "DisCharge" 7 "Failure" 6 "Afterrun" 5 "TrqCtl" 4 "nCtlInt" 3 "alOffsetCal" 2 "Standby" 1 "PreCharge" 0 "DrvInit" ;
VAL_ 288 MCU_FaultLevel 7 "Reserved" 6 "Reserved" 5 "Reserved" 4 "Level-4 error" 3 "Level-3 error(High)" 2 "Level-2 error(Limited Drive)" 1 "Level-1 error(Low)" 0 "No Error" ;
VAL_ 288 MCU_FaultLampOn 1 "MCU请求点亮电机故障灯" 0 "MCU无点亮电机故障灯请求" ;
VAL_ 288 MCU_HVLock 3 "预留" 2 "高压断开" 1 "高压闭合" 0 "未检测" ;
VAL_ 290 MCU_MaxAvailableTorque 2047 "Failure" 2046 "Init" ;
VAL_ 290 MCU_MinAvailableTorque 2047 "Failure" 2046 "Init" ;
VAL_ 290 MCU_DeratingTempCoolant 1 "Derating" 0 "Not Derating" ;
VAL_ 290 MCU_damping_En 1 "active" 0 "Not active" ;
VAL_ 290 MCU_DeratingTrqMin 1 "Derating" 0 "Not Derating" ;
VAL_ 290 MCU_DeratingTrqMax 1 "Derating" 0 "Not Derating" ;
VAL_ 290 MCU_DeratingOvrUdc 1 "Derating" 0 "Not Derating" ;
VAL_ 290 MCU_DeratingUndrUdc 1 "Derating" 0 "Not Derating" ;
VAL_ 290 MCU_DeratingOvrIdc 1 "Derating" 0 "Not Derating" ;
VAL_ 290 MCU_DeratingUndrIdc 1 "Derating" 0 "Not Derating" ;
VAL_ 290 MCU_DeratingTempEm 1 "Derating" 0 "Not Derating" ;
VAL_ 290 MCU_DeratingTempInv 1 "Derating" 0 "Not Derating" ;
VAL_ 290 MCU_MotorTorqueDeratingFlg 1 "derating" 0 "Not derating" ;
VAL_ 290 MCU_HVReady 1 "HV Ready" 0 "HV not Ready" ;
VAL_ 290 MCU_DeratingOverSpd 1 "Derating" 0 "Not Derating" ;
VAL_ 289 ESP_VehicleSpeed_Valid 1 "Invalid" 0 "Valid" ;
VAL_ 289 ESP_OFF 1 "On" 0 "Off" ;
VAL_ 289 ESP_ABS_Error 1 "Failure" 0 "No failure" ;
VAL_ 289 ESP_ABS_Intervention 1 "Active" 0 "Not active" ;
VAL_ 289 ESP_VDC_TCS_Error 1 "On" 0 "Off" ;
VAL_ 289 ESP_EBD_Error 1 "On" 0 "Off" ;
VAL_ 289 ESP_VDC_Intervention 1 "Active" 0 "Not active" ;
VAL_ 289 ESP_TCS_Intervention 1 "Active" 0 "Not active" ;
VAL_ 289 ESP_EBD_Intervention 1 "Active" 0 "Not active" ;
VAL_ 289 ESP_HDC_Status 3 "Reserved" 2 "On active braking" 1 "On not active braking" 0 "OFF" ;
VAL_ 289 ESP_HDC_Available 1 "Available" 0 "Not available" ;
VAL_ 289 ESP_EPBMainteDiagmodeActive 1 "Active" 0 "Not active" ;
VAL_ 289 ESP_EPBFailstatus 1 "error in EPB" 0 "No error" ;
VAL_ 289 ESP_EPBStatus 7 ":Reserved" 6 ":Reserved" 5 ":Reserved" 4 "Locking（卡钳正处于夹紧过程中" 3 "Releasing（卡钳正处于释放过程中）" 2 "Closed（卡钳处于夹紧状态）" 1 "Released（卡钳处于释放状态）" 0 "Undefined（未定义）" ;
VAL_ 289 ESP_VehicleStop 1 "2 or more wheels are standstill" 0 "Vehicle is not standstill" ;
VAL_ 289 ESP_VehicleStop_Valid 1 "Valid" 0 "Invalid" ;
VAL_ 289 ESP_MasterCyPressure_Valid 1 "Valid" 0 "Invalid" ;
VAL_ 289 ESP_WheelCyBrakeForce_Exist 1 "brake force exists" 0 "No brake force" ;
VAL_ 289 ESP_ESPLamp 1 "On（ESP Active）" 0 "Off（ESP Inactive）" ;
VAL_ 289 ESP_AVHstandbyStatus 1 "Standby" 0 "Not standby" ;
VAL_ 289 ESP_AVHActive 1 "Active" 0 "Not active" ;
VAL_ 289 ESP_AVH_availalbe 1 "Available" 0 "Not available" ;
VAL_ 289 ESP_HHC_Available 1 "Available" 0 "Not available" ;
VAL_ 289 ESP_HHCActive 1 "Active" 0 "Not active" ;
VAL_ 289 ESP_HubDiagmodeActive 1 "Active" 0 "Not active" ;
VAL_ 289 ESP_HAZ_Active 1 "Active" 0 "Not active" ;
VAL_ 289 ESP_MILLampRequest 1 "Request lamp ON" 0 "No request" ;
VAL_ 291 MCU_DC_linkVoltage 1023 "Failure" 1022 "Init" ;
VAL_ 291 MCU_DC_linkCurrent 2047 "Failure" 2046 "Init" ;
VAL_ 291 MCU_InverterTemp 255 "Failure" 254 "Init" ;
VAL_ 291 MCU_MotorTemp 255 "Failure" 254 "Init" ;
VAL_ 291 MCU_WaterTemp 255 "Failure" 254 "Init" ;
VAL_ 292 MCU_DBCTempU 255 "Failure" 0 "Init" ;
VAL_ 292 MCU_DBCTempV 255 "Failure" 0 "Init" ;
VAL_ 292 MCU_DBCTempW 255 "Failure" 0 "Init" ;
VAL_ 292 MCU_RotorTemp 255 "Failure" 254 "Init" ;
VAL_ 292 MCU_MotoroffsetSts 3 "reserved" 2 "Offset_Not_Accurate" 1 "Offset_Accurate" 0 "Init" ;
VAL_ 292 MCU_stGateDrv 3 "DisCharge" 2 "PWMrun" 1 "FreeWheel" 0 "ShortCircuit" ;
VAL_ 292 MCU_Motoroffset 1023 "Failure" 1022 "Init" ;
VAL_ 545 TBOX_BT_Key_valid 3 "预留" 2 "蓝牙已连接" 1 "预留" 0 "蓝牙未连接" ;
VAL_ 545 TBOX_WorkModeCMD 3 "故障" 2 "远程诊断" 1 "远程控制" 0 "默认" ;
VAL_ 545 TBOX_Locate_F 1 "Fault" 0 "No fault" ;
VAL_ 545 TBOX_Networking_F 1 "Fault" 0 "No fault" ;
VAL_ 545 TBOX_Memory_F 1 "Fault" 0 "No fault" ;
VAL_ 545 TBOX_WelcomefuncReq 1 "Request" 0 "Default" ;
VAL_ 545 TBOX_Timer_out 1 "active" 0 "inactive" ;
VAL_ 545 TBOX_FOTA_mode_ALL 7 "Reserved" 6 "Reserved" 5 "Reserved" 4 "到店升级 默认亮屏" 3 "静默升级 屏幕亮度0" 2 "强制升级 默认亮屏" 1 "标准升级 默认亮屏" 0 "default" ;
VAL_ 545 TBOX_RemoteCharge_EndHour 31 "Invalid" 30 "Invalid" 29 "Invalid" 28 "Invalid" 27 "Invalid" 26 "Invalid" 25 "Invalid" 24 "Invalid" ;
VAL_ 545 TBOX_RemotCh_Full_SetSts 1 "充满" 0 "不充满" ;
VAL_ 545 TBOX_RemoteCharge_Endmin 63 "Invalid" 62 "Invalid" 61 "Invalid" 60 "Invalid" ;
VAL_ 599 AC_RemoteAC 7 "reserved" 6 "reserved" 5 "reserved" 4 "RemotDefrost" 3 "RemoteHot" 2 "RemoteCool:" 1 "RemoteVentilation" 0 "NoRequest:" ;
VAL_ 599 AC_RemoteACFeedback 11 "预留4" 10 "预留3" 9 "预留2" 8 "空调系统故障" 7 "启动太频繁" 6 "空调开启最大时间到" 5 "功率低:" 4 "SOC过低" 3 "高压系统故障:" 2 "本地状态" 1 "正在远程空调" 0 "未开启" ;
VAL_ 849 TBOX_BCM_DoorLock_Control_4G 3 "Lock" 2 "FourDoor UnLock" 1 "DiverDoor UnLock" 0 "Default" ;
VAL_ 849 TBOX_BCM_CarLocating 7 "Invalid" 6 "reserved" 5 "reserved" 4 "关闭" 3 "双闪和鸣笛" 2 "鸣笛" 1 "双闪" 0 "Default" ;
VAL_ 849 TBOX_PLG_TrunkunLock 3 "Invalid" 2 "Lock" 1 "UnLock" 0 "Default" ;
VAL_ 849 TBOX_DSM_heatSwitch 3 "Invalid" 2 "Close" 1 "Open" 0 "Default" ;
VAL_ 849 TBOX_PSM_heatSwitch 3 "Invalid" 2 "Close" 1 "Open" 0 "Default" ;
VAL_ 849 TBOX_DSM_GetMemoryReq 15 "Reserved" 14 "Reserved" 13 "Reserved" 12 "Stop Move" 11 "Last position" 10 "10 Position(对应ID10)" 9 "9 Position(对应ID9)" 8 "8 Position(对应ID8)" 7 "7 Position(对应ID7)" 6 "6 Position(对应ID6)" 5 "5 Position(对应ID5)" 4 "4 Position (对应ID4)" 3 "3 Position  (对应ID3)" 2 "2 Position(对应ID2)" 1 "1 Position (对应ID1)" 0 "No request" ;
VAL_ 849 TBOX_BCM_DoorLock_Control_BT 3 "Lock" 2 "FourDoor UnLock" 1 "DiverDoor UnLock" 0 "Default" ;
VAL_ 849 TBOX_DSM_Targtemp 63 "defauit" ;
VAL_ 849 TBOX_welcomefuncReqsts 1 "disable" 0 "enable" ;
VAL_ 849 TBOX_Publish_Wakeup 1 "active" 0 "inactive" ;
VAL_ 849 TBOX_PSM_Targtemp 63 "defauit" ;
VAL_ 849 TBOX_BCM_selflearn_MD1 1 "active-MD1 initialization run" 0 "deactive/无动作" ;
VAL_ 849 TBOX_BCM_selflearn_Mrollo 1 "active-MR initialization run" 0 "deactive/无动作" ;
VAL_ 849 TBOX_BCM_forceclose_MD1 1 "active" 0 "deactive/无动作" ;
VAL_ 849 TBOX_BCM_forceclose_Mrollo 1 "active" 0 "deactive/无动作" ;
VAL_ 849 TBOX_BCM_stopsunroof 1 "stop" 0 "deactive/无动作" ;
VAL_ 849 TBOX_BCM_PowerON_Request 3 "strat request" 2 "reserved" 1 "resverd" 0 "Default" ;
VAL_ 849 TBOX_BCM_PowerON_limit 1 "Active" 0 "Not active" ;
VAL_ 849 TBOX_BCM_SrfSlidePosReq 254 "默认值" 101 "玻璃板起翘" 100 "玻璃板开度100%" 0 "玻璃板开度0%" ;
VAL_ 849 TBOX_BCM_ShadeSlidePosReq 254 "默认值" 100 "遮阳帘开度100%" 0 "遮阳帘开度0%" ;
VAL_ 849 TBOX_BCM_FLWindowsControl 3 "Stop" 2 "AutoDown" 1 "AutoUP" 0 "Default" ;
VAL_ 849 TBOX_BCM_FRWindowsControl 3 "Stop" 2 "AutoDown" 1 "AutoUP" 0 "Default" ;
VAL_ 849 TBOX_BCM_RLWindowsControl 3 "Stop" 2 "AutoDown" 1 "AutoUP" 0 "Default" ;
VAL_ 849 TBOX_BCM_RRWindowsControl 3 "Stop" 2 "AutoDown" 1 "AutoUP" 0 "Default" ;
VAL_ 850 TBOX_AC_SystemSet 3 "Reserved" 2 "on" 1 "off" 0 "Default" ;
VAL_ 850 TBOX_AC_Cycle 3 "Reserved" 2 "外循环" 1 "内循环" 0 "Default" ;
VAL_ 850 TBOX_AC_EAC_Control 3 "Reserved" 2 "on" 1 "off" 0 "Default" ;
VAL_ 850 TBOX_AC_AutoMode_Set 3 "Reserved" 2 "off" 1 "on" 0 "Default" ;
VAL_ 850 TBOX_AC_WindMode_Set 7 "Reserved" 6 "Reserved" 5 "Fdefrost" 4 "Blow face" 3 "Blow foot&defrost" 2 "Blow foot" 1 "Blow face&foot" 0 "Default" ;
VAL_ 850 TBOX_AC_BlowingRate_Set 7 "Level7" 6 "Level6" 5 "Level5" 4 "Level4" 3 "Level3" 2 "Level2" 1 "Level1" 0 "Default" ;
VAL_ 850 TBOX_AC_APTCSW_Set 3 "Reserved" 2 "开" 1 "关" 0 "Default" ;
VAL_ 850 TBOX_HU_rebootACK 1 "ACK" 0 "default" ;
VAL_ 850 TBOX_RemotePhotograph 3 "take photos in and outcar" 2 "take photos out-car" 1 "take photos in-car" 0 "Default" ;
VAL_ 850 TBOX_PLG_OpenControl 3 "Reserved" 2 "Close" 1 "Open" 0 "Default" ;
VAL_ 850 TBOX_RemoteCharge_Setsts 1 "开启定时充电模式" 0 "取消定时充电模式" ;
VAL_ 850 TBOX_ChargeCtrl_Setsts 1 "定时充电" 0 "立即充电" ;
VAL_ 850 TBOX_BCM_FLWindowsVoiControl 15 "预留" 14 "预留" 13 "预留" 12 "车窗停止动作" 11 "关闭车窗" 10 "100%全开" 9 "90%开度" 8 "80%开度" 7 "70%开度" 6 "60%开度" 5 "50%开度" 4 "40%开度" 3 "30%开度" 2 "20%开度" 1 "10%开度" 0 "Default" ;
VAL_ 850 TBOX_BCM_FRWindowsVoiControl 15 "预留" 14 "预留" 13 "预留" 12 "车窗停止动作" 11 "关闭车窗" 10 "100%全开" 9 "90%开度" 8 "80%开度" 7 "70%开度" 6 "60%开度" 5 "50%开度" 4 "40%开度" 3 "30%开度" 2 "20%开度" 1 "10%开度" 0 "Default" ;
VAL_ 850 TBOX_BCM_RLWindowsVoiControl 15 "预留" 14 "预留" 13 "预留" 12 "车窗停止动作" 11 "关闭车窗" 10 "100%全开" 9 "90%开度" 8 "80%开度" 7 "70%开度" 6 "60%开度" 5 "50%开度" 4 "40%开度" 3 "30%开度" 2 "20%开度" 1 "10%开度" 0 "Default" ;
VAL_ 850 TBOX_BCM_RRWindowsVoiControl 15 "预留" 14 "预留" 13 "预留" 12 "车窗停止动作" 11 "关闭车窗" 10 "100%全开" 9 "90%开度" 8 "80%开度" 7 "70%开度" 6 "60%开度" 5 "50%开度" 4 "40%开度" 3 "30%开度" 2 "20%开度" 1 "10%开度" 0 "Default" ;
VAL_ 851 TBOX_VCU_12vChargeReq 1 "Active" 0 "Not active" ;
VAL_ 851 TBOX_VCU_TimeCharge 3 "充电预约已到结束" 2 "充电预约未到结束" 1 "start" 0 "No request" ;
VAL_ 851 TBOX_BTKey_valid 1 "蓝牙已连接可用" 0 "蓝牙未连接不可用" ;
VAL_ 851 TBOX_ChargeDepthSet 3 "预留" 2 "长途旅行" 1 "日常行驶" 0 "default" ;
VAL_ 851 TBOX_APS_EPSStrgWhlAngZero 1 "回正" 0 "default" ;
VAL_ 851 TBOX_APS_RequstRemoteParkOut 1 "Request" 0 "NoRequest" ;
VAL_ 851 TBOX_APS_StartRemoteParkOut 1 "press" 0 "nopress" ;
VAL_ 851 TBOX_APS_RequstRemoteParkIn 1 "Request" 0 "NoRequest" ;
VAL_ 851 TBOX_APS_StartRemoteParkIn 1 "press" 0 "nopress" ;
VAL_ 851 TBOX_APS_PoewerOff_Request 3 "Resvered" 2 "PowerOffReqiest" 1 "NoPowerOffReqiest" 0 "Default" ;
VAL_ 851 TBOX_APS_StraightOut_Request1 3 "Undo 松开停止转向" 2 "Right 右转" 1 "Left 左转" 0 "Default" ;
VAL_ 851 TBOX_APS_StraightOut_Request2 3 "STOP   松开停止驱动" 2 "后退" 1 "前进" 0 "Default" ;
VAL_ 851 TBOX_APS_PowerON_Request 3 "strat request" 2 "reserved" 1 "resverd" 0 "Default" ;
VAL_ 851 TBOX_VCU_RemoteChrgLock 1 "unlock" 0 "no request" ;
VAL_ 851 TBOX_FOTA_mode 1 "FOTA非 PT CAN节点" 0 "Default" ;
VAL_ 851 TBOX_FOTA_wakeup 7 "Reserved" 6 "Reserved" 5 "Reserved" 4 "到店升级 默认亮屏" 3 "静默升级 屏幕亮度0" 2 "强制升级 默认亮屏" 1 "标准升级 默认亮屏" 0 "default" ;
VAL_ 853 TBOX_TimeSyncSts 1 "start  sync" 0 "Default" ;
VAL_ 1026 TBOX_NM_ALIVE 1 "Active" 0 "Not active" ;
VAL_ 1026 TBOX_NM_RING 1 "Active" 0 "Not active" ;
VAL_ 1026 TBOX_NM_LIMPHOME 1 "Active" 0 "Not active" ;
VAL_ 1026 TBOX_NM_SLEEP_INDICATION 1 "Active" 0 "Not active" ;
VAL_ 1026 TBOX_NM_SLEEP_ACK 1 "Active" 0 "Not active" ;
VAL_ 1028 GW_Tbox_NM_ALIVE 1 "Active" 0 "Not active" ;
VAL_ 1028 GW_Tbox_NM_RING 1 "Active" 0 "Not active" ;
VAL_ 1028 GW_Tbox_NM_LIMPHOME 1 "Active" 0 "Not active" ;
VAL_ 1028 GW_Tbox_NM_SLEEP_Ind 1 "Active" 0 "Not active" ;
VAL_ 1028 GW_Tbox_NM_SLEEP_ACK 1 "Active" 0 "Not active" ;
VAL_ 1299 BMS_MaxTemp 254 "invalid" ;
VAL_ 1299 BMS_MinTemp 254 "invalid" ;
VAL_ 1299 BMS_BattTempDev 254 "invalid" ;
VAL_ 1299 BMS_CCTemp1 254 "invalid" ;
VAL_ 1299 BMS_CCTemp2 254 "invalid" ;
